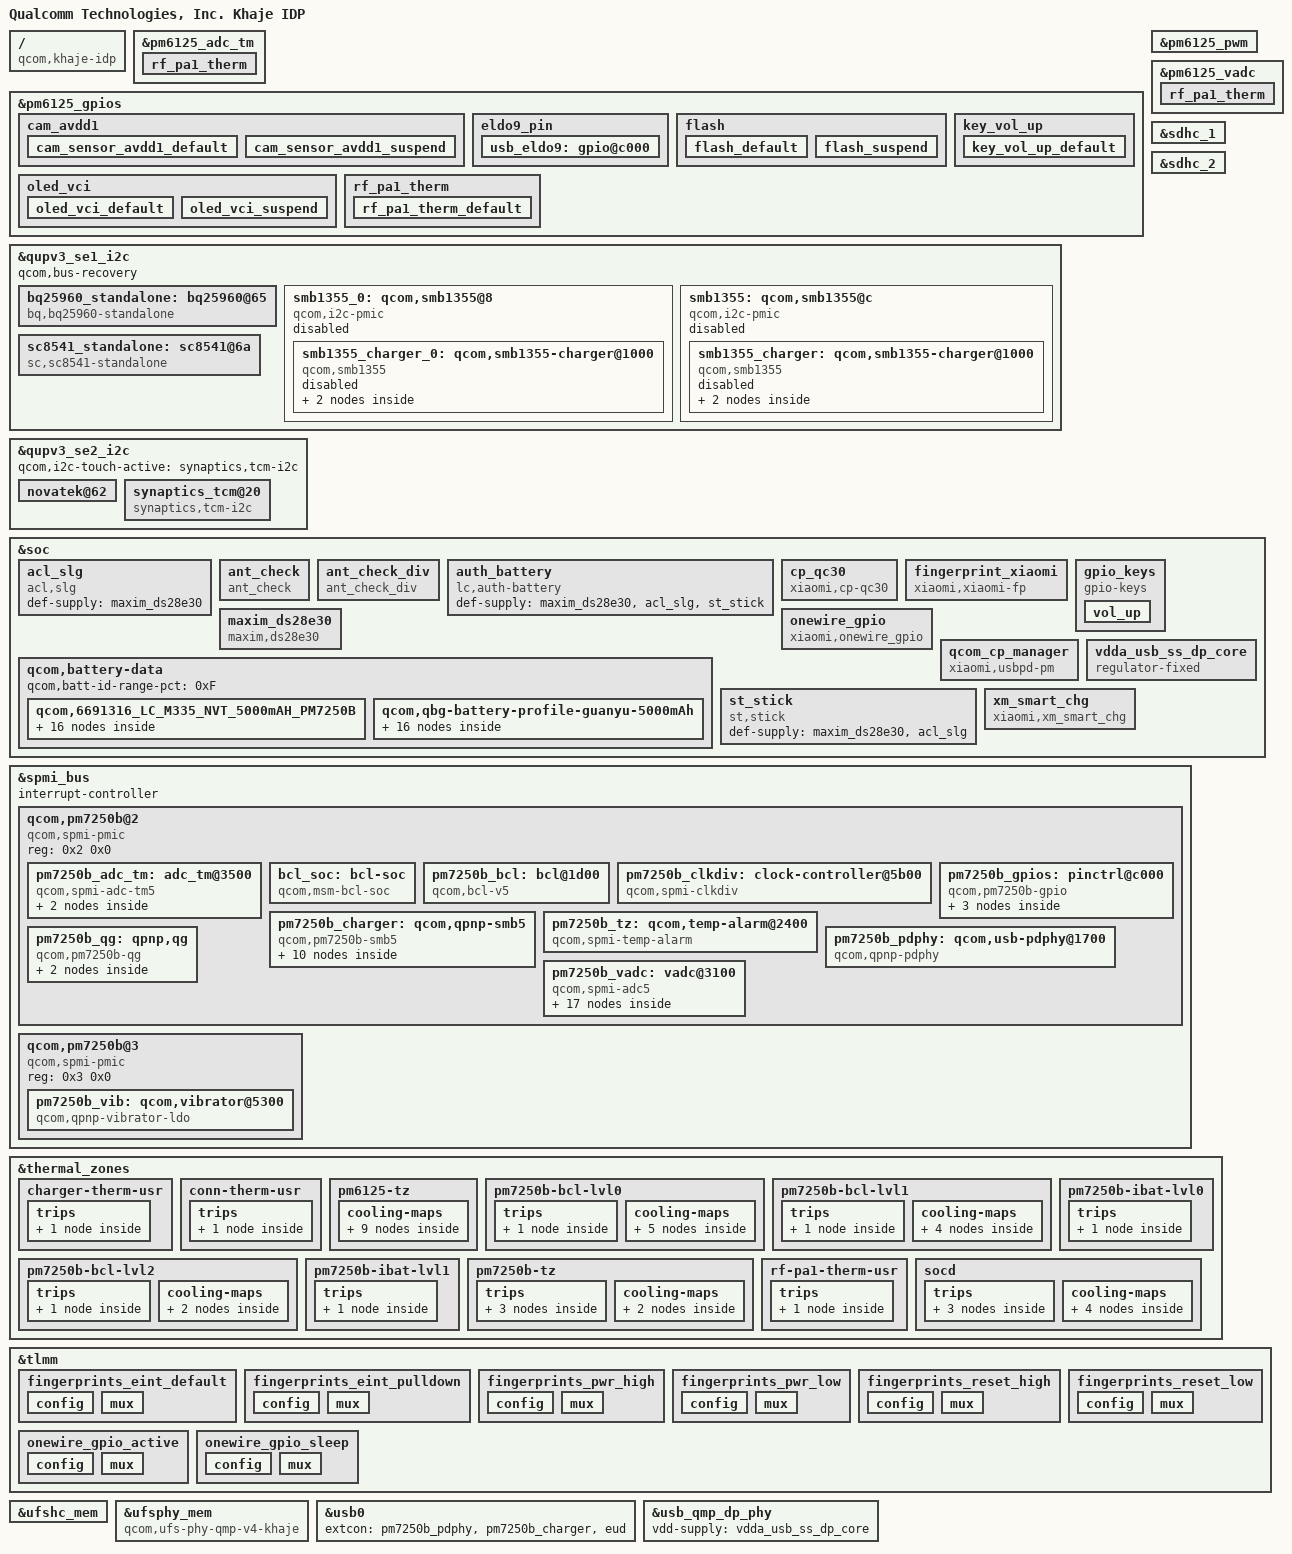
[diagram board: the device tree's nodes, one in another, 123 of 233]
/dts-v1/;

/ {
    compatible = "qcom,khaje-idp", "qcom,khaje", "qcom,idp";
    model = "Qualcomm Technologies, Inc. Khaje IDP";
    qcom,board-id = <0x10022 0x0>;
    qcom,msm-id = <0x231 0x10000>;
    qcom,pmic-id = <0x2D 0x2E 0x0 0x0>;
};

&pm6125_adc_tm {
    status = "ok";
    rf_pa1_therm {
        io-channels = <&pm6125_vadc 0x55>;
        qcom,hw-settle-time-us = <0xC8>;
        qcom,ratiometric;
        reg = <0x3>;
    };
};

&pm6125_gpios {
    cam_avdd1 {
        cam_sensor_avdd1_default: cam_sensor_avdd1_default {
            bias-disable;
            function = "normal";
            pins = "gpio2";
            power-source = <0x0>;
            qcom,drive-strength = <0x2>;
        };
        cam_sensor_avdd1_suspend: cam_sensor_avdd1_suspend {
            bias-disable;
            function = "normal";
            output-low;
            pins = "gpio2";
            power-source = <0x0>;
            qcom,drive-strength = <0x2>;
        };
    };
    eldo9_pin {
        usb_eldo9: gpio@c000 {
            bias-disable;
            function = "normal";
            output-high;
            pins = "gpio1";
            power-source = <0x0>;
            qcom,drive-strength = <0x2>;
        };
    };
    flash {
        flash_default: flash_default {
            bias-pull-up;
            function = "normal";
            output-high;
            pins = "gpio8";
            power-source = <0x1>;
            qcom,drive-strength = <0x2>;
        };
        flash_suspend: flash_suspend {
            bias-disable;
            function = "normal";
            output-low;
            pins = "gpio8";
            power-source = <0x1>;
            qcom,drive-strength = <0x2>;
        };
    };
    key_vol_up {
        key_vol_up_default: key_vol_up_default {
            bias-pull-up;
            function = "normal";
            input-enable;
            pins = "gpio5";
            power-source = <0x0>;
        };
    };
    oled_vci {
        oled_vci_default: oled_vci_default {
            bias-disable;
            function = "normal";
            input-disable;
            output-high;
            pins = "gpio9";
            power-source = <0x0>;
            qcom,drive-strength = <0x2>;
        };
        oled_vci_suspend: oled_vci_suspend {
            bias-disable;
            function = "normal";
            input-disable;
            output-low;
            pins = "gpio9";
            power-source = <0x0>;
            qcom,drive-strength = <0x2>;
        };
    };
    rf_pa1_therm {
        rf_pa1_therm_default: rf_pa1_therm_default {
            bias-high-impedance;
            pins = "gpio7";
        };
    };
};

&pm6125_pwm {
    status = "ok";
};

&pm6125_vadc {
    pinctrl-0 = <&camera_therm_default &emmc_therm_default &rf_pa1_therm_default>;
    rf_pa1_therm {
        label = "rf_pa1_therm";
        qcom,hw-settle-time = <0xC8>;
        qcom,pre-scaling = <0x1 0x1>;
        qcom,ratiometric;
        reg = <0x55>;
    };
};

&qupv3_se1_i2c {
    qcom,bus-recovery;
    status = "ok";
    bq25960_standalone: bq25960@65 {
        #io-channel-cells = <0x1>;
        bq,bq25960,chg-config-2 = <0x0>;
        bq,bq25960,fsw-set = <0x4>;
        bq,bq25960,ibat-ocp = <0x3D>;
        bq,bq25960,ibat-ocp-alm = <0x3D>;
        bq,bq25960,ibat-ocp-alm-dis = <0x1>;
        bq,bq25960,ibat-ocp-dis = <0x0>;
        bq,bq25960,ibat-sns-r = <0x0>;
        bq,bq25960,ibus-ocp = <0xD>;
        bq,bq25960,ibus-ucp = <0x0>;
        bq,bq25960,ibus-ucp-dis = <0x0>;
        bq,bq25960,ibus-ucp-fall-dg = <0x1>;
        bq,bq25960,ms = <0x0>;
        bq,bq25960,ss-timeout = <0x5>;
        bq,bq25960,tdie-alm = <0xC8>;
        bq,bq25960,tsbat-flt = <0x15>;
        bq,bq25960,tsbat-flt-dis = <0x1>;
        bq,bq25960,tsbus-flt = <0x15>;
        bq,bq25960,tsbus-flt-dis = <0x1>;
        bq,bq25960,vac1-ovp = <0x3>;
        bq,bq25960,vac1-pd-en = <0x0>;
        bq,bq25960,vac2-ovp = <0x3>;
        bq,bq25960,vac2-pd-en = <0x0>;
        bq,bq25960,vbat-ovp = <0x7F>;
        bq,bq25960,vbat-ovp-alm = <0x7A>;
        bq,bq25960,vbat-ovp-alm-dis = <0x1>;
        bq,bq25960,vbat-ovp-dis = <0x0>;
        bq,bq25960,vbus-ovp = <0x64>;
        bq,bq25960,vbus-ovp-alm = <0x64>;
        bq,bq25960,vbus-ovp-alm-dis = <0x0>;
        bq,bq25960,vbus-pd-en = <0x0>;
        bq,bq25960,vout-ovp = <0x3>;
        bq,bq25960,vout-ovp-dis = <0x0>;
        bq,bq25960,wd-timeout = <0x0>;
        bq,bq25960,wd-timeout-dis = <0x1>;
        bq25960,intr_gpio = <&tlmm 0x54 0x0>;
        charger_name = "primary_dvchg";
        compatible = "bq,bq25960-standalone";
        dep-supply = <&qupv3_se1_i2c>;
        reg = <0x65>;
        status = "ok";
    };
    smb1355_0: qcom,smb1355@8 {
        #address-cells = <0x1>;
        #interrupt-cells = <0x3>;
        #size-cells = <0x0>;
        compatible = "qcom,i2c-pmic";
        interrupt-controller;
        interrupt-parent = <&spmi_bus>;
        interrupt_names = "smb1355_0";
        interrupts = <0x0 0xD1 0x0 0x8>;
        qcom,periph-map = <0x10 0x12 0x13 0x16>;
        reg = <0x8>;
        status = "disabled";
        smb1355_charger_0: qcom,smb1355-charger@1000 {
            #address-cells = <0x1>;
            #size-cells = <0x1>;
            compatible = "qcom,smb1355";
            interrupt-parent = <&smb1355_0>;
            reg = <0x1000>;
            status = "disabled";
            qcom,chgr-misc@1600 {
                interrupt-names = "wdog-bark", "temperature-change";
                interrupts = <0x16 0x1 0x1 0x16 0x6 0x1>;
                reg = <0x1600>;
            };
            qcom,chgr@1000 {
                interrupt-names = "chg-state-change";
                interrupts = <0x10 0x1 0x1>;
                reg = <0x1000>;
            };
        };
    };
    smb1355: qcom,smb1355@c {
        #address-cells = <0x1>;
        #interrupt-cells = <0x3>;
        #size-cells = <0x0>;
        compatible = "qcom,i2c-pmic";
        interrupt-controller;
        interrupt-parent = <&spmi_bus>;
        interrupt_names = "smb1355";
        interrupts = <0x2 0xC5 0x0 0x8>;
        pinctrl-0 = <&pm7250b_smb_int_default>;
        pinctrl-names = "default";
        qcom,periph-map = <0x10 0x12 0x13 0x16>;
        reg = <0xC>;
        status = "disabled";
        smb1355_charger: qcom,smb1355-charger@1000 {
            #address-cells = <0x1>;
            #size-cells = <0x1>;
            compatible = "qcom,smb1355";
            interrupt-parent = <&smb1355>;
            qcom,hw-die-temp-mitigation;
            qcom,parallel-mode = <0x1>;
            reg = <0x1000>;
            status = "disabled";
            qcom,chgr-misc@1600 {
                interrupt-names = "wdog-bark", "temperature-change";
                interrupts = <0x16 0x1 0x1 0x16 0x6 0x1>;
                reg = <0x1600>;
            };
            qcom,chgr@1000 {
                interrupt-names = "chg-state-change";
                interrupts = <0x10 0x1 0x1>;
                reg = <0x1000>;
            };
        };
    };
    sc8541_standalone: sc8541@6a {
        #io-channel-cells = <0x1>;
        charger_name = "primary_dvchg";
        compatible = "sc,sc8541-standalone";
        dep-supply = <&qupv3_se1_i2c>;
        reg = <0x6A>;
        sc,sc8541,fsw-set = <0x4>;
        sc,sc8541,ibat-ocp = <0x51>;
        sc,sc8541,ibat-ocp-alm = <0x50>;
        sc,sc8541,ibat-ocp-alm-dis = <0x1>;
        sc,sc8541,ibat-ocp-dis = <0x0>;
        sc,sc8541,ibat-sns-r = <0x0>;
        sc,sc8541,ibus-ocp = <0xD>;
        sc,sc8541,ibus-ocp-dis = <0x0>;
        sc,sc8541,ibus-ucp-dis = <0x0>;
        sc,sc8541,ibus-ucp-fall-dg = <0x1>;
        sc,sc8541,ms = <0x0>;
        sc,sc8541,pmid2out-ovp = <0x7>;
        sc,sc8541,pmid2out-uvp = <0x7>;
        sc,sc8541,ss-timeout = <0x7>;
        sc,sc8541,tdie-alm = <0xC8>;
        sc,sc8541,tsbat-flt = <0x15>;
        sc,sc8541,tsbat-flt-dis = <0x1>;
        sc,sc8541,tsbus-flt = <0x15>;
        sc,sc8541,tsbus-flt-dis = <0x1>;
        sc,sc8541,tshut-dis = <0x1>;
        sc,sc8541,vac1-ovp = <0x3>;
        sc,sc8541,vac1-pd-en = <0x0>;
        sc,sc8541,vac2-ovp = <0x3>;
        sc,sc8541,vac2-pd-en = <0x0>;
        sc,sc8541,vbat-ovp = <0x5A>;
        sc,sc8541,vbat-ovp-alm = <0x46>;
        sc,sc8541,vbat-ovp-alm-dis = <0x1>;
        sc,sc8541,vbat-ovp-dis = <0x0>;
        sc,sc8541,vbus-in-range-dis = <0x0>;
        sc,sc8541,vbus-ovp = <0x64>;
        sc,sc8541,vbus-ovp-alm = <0x50>;
        sc,sc8541,vbus-ovp-alm-dis = <0x1>;
        sc,sc8541,vbus-pd-en = <0x0>;
        sc,sc8541,vout-ovp = <0x3>;
        sc,sc8541,vout-ovp-dis = <0x0>;
        sc,sc8541,wd-timeout = <0x0>;
        sc,sc8541,wd-timeout-dis = <0x1>;
        sc8541,intr_gpio = <&tlmm 0x54 0x0>;
        status = "ok";
    };
};

&qupv3_se2_i2c {
    qcom,i2c-touch-active = "synaptics,tcm-i2c";
    status = "okay";
    novatek@62 {
        interrupt-parent = <&tlmm>;
        interrupts = <0x50 0x2008>;
        novatek,irq-gpio = <&tlmm 0x50 0x2008>;
        novatek,reset-gpio = <&tlmm 0x56 0x0>;
        pinctrl-0 = <&ts_int_active &ts_reset_active>;
        pinctrl-1 = <&ts_int_suspend &ts_reset_suspend>;
        pinctrl-2 = <&ts_release>;
        pinctrl-names = "pmx_ts_active", "pmx_ts_suspend", "pmx_ts_release";
        reg = <0x62>;
        status = "ok";
    };
    synaptics_tcm@20 {
        compatible = "synaptics,tcm-i2c";
        interrupt-parent = <&tlmm>;
        interrupts = <0x50 0x2008>;
        pinctrl-0 = <&ts_int_active &ts_reset_active>;
        pinctrl-1 = <&ts_int_suspend &ts_reset_suspend>;
        pinctrl-2 = <&ts_release>;
        pinctrl-names = "pmx_ts_active", "pmx_ts_suspend", "pmx_ts_release";
        reg = <0x20>;
        synaptics,extend_report;
        synaptics,firmware-name = "synaptics_firmware_k.img";
        synaptics,irq-gpio = <&tlmm 0x50 0x2008>;
        synaptics,irq-on-state = <0x0>;
        synaptics,power-delay-ms = <0xC8>;
        synaptics,reset-active-ms = <0x14>;
        synaptics,reset-delay-ms = <0xC8>;
        synaptics,reset-gpio = <&tlmm 0x56 0x0>;
        synaptics,reset-on-state = <0x0>;
        synaptics,ubl-i2c-addr = <0x20>;
    };
};

&sdhc_1 {
    pinctrl-0 = <&sdc1_on>;
    pinctrl-1 = <&sdc1_off>;
    pinctrl-names = "default", "sleep";
    qcom,vdd-current-level = <0x0 0x8B290>;
    qcom,vdd-io-always-on;
    qcom,vdd-io-current-level = <0x0 0x4F588>;
    qcom,vdd-io-lpm-sup;
    qcom,vdd-io-voltage-level = <0x1B7740 0x1B7740>;
    qcom,vdd-voltage-level = <0x2D2A80 0x2D2A80>;
    status = "ok";
    vdd-io-supply = <&L11A>;
    vdd-supply = <&L24A>;
};

&sdhc_2 {
    cd-gpios = <&tlmm 0x58 0x1>;
    pinctrl-0 = <&sdc2_on>;
    pinctrl-1 = <&sdc2_off>;
    pinctrl-names = "default", "sleep";
    qcom,vdd-current-level = <0x0 0xC3500>;
    qcom,vdd-io-bias-current-level = <0x0 0x1770>;
    qcom,vdd-io-bias-voltage-level = <0x132A40 0x132A40>;
    qcom,vdd-io-current-level = <0x0 0x55F0>;
    qcom,vdd-io-voltage-level = <0x1B7740 0x2D2A80>;
    qcom,vdd-voltage-level = <0x2D2A80 0x2D2A80>;
    status = "ok";
    vdd-io-bias-supply = <&L7A>;
    vdd-io-supply = <&L5A>;
    vdd-supply = <&L22A>;
};

&soc {
    acl_slg {
        compatible = "acl,slg";
        def-supply = <&maxim_ds28e30>;
        status = "okay";
    };
    ant_check {
        ant_check_gpio = <&tlmm 0x6B 0x0>;
        compatible = "ant_check";
        interrupt-parent = <&tlmm>;
        pinctrl-0 = <&ant_check_default>;
        pinctrl-names = "default";
    };
    ant_check_div {
        ant_check_div_gpio = <&tlmm 0x19 0x0>;
        compatible = "ant_check_div";
        interrupt-parent = <&tlmm>;
        pinctrl-0 = <&ant_check_div_default>;
        pinctrl-names = "default";
    };
    auth_battery {
        #io-channel-cells = <0x1>;
        compatible = "lc,auth-battery";
        def-supply = <&maxim_ds28e30 &acl_slg &st_stick>;
        status = "okay";
    };
    cp_qc30 {
        #io-channel-cells = <0x1>;
        compatible = "xiaomi,cp-qc30";
        io-channel-names = "real_type", "hvdcp3_type", "cp_input_suspend", "battery_charging_enabled", "battery_dp_dm", "battery_charging_limited", "present", "charging_enabled", "status", "sc_battery_present", "sc_vbus_present", "sc_battery_voltage", "sc_battery_current", "sc_battery_temperature", "sc_bus_voltage", "sc_bus_current", "sc_bus_temperature", "sc_die_temperature", "sc_alarm_status", "sc_fault_status", "sc_vbus_error_status", "sc_chip_vendor", "sc_chip_id", "sc_set_bus_protection", "bq_present", "bq_charging_enabled", "bq_status", "bq_battery_present", "bq_vbus_present", "bq_battery_voltage", "bq_battery_current", "bq_battery_temperature", "bq_bus_voltage", "bq_bus_current", "bq_bus_temperature", "bq_die_temperature", "bq_alarm_status", "bq_fault_status", "bq_vbus_error_status", "bq_set_bus_protection";
        io-channels = <&pm7250b_charger 0xA &pm7250b_charger 0xEA &pm7250b_charger 0xB2 &pm7250b_charger 0xB3 &pm7250b_charger 0x3E &pm7250b_charger 0xBF &sc8541_standalone 0x90 &sc8541_standalone 0x76 &sc8541_standalone 0x8F &sc8541_standalone 0x92 &sc8541_standalone 0x93 &sc8541_standalone 0x94 &sc8541_standalone 0x95 &sc8541_standalone 0x96 &sc8541_standalone 0x97 &sc8541_standalone 0x98 &sc8541_standalone 0x99 &sc8541_standalone 0x9A &sc8541_standalone 0x9B &sc8541_standalone 0x91 &sc8541_standalone 0x9C &sc8541_standalone 0x9D &sc8541_standalone 0xAB &sc8541_standalone 0xBC &bq25960_standalone 0x90 &bq25960_standalone 0x76 &bq25960_standalone 0x8F &bq25960_standalone 0x92 &bq25960_standalone 0x93 &bq25960_standalone 0x94 &bq25960_standalone 0x95 &bq25960_standalone 0x96 &bq25960_standalone 0x97 &bq25960_standalone 0x98 &bq25960_standalone 0x99 &bq25960_standalone 0x9A &bq25960_standalone 0x9B &bq25960_standalone 0x91 &bq25960_standalone 0x9C &bq25960_standalone 0xBC>;
        mi,qc3-bat-curr-max = <0x1518>;
        mi,qc3-bat-volt-max = <0x1162>;
        mi,qc3-bus-curr-max = <0x834>;
        mi,qc3-bus-volt-max = <0x2EE0>;
        mi,qc3-ffc-bat-volt-max = <0x1162>;
        status = "ok";
    };
    fingerprint_xiaomi {
        compatible = "xiaomi,xiaomi-fp";
        fp-gpio-pwr = <&tlmm 0x41 0x0>;
        netlink-event = <0x1D>;
        pinctrl-0 = <&fingerprints_reset_high>;
        pinctrl-1 = <&fingerprints_reset_low>;
        pinctrl-2 = <&fingerprints_eint_default>;
        pinctrl-3 = <&fingerprints_eint_pulldown>;
        pinctrl-4 = <&fingerprints_pwr_high>;
        pinctrl-5 = <&fingerprints_pwr_low>;
        pinctrl-names = "reset_high", "reset_low", "eint_default", "eint_pulldown", "pwr_high", "pwr_low";
        status = "okay";
        vfp-supply = <&pm6125_l9>;
        xiaomi,gpio_irq = <&tlmm 0x53 0x0>;
    };
    gpio_keys {
        compatible = "gpio-keys";
        label = "gpio-keys";
        pinctrl-0 = <&key_vol_up_default>;
        pinctrl-names = "default";
        vol_up {
            debounce-interval = <0xF>;
            gpio-key,wakeup;
            gpios = <&pm6125_gpios 0x5 0x1>;
            label = "volume_up";
            linux,can-disable;
            linux,code = <0x73>;
            linux,input-type = <0x1>;
        };
    };
    maxim_ds28e30 {
        #io-channel-cells = <0x1>;
        compatible = "maxim,ds28e30";
        label = "max_ds28e30";
        maxim,version = <0x1>;
        status = "ok";
    };
    onewire_gpio {
        compatible = "xiaomi,onewire_gpio";
        label = "xm_onewire";
        onewire-gpio = <&tlmm 0x42 0x0>;
        pinctrl-0 = <&onewire_gpio_active>;
        pinctrl-1 = <&onewire_gpio_sleep>;
        pinctrl-names = "default", "sleep";
        status = "ok";
        xiaomi,gpio_number = <0x42>;
        xiaomi,version = <0x1>;
    };
    qcom,battery-data {
        qcom,batt-id-range-pct = <0xF>;
        qcom,6691316_LC_M335_NVT_5000mAH_PM7250B {
            qcom,batt-id-kohm = <0x64>;
            qcom,battery-beta = <0xD34>;
            qcom,battery-therm-kohm = <0xA>;
            qcom,battery-type = "qbg-battery-profile-nvt-5000mAh";
            qcom,fastchg-current-ma = <0x1770>;
            qcom,fg-cc-cv-threshold-uv = <0x44AA20>;
            qcom,jeita-fcc-ranges = <0xFFFFFF9C 0x0 0x61A80 0x0 0x32 0xCF850 0x32 0x64 0x231860 0x64 0x96 0x387520 0x96 0x15E 0x5B8D80 0x15E 0x1E0 0x5B8D80 0x1E0 0x230 0x231860>;
            qcom,jeita-fv-ranges = <0xFFFFFF9C 0x0 0x440DE0 0x0 0x32 0x445C00 0x32 0x64 0x445C00 0x64 0x96 0x445C00 0x96 0x15E 0x43E6D0 0x15E 0x1E0 0x43E6D0 0x1E0 0x230 0x3E8FA0>;
            qcom,jeita-hard-thresholds = <0x43D5 0xB9B>;
            qcom,jeita-soft-fcc-ua = <0x5265C0 0x2625A0>;
            qcom,jeita-soft-fv-uv = <0x445C00 0x3E8FA0>;
            qcom,jeita-soft-hys-thresholds = <0x225F 0xFDC>;
            qcom,jeita-soft-thresholds = <0x2554 0xE8D>;
            qcom,max-voltage-uv = <0x44AA20>;
            qcom,qg-batt-profile-ver = <0x64>;
            qcom,step-chg-ranges = <0x36EE80 0x40D990 0x5B8D80 0x40D991 0x445C00 0x5265C0 0x445C01 0x44AA20 0x3BD080>;
            qcom,taper-fcc;
            qcom,vbat-avg-based-step-chg;
            qcom,fcc1-temp-lut {
                qcom,lut-col-legend = <0x0 0xA 0x19 0x28 0x32>;
                qcom,lut-data = <0x1356 0x13DC 0x1415 0x1432 0x143C>;
            };
            qcom,fcc2-temp-lut {
                qcom,lut-col-legend = <0xFFFFFFF6 0x0 0xA 0x19 0x28 0x32>;
                qcom,lut-data = <0x13B8 0x13B8 0x140E 0x142A 0x141B 0x1412>;
            };
            qcom,pc-temp-v1-lut {
                qcom,lut-col-legend = <0x0 0xA 0x19 0x28 0x32>;
                qcom,lut-data = <0xAECE 0xAF67 0xAFA6 0xAFC5 0xAFC9 0xADB2 0xADE1 0xAE0C 0xAE1D 0xAE22 0xACB0 0xACE7 0xACEB 0xACE9 0xACF2 0xABD3 0xAC14 0xAC0C 0xABFD 0xAC03 0xAB06 0xAB38 0xAB33 0xAB23 0xAB26 0xAA2B 0xAA61 0xAA57 0xAA47 0xAA48 0xA944 0xA980 0xA978 0xA96E 0xA96E 0xA856 0xA890 0xA88C 0xA886 0xA889 0xA760 0xA797 0xA794 0xA790 0xA799 0xA665 0xA69D 0xA69A 0xA696 0xA6A2 0xA56D 0xA59F 0xA59D 0xA59B 0xA5A8 0xA478 0xA4A4 0xA4A0 0xA4A0 0xA4AD 0xA386 0xA3AC 0xA3A5 0xA3A6 0xA3B5 0xA29D 0xA2B9 0xA2AD 0xA2AE 0xA2BF 0xA1BB 0xA1CF 0xA1BF 0xA1BD 0xA1CF 0xA0DE 0xA0EB 0xA0D7 0xA0D4 0xA0E4 0xA007 0xA00F 0x9FF7 0x9FF1 0x9FFF 0x9F37 0x9F3B 0x9F1F 0x9F17 0x9F23 0x9E70 0x9E6F 0x9E4F 0x9E44 0x9E4F 0x9DB0 0x9DB1 0x9D8B 0x9D7B 0x9D84 0x9CF5 0x9CFA 0x9CD5 0x9CC3 0x9CCA 0x9C45 0x9C34 0x9C0F 0x9BFF 0x9C07 0x9B8C 0x9B5C 0x9B1E 0x9B17 0x9B24 0x9A9C 0x9A7F 0x9A2B 0x9A25 0x9A35 0x9983 0x9997 0x9961 0x9957 0x9966 0x98B3 0x98B6 0x98B0 0x989E 0x98AB 0x9829 0x981F 0x981D 0x9803 0x980C 0x97BB 0x97BA 0x97A3 0x9783 0x9787 0x975D 0x975B 0x9736 0x9713 0x9713 0x970C 0x96F5 0x96CE 0x96A9 0x96A5 0x96C1 0x9694 0x966E 0x9649 0x9640 0x9676 0x963F 0x961A 0x95EF 0x95E4 0x9630 0x95F5 0x95D0 0x959D 0x9591 0x95EE 0x95B2 0x958C 0x9552 0x9543 0x95B1 0x9578 0x954E 0x9510 0x94FC 0x957A 0x9543 0x9515 0x94D3 0x94B9 0x954E 0x9512 0x94DD 0x9491 0x946C 0x9523 0x94E5 0x94AA 0x944C 0x9416 0x94EC 0x94AA 0x946B 0x93FE 0x93BA 0x94A8 0x9453 0x9413 0x93A2 0x935B 0x9454 0x93E8 0x93A8 0x9339 0x92F2 0x93DA 0x9370 0x932F 0x92BF 0x9276 0x9349 0x92E1 0x92A1 0x9230 0x91E5 0x92A6 0x9233 0x91F6 0x918C 0x9146 0x9209 0x918A 0x9155 0x90F7 0x90B7 0x9172 0x9112 0x90EF 0x909F 0x9063 0x9135 0x90ED 0x90D3 0x9088 0x904D 0x9109 0x90D5 0x90BE 0x9079 0x903D 0x90E0 0x90BC 0x90A5 0x9061 0x9023 0x90B7 0x907A 0x9056 0x8FDE 0x8F8A 0x907D 0x8F62 0x8F32 0x8E81 0x8E25 0x8F9E 0x8D7F 0x8D64 0x8C99 0x8C3D 0x8DBB 0x8AFD 0x8B08 0x8A22 0x89C4 0x8AAF 0x876A 0x87CD 0x86B7 0x8660 0x8047 0x8176 0x82C3 0x814E 0x80F7 0x7530 0x7530 0x7530 0x7530 0x7530>;
                qcom,lut-row-legend = <0x2710 0x2648 0x2580 0x24B8 0x23F0 0x2328 0x2260 0x2198 0x20D0 0x2008 0x1F40 0x1E78 0x1DB0 0x1CE8 0x1C20 0x1B58 0x1A90 0x19C8 0x1900 0x1838 0x1770 0x16A8 0x15E0 0x1518 0x1450 0x1388 0x12C0 0x11F8 0x1130 0x1068 0xFA0 0xED8 0xE10 0xD48 0xC80 0xBB8 0xAF0 0xA28 0x960 0x898 0x7D0 0x708 0x640 0x578 0x4B0 0x3E8 0x384 0x320 0x2BC 0x258 0x1F4 0x190 0x12C 0xC8 0x64 0x0>;
            };
            qcom,pc-temp-v2-lut {
                qcom,lut-col-legend = <0xFFFFFFF6 0x0 0xA 0x19 0x28 0x32>;
                qcom,lut-data = <0xAFCD 0xAFBE 0xAFAA 0xAF7D 0xAF64 0xAF50 0xADD1 0xADEE 0xADEE 0xADF3 0xADD3 0xADC1 0xAC2E 0xAC6F 0xAC7F 0xACA5 0xAC7E 0xAC6E 0xAAFF 0xAB59 0xAB72 0xABA2 0xAB72 0xAB61 0xAA20 0xAA8E 0xAAA9 0xAAD6 0xAA9F 0xAA8D 0xA949 0xA9C4 0xA9DD 0xAA07 0xA9CA 0xA9B7 0xA85F 0xA8E0 0xA8F9 0xA925 0xA8E5 0xA8D2 0xA773 0xA7F4 0xA80D 0xA83C 0xA7FA 0xA7E9 0xA681 0xA702 0xA719 0xA749 0xA707 0xA6F7 0xA587 0xA608 0xA61B 0xA64C 0xA60B 0xA5FC 0xA48E 0xA50F 0xA51D 0xA54F 0xA510 0xA502 0xA395 0xA416 0xA420 0xA452 0xA414 0xA408 0xA29F 0xA31E 0xA326 0xA356 0xA31B 0xA310 0xA1BA 0xA22C 0xA231 0xA25F 0xA227 0xA21D 0xA0E2 0xA13E 0xA142 0xA16C 0xA137 0xA12E 0xA005 0xA05A 0xA059 0xA081 0xA04F 0xA046 0x9F20 0x9F86 0x9F74 0x9F9D 0x9F6E 0x9F64 0x9E31 0x9EB7 0x9E98 0x9EC0 0x9E94 0x9E8B 0x9D2E 0x9DE5 0x9DCC 0x9DEF 0x9DC4 0x9DBD 0x9C18 0x9D10 0x9D03 0x9D20 0x9CF8 0x9CF5 0x9B12 0x9C26 0x9C1D 0x9C4B 0x9C30 0x9C2F 0x9A21 0x9B0B 0x9B15 0x9B72 0x9B6B 0x9B6D 0x993F 0x99F2 0x9A19 0x9A8D 0x9A97 0x9A9C 0x9865 0x9914 0x992E 0x9986 0x9991 0x999A 0x9796 0x9852 0x9859 0x9893 0x9897 0x989F 0x96E6 0x97A8 0x97AC 0x97E6 0x97EA 0x97F2 0x9650 0x9712 0x971C 0x975A 0x9762 0x976B 0x95D1 0x9689 0x9699 0x96DA 0x96E6 0x96EF 0x956D 0x960A 0x9621 0x9663 0x9674 0x967C 0x9519 0x9596 0x95B3 0x95F7 0x960B 0x9612 0x94CE 0x952B 0x954E 0x9596 0x95AC 0x95B1 0x948A 0x94C5 0x94F0 0x953D 0x9554 0x9556 0x944B 0x946D 0x949A 0x94E9 0x9503 0x9503 0x940D 0x942C 0x944A 0x9499 0x94B9 0x94BA 0x93D1 0x93F8 0x9401 0x9449 0x946A 0x9469 0x9390 0x93C6 0x93C1 0x93FB 0x940A 0x93FB 0x934A 0x9397 0x9385 0x93AB 0x93A2 0x937B 0x92FF 0x9365 0x9345 0x934F 0x9337 0x9305 0x92AC 0x9326 0x92FF 0x92EA 0x92C8 0x9295 0x9251 0x92DC 0x92AF 0x9287 0x925E 0x922A 0x91EC 0x927C 0x9249 0x922B 0x9204 0x91CD 0x917A 0x91F8 0x91D1 0x91C0 0x919E 0x9168 0x9100 0x9166 0x9142 0x913A 0x911C 0x90E5 0x9081 0x90C7 0x909D 0x909D 0x9084 0x904A 0x9015 0x9033 0x9012 0x9028 0x9015 0x8FE1 0x8FAC 0x8FC1 0x8FC5 0x9006 0x8FF9 0x8FC5 0x8F79 0x8F8E 0x8F9E 0x8FEF 0x8FE5 0x8FB1 0x8F42 0x8F5F 0x8F6B 0x8FCD 0x8FCD 0x8F97 0x8F34 0x8F2B 0x8F26 0x8F7B 0x8F97 0x8F5A 0x8ED3 0x8EED 0x8E68 0x8E77 0x8EB3 0x8E6D 0x9035 0x8E84 0x8CE0 0x8CA0 0x8D00 0x8CB1 0x8EED 0x8DAA 0x8A8F 0x8A3C 0x8ACC 0x8A7E 0x9123 0x8DB4 0x8781 0x870B 0x87D5 0x878C 0x7A6A 0x8BFF 0x84A3 0x8247 0x83A5 0x8377 0x7638 0x77C9 0x7EF6 0x7BE9 0x7D77 0x7D66 0x7244 0x728C 0x6DD8 0x71D6 0x6D9A 0x6DA1>;
                qcom,lut-row-legend = <0x2710 0x2648 0x2580 0x24B8 0x23F0 0x2328 0x2260 0x2198 0x20D0 0x2008 0x1F40 0x1E78 0x1DB0 0x1CE8 0x1C20 0x1B58 0x1A90 0x19C8 0x1900 0x1838 0x1770 0x16A8 0x15E0 0x1518 0x1450 0x1388 0x12C0 0x11F8 0x1130 0x1068 0xFA0 0xED8 0xE10 0xD48 0xC80 0xBB8 0xAF0 0xA28 0x960 0x898 0x7D0 0x708 0x640 0x578 0x4B0 0x3E8 0x384 0x320 0x2BC 0x258 0x1F4 0x190 0x12C 0xC8 0x64 0x0>;
            };
            qcom,pc-temp-y1-lut {
                qcom,lut-col-legend = <0xFFFFFFF6 0x0 0xA 0x19 0x28 0x32>;
                qcom,lut-data = <0x160E 0x14C8 0x13B8 0x12BA 0x124C 0x122D 0x162D 0x14C1 0x13B8 0x12BD 0x124C 0x122F 0x1644 0x14B9 0x13B6 0x12BE 0x124B 0x1232 0x1653 0x14B3 0x13B3 0x12BD 0x124B 0x1234 0x165C 0x14AF 0x13B0 0x12BC 0x124B 0x1236 0x165E 0x14AE 0x13AF 0x12BB 0x124B 0x1238 0x1656 0x14AF 0x13AF 0x12B9 0x124B 0x123A 0x164A 0x14B2 0x13AE 0x12B7 0x124B 0x123C 0x164B 0x14B4 0x13AE 0x12B7 0x124C 0x123E 0x1658 0x14B5 0x13AD 0x12BA 0x124D 0x1240 0x1665 0x14B7 0x13AD 0x12BB 0x124F 0x1241 0x1673 0x14BA 0x13AF 0x12BB 0x1251 0x1244 0x167F 0x14BE 0x13B2 0x12BB 0x1252 0x1246 0x167A 0x14C4 0x13B1 0x12BC 0x1254 0x1248 0x1665 0x14CB 0x13B1 0x12BD 0x1255 0x124A 0x165B 0x14D0 0x13B2 0x12BF 0x1257 0x124C 0x1669 0x14D3 0x13B6 0x12C2 0x125A 0x124E 0x1679 0x14D6 0x13B8 0x12C5 0x125C 0x1251 0x167A 0x14D4 0x13B6 0x12C7 0x125E 0x1252 0x1679 0x14CD 0x13B2 0x12C9 0x125F 0x1253 0x1678 0x14CB 0x13B3 0x12CA 0x1261 0x1255 0x167A 0x14CE 0x13B8 0x12CC 0x1263 0x1256 0x167C 0x14D1 0x13BC 0x12CE 0x1265 0x1257 0x1681 0x14D2 0x13C1 0x12D1 0x1266 0x1259 0x168D 0x14D0 0x13C5 0x12D4 0x1268 0x125C 0x1691 0x14D0 0x13C6 0x12D7 0x126A 0x125D 0x168F 0x14D3 0x13C6 0x12DA 0x126B 0x125F 0x168C 0x14D6 0x13C6 0x12DC 0x126D 0x1260 0x168C 0x14D9 0x13C8 0x12DF 0x126E 0x1261 0x168E 0x14DD 0x13C9 0x12E1 0x1270 0x1262 0x168F 0x14E0 0x13CD 0x12E5 0x1272 0x1263 0x1691 0x14E6 0x13D5 0x12E8 0x1274 0x1265 0x1694 0x14EA 0x13D9 0x12E9 0x1276 0x1266 0x1690 0x14EA 0x13D9 0x12EB 0x1278 0x1268 0x1689 0x14E9 0x13D9 0x12EC 0x127A 0x1269 0x1686 0x14E9 0x13DA 0x12ED 0x127B 0x126A 0x1682 0x14EE 0x13DC 0x12EF 0x127C 0x126B 0x167F 0x14F2 0x13DD 0x12F1 0x127E 0x126D 0x1683 0x14ED 0x13DE 0x12F4 0x127F 0x126E 0x168A 0x14E4 0x13DF 0x12F6 0x1281 0x126F 0x1694 0x14E1 0x13DE 0x12F8 0x1282 0x1270 0x16AA 0x14E1 0x13DE 0x12FA 0x1283 0x1270 0x16A9 0x14E3 0x13E0 0x12FC 0x1285 0x1272 0x168A 0x14EB 0x13E4 0x12FC 0x1285 0x1273 0x1690 0x14F3 0x13E4 0x1301 0x1286 0x1274 0x168A 0x14EB 0x13FA 0x1303 0x1288 0x1275 0x1694 0x1500 0x13F6 0x12FF 0x128A 0x1276 0x16A2 0x14FA 0x13FB 0x1305 0x1289 0x1275 0x16A5 0x1500 0x13F1 0x1306 0x1289 0x1276 0x16D0 0x14F0 0x13F2 0x1305 0x128A 0x1277 0x16CF 0x14EF 0x13F4 0x130D 0x128B 0x1277 0x1721 0x1506 0x13F4 0x130E 0x128E 0x127A 0x175E 0x1534 0x1411 0x1317 0x1291 0x127C 0x17BD 0x1577 0x1448 0x1323 0x1295 0x1280 0x17BD 0x1577 0x1448 0x1323 0x1295 0x1280 0x17BD 0x1577 0x1448 0x1323 0x1295 0x1280>;
                qcom,lut-row-legend = <0x2710 0x2648 0x2580 0x24B8 0x23F0 0x2328 0x2260 0x2198 0x20D0 0x2008 0x1F40 0x1E78 0x1DB0 0x1CE8 0x1C20 0x1B58 0x1A90 0x19C8 0x1900 0x1838 0x1770 0x16A8 0x15E0 0x1518 0x1450 0x1388 0x12C0 0x11F8 0x1130 0x1068 0xFA0 0xED8 0xE10 0xD48 0xC80 0xBB8 0xAF0 0xA28 0x960 0x898 0x7D0 0x708 0x640 0x578 0x4B0 0x3E8 0x384 0x320 0x2BC 0x258 0x1F4 0x190 0x12C 0xC8 0x64 0x0>;
            };
            qcom,pc-temp-y2-lut {
                qcom,lut-col-legend = <0xFFFFFFF6 0x0 0xA 0x19 0x28 0x32>;
                qcom,lut-data = <0x28C5 0x2AD4 0x2C9A 0x2D7E 0x2EC2 0x307C 0x2909 0x2B15 0x2C8C 0x2D7F 0x2EE1 0x306B 0x2957 0x2B3E 0x2C7A 0x2D75 0x2EE9 0x3045 0x29A4 0x2B54 0x2C65 0x2D63 0x2EE0 0x3017 0x29E3 0x2B5D 0x2C4E 0x2D4C 0x2ECB 0x2FF2 0x2A0A 0x2B5F 0x2C37 0x2D35 0x2EAF 0x2FE3 0x2A1D 0x2B4F 0x2C1D 0x2D18 0x2E79 0x2FC0 0x2A2A 0x2B34 0x2C01 0x2CF7 0x2E47 0x2F90 0x2A33 0x2B20 0x2BE5 0x2CCC 0x2E35 0x2F5C 0x2A39 0x2B0E 0x2BC7 0x2C99 0x2E28 0x2F07 0x2A40 0x2B06 0x2BB2 0x2C8D 0x2E24 0x2EEC 0x2A48 0x2B09 0x2BA2 0x2CAC 0x2E18 0x2F1B 0x2A54 0x2B0F 0x2B99 0x2CC6 0x2E0F 0x2F45 0x2A6F 0x2B1C 0x2BA1 0x2CB9 0x2E12 0x2F34 0x2AA7 0x2B3E 0x2BBB 0x2CA1 0x2E1A 0x2F0E 0x2AD9 0x2B65 0x2BDA 0x2CA0 0x2E24 0x2F06 0x2B02 0x2B8F 0x2C05 0x2CBD 0x2E32 0x2F1A 0x2B20 0x2BBD 0x2C37 0x2CE8 0x2E38 0x2F29 0x2B27 0x2BEE 0x2C77 0x2D34 0x2E1A 0x2F3B 0x2B25 0x2C23 0x2CB3 0x2D94 0x2DF2 0x2F5D 0x2B1E 0x2C34 0x2CB9 0x2DE6 0x2E3B 0x2F8B 0x2B12 0x2C08 0x2CA5 0x2E34 0x2F7E 0x2FE8 0x2AF9 0x2BD8 0x2C9A 0x2E49 0x301B 0x304A 0x2A0A 0x2BE4 0x2CA6 0x2DF0 0x2F98 0x30B2 0x27A5 0x2C0E 0x2CBC 0x2D96 0x2F03 0x3108 0x2681 0x2C20 0x2CD1 0x2D94 0x2F06 0x3118 0x2649 0x2C22 0x2CE9 0x2D9B 0x2F31 0x3103 0x2628 0x2C23 0x2CF9 0x2DA7 0x2F57 0x310E 0x260E 0x2C24 0x2D02 0x2DC9 0x2F7D 0x3148 0x25FA 0x2C28 0x2D09 0x2DEE 0x2FA3 0x317B 0x25F0 0x2C2B 0x2D12 0x2E08 0x2FD0 0x3177 0x25EA 0x2C2A 0x2D21 0x2E1D 0x3000 0x315F 0x25E5 0x2C23 0x2D24 0x2E22 0x300B 0x317D 0x25E0 0x2C10 0x2D19 0x2E1D 0x2FED 0x31B8 0x25DB 0x2BEA 0x2D0D 0x2E1A 0x2FD7 0x31D7 0x25D6 0x2BC3 0x2CFC 0x2E2F 0x2FEA 0x31A9 0x25D2 0x2B9C 0x2CE2 0x2E4E 0x3006 0x315C 0x25CE 0x2B6C 0x2CD1 0x2E44 0x2FFD 0x3154 0x25CB 0x2B30 0x2CC4 0x2E1D 0x2FE3 0x3186 0x25C8 0x2AD8 0x2CB0 0x2E11 0x2FD4 0x31A2 0x25C6 0x29FA 0x2C68 0x2E22 0x2FCF 0x3164 0x25C5 0x2752 0x2C08 0x2E23 0x2FC0 0x310D 0x25C3 0x2639 0x2BB2 0x2DE7 0x2F71 0x30A0 0x25C2 0x25FF 0x2B1B 0x2DFD 0x2FA9 0x3105 0x25C0 0x25E0 0x2AAF 0x2D91 0x2F60 0x3096 0x25BF 0x25D4 0x2A19 0x2D94 0x2F36 0x3015 0x25C2 0x25CD 0x291D 0x2D8E 0x2F09 0x2F86 0x25CF 0x25C8 0x2831 0x2DA1 0x2EC3 0x2F2C 0x25F2 0x25C3 0x27AE 0x2D81 0x2EB0 0x2F61 0x261F 0x25BF 0x2658 0x2D4F 0x2E92 0x2F64 0x25B8 0x25BD 0x25E2 0x2CDD 0x2E4F 0x2EFE 0x25B2 0x25E7 0x25C2 0x2C58 0x2DFD 0x2E92 0x25B0 0x25B9 0x265B 0x2BF3 0x2D73 0x2E2C 0x25B2 0x25B2 0x25F9 0x2C04 0x2CFC 0x2D32 0x25B2 0x25B2 0x25F9 0x2C04 0x2CFC 0x2D32 0x25B2 0x25B2 0x25F9 0x2C04 0x2CFC 0x2D32>;
                qcom,lut-row-legend = <0x2710 0x2648 0x2580 0x24B8 0x23F0 0x2328 0x2260 0x2198 0x20D0 0x2008 0x1F40 0x1E78 0x1DB0 0x1CE8 0x1C20 0x1B58 0x1A90 0x19C8 0x1900 0x1838 0x1770 0x16A8 0x15E0 0x1518 0x1450 0x1388 0x12C0 0x11F8 0x1130 0x1068 0xFA0 0xED8 0xE10 0xD48 0xC80 0xBB8 0xAF0 0xA28 0x960 0x898 0x7D0 0x708 0x640 0x578 0x4B0 0x3E8 0x384 0x320 0x2BC 0x258 0x1F4 0x190 0x12C 0xC8 0x64 0x0>;
            };
            qcom,pc-temp-y3-lut {
                qcom,lut-col-legend = <0xFFFFFFF6 0x0 0xA 0x19 0x28 0x32>;
                qcom,lut-data = <0x3464 0x3412 0x33F5 0x33E0 0x33D7 0x33D3 0x3464 0x3414 0x33F6 0x33E0 0x33D6 0x33D3 0x3464 0x3418 0x33F8 0x33E1 0x33D6 0x33D3 0x3465 0x341B 0x33FA 0x33E1 0x33D6 0x33D3 0x3466 0x341E 0x33FC 0x33E2 0x33D6 0x33D3 0x3467 0x3420 0x33FD 0x33E2 0x33D6 0x33D3 0x3468 0x3420 0x33FD 0x33E3 0x33D6 0x33D4 0x3469 0x3420 0x33FE 0x33E3 0x33D7 0x33D5 0x3469 0x3421 0x33FE 0x33E3 0x33D7 0x33D5 0x3468 0x3422 0x33FE 0x33E3 0x33D7 0x33D5 0x3467 0x3423 0x33FE 0x33E4 0x33D8 0x33D5 0x3464 0x3423 0x33FE 0x33E4 0x33D8 0x33D5 0x3460 0x3423 0x33FE 0x33E5 0x33D8 0x33D6 0x345F 0x3422 0x33FF 0x33E4 0x33D9 0x33D6 0x345E 0x3420 0x3400 0x33E4 0x33D9 0x33D6 0x345D 0x341F 0x3400 0x33E4 0x33D9 0x33D6 0x3459 0x341D 0x33FF 0x33E6 0x33DB 0x33D6 0x3454 0x341C 0x33FE 0x33E8 0x33DC 0x33D6 0x344E 0x341B 0x33FD 0x33E9 0x33DC 0x33D7 0x3446 0x341B 0x33FC 0x33EA 0x33DB 0x33D8 0x3440 0x341A 0x33FB 0x33EA 0x33DB 0x33D9 0x343A 0x3414 0x33F9 0x33E9 0x33DD 0x33DA 0x3434 0x340D 0x33F7 0x33E7 0x33DE 0x33DA 0x342C 0x340A 0x33F4 0x33E3 0x33DA 0x33D7 0x3421 0x3408 0x33F2 0x33E0 0x33D6 0x33D3 0x341D 0x3407 0x33F1 0x33E0 0x33D6 0x33D3 0x341F 0x3405 0x33F0 0x33E0 0x33D6 0x33D3 0x3422 0x3404 0x33F0 0x33E0 0x33D5 0x33D3 0x3422 0x3403 0x33EF 0x33DF 0x33D5 0x33D3 0x3420 0x3402 0x33EF 0x33DF 0x33D5 0x33D3 0x3421 0x3400 0x33EF 0x33DF 0x33D6 0x33D3 0x342C 0x33FC 0x33EE 0x33E0 0x33D6 0x33D2 0x343A 0x33F9 0x33EE 0x33E0 0x33D6 0x33D2 0x3448 0x33FA 0x33EE 0x33E0 0x33D6 0x33D3 0x3458 0x33FD 0x33ED 0x33E0 0x33D6 0x33D3 0x346A 0x3400 0x33ED 0x33E0 0x33D6 0x33D3 0x3481 0x3402 0x33ED 0x33DF 0x33D6 0x33D2 0x349E 0x3405 0x33EE 0x33DF 0x33D6 0x33D2 0x34C2 0x3407 0x33EE 0x33DE 0x33D5 0x33D2 0x34F0 0x340A 0x33EF 0x33DE 0x33D5 0x33D2 0x3524 0x340E 0x33F0 0x33DE 0x33D5 0x33D3 0x3562 0x3414 0x33F2 0x33DE 0x33D6 0x33D4 0x35AF 0x341D 0x33F4 0x33DE 0x33D6 0x33D4 0x3616 0x342C 0x33F5 0x33DE 0x33D5 0x33D4 0x36AC 0x3445 0x33F5 0x33DC 0x33D5 0x33D3 0x3770 0x3469 0x33FD 0x33DF 0x33D6 0x33D4 0x383F 0x3491 0x3400 0x33E1 0x33D7 0x33D6 0x393B 0x34D8 0x3406 0x33E4 0x33DB 0x33D7 0x3A1A 0x3547 0x3419 0x33E7 0x33DC 0x33D8 0x3BDB 0x3609 0x3437 0x33E6 0x33DB 0x33D7 0x3970 0x37B3 0x347E 0x33E6 0x33D9 0x33D6 0x3CF7 0x39EF 0x35EF 0x33E8 0x33DB 0x33D7 0x4907 0x3737 0x399F 0x33ED 0x33DB 0x33D8 0x8142 0x3B50 0x36B6 0x3404 0x33DE 0x33DA 0x8142 0x3B50 0x36B6 0x3404 0x33DE 0x33DA 0x8142 0x3B50 0x36B6 0x3404 0x33DE 0x33DA>;
                qcom,lut-row-legend = <0x2710 0x2648 0x2580 0x24B8 0x23F0 0x2328 0x2260 0x2198 0x20D0 0x2008 0x1F40 0x1E78 0x1DB0 0x1CE8 0x1C20 0x1B58 0x1A90 0x19C8 0x1900 0x1838 0x1770 0x16A8 0x15E0 0x1518 0x1450 0x1388 0x12C0 0x11F8 0x1130 0x1068 0xFA0 0xED8 0xE10 0xD48 0xC80 0xBB8 0xAF0 0xA28 0x960 0x898 0x7D0 0x708 0x640 0x578 0x4B0 0x3E8 0x384 0x320 0x2BC 0x258 0x1F4 0x190 0x12C 0xC8 0x64 0x0>;
            };
            qcom,pc-temp-y4-lut {
                qcom,lut-col-legend = <0xFFFFFFF6 0x0 0xA 0x19 0x28 0x32>;
                qcom,lut-data = <0x40EA 0x409A 0x4071 0x4056 0x403C 0x4035 0x410C 0x40AC 0x407F 0x4054 0x403A 0x4033 0x4148 0x40CA 0x408D 0x4050 0x4036 0x4030 0x418A 0x40EB 0x4098 0x404C 0x4032 0x402C 0x41C1 0x4106 0x40A0 0x4049 0x402F 0x402A 0x41DA 0x4110 0x40A2 0x4048 0x402E 0x4028 0x41DE 0x410F 0x409F 0x4047 0x402E 0x4027 0x41E0 0x410D 0x409A 0x4047 0x402E 0x4027 0x41DE 0x4108 0x4095 0x4047 0x402E 0x4027 0x41D7 0x4100 0x4090 0x4048 0x402F 0x4028 0x41D4 0x40FC 0x408E 0x404A 0x4030 0x4028 0x41D9 0x40FC 0x408E 0x404B 0x4031 0x4029 0x41E3 0x40FC 0x408F 0x404E 0x4033 0x402B 0x41F2 0x4100 0x4092 0x4053 0x4036 0x402C 0x4208 0x4110 0x409A 0x405A 0x403A 0x402F 0x4212 0x4124 0x40A5 0x4061 0x403D 0x4032 0x420F 0x4148 0x40B7 0x4068 0x4040 0x4036 0x4207 0x4169 0x40CE 0x4071 0x4044 0x403B 0x41EF 0x416F 0x40F0 0x4081 0x404D 0x403F 0x41B4 0x4172 0x4113 0x4095 0x4059 0x4044 0x417D 0x4170 0x4112 0x40A3 0x4067 0x404E 0x414F 0x4133 0x40EC 0x40B0 0x407A 0x405F 0x4129 0x40E4 0x40C1 0x40B2 0x4081 0x4067 0x4114 0x40C0 0x4094 0x4080 0x405F 0x404F 0x4106 0x40A8 0x406F 0x404B 0x4038 0x4030 0x40F8 0x4098 0x4064 0x4042 0x4032 0x402C 0x40E3 0x408F 0x405E 0x403F 0x4030 0x402B 0x40D5 0x4088 0x405C 0x403E 0x4030 0x402A 0x40D8 0x4080 0x405D 0x4041 0x4032 0x402C 0x40E1 0x4079 0x405D 0x4044 0x4035 0x402E 0x40E6 0x4073 0x405E 0x404A 0x4039 0x4032 0x40E6 0x406E 0x4060 0x4051 0x403E 0x4037 0x40E7 0x406A 0x4060 0x4057 0x4044 0x403C 0x40EA 0x406C 0x405F 0x405D 0x404D 0x4043 0x40F0 0x4072 0x405D 0x405F 0x4051 0x4047 0x40F6 0x407A 0x405F 0x405F 0x404C 0x4041 0x40FE 0x4088 0x4062 0x405D 0x4041 0x4035 0x4105 0x4098 0x4065 0x4055 0x4039 0x402F 0x410B 0x40A6 0x4068 0x4042 0x4032 0x402C 0x4110 0x40B2 0x406C 0x403B 0x402F 0x402B 0x4111 0x40BA 0x4070 0x403E 0x4030 0x402B 0x410C 0x40C0 0x4074 0x403F 0x4030 0x402B 0x4107 0x40C1 0x407B 0x403F 0x402E 0x4029 0x4103 0x40C1 0x407B 0x403E 0x402D 0x4027 0x4108 0x40BE 0x406C 0x4034 0x4025 0x4020 0x4109 0x40B9 0x407D 0x4043 0x402E 0x4027 0x4113 0x40C2 0x4092 0x404C 0x4032 0x402B 0x411A 0x40CE 0x40B0 0x405C 0x403B 0x403A 0x4103 0x40E2 0x40D9 0x4073 0x4062 0x4064 0x40E8 0x40FF 0x40FF 0x406D 0x4048 0x4047 0x594F 0x4127 0x411B 0x4063 0x4035 0x4033 0x791E 0x4135 0x4169 0x4076 0x403E 0x403B 0xE8E9 0x5753 0x428B 0x409D 0x4048 0x4046 0x7146 0x8F46 0x6C6E 0x410D 0x407E 0x4084 0x7146 0x8F46 0x6C6E 0x410D 0x407E 0x4084 0x7146 0x8F46 0x6C6E 0x410D 0x407E 0x4084>;
                qcom,lut-row-legend = <0x2710 0x2648 0x2580 0x24B8 0x23F0 0x2328 0x2260 0x2198 0x20D0 0x2008 0x1F40 0x1E78 0x1DB0 0x1CE8 0x1C20 0x1B58 0x1A90 0x19C8 0x1900 0x1838 0x1770 0x16A8 0x15E0 0x1518 0x1450 0x1388 0x12C0 0x11F8 0x1130 0x1068 0xFA0 0xED8 0xE10 0xD48 0xC80 0xBB8 0xAF0 0xA28 0x960 0x898 0x7D0 0x708 0x640 0x578 0x4B0 0x3E8 0x384 0x320 0x2BC 0x258 0x1F4 0x190 0x12C 0xC8 0x64 0x0>;
            };
            qcom,pc-temp-y5-lut {
                qcom,lut-col-legend = <0xFFFFFFF6 0x0 0xA 0x19 0x28 0x32>;
                qcom,lut-data = <0x4086 0x4AD4 0x5150 0x4DF6 0x5622 0x51E5 0x41B2 0x4D34 0x5529 0x53EB 0x5926 0x52BE 0x4316 0x4FCE 0x57EB 0x574E 0x5B05 0x5731 0x44A9 0x5231 0x59BF 0x58D6 0x5BE8 0x5D41 0x4665 0x53ED 0x5AC6 0x5937 0x5BF9 0x62EA 0x4841 0x5491 0x5B25 0x591C 0x5B60 0x6643 0x4ADA 0x5437 0x5A87 0x5753 0x59C0 0x6ADD 0x4D1C 0x538F 0x5950 0x54D7 0x5784 0x6EB6 0x4D66 0x530F 0x57B4 0x52B7 0x5534 0x6BA2 0x4D58 0x528A 0x54DC 0x4F7D 0x529D 0x635A 0x4D38 0x51CE 0x51F1 0x4D1C 0x5069 0x5DCD 0x4B8B 0x4FC8 0x4EC5 0x4B94 0x4EA3 0x5B25 0x497B 0x4CD7 0x4BF6 0x49EE 0x4CCF 0x58BE 0x49DC 0x49B6 0x4A01 0x4632 0x4A0D 0x55BA 0x4CA1 0x45F8 0x480E 0x4185 0x4723 0x5264 0x4FE3 0x447C 0x45CE 0x40B9 0x46CC 0x4E75 0x5415 0x4568 0x423A 0x4194 0x48B1 0x490A 0x57DB 0x476A 0x401C 0x4256 0x49F3 0x4609 0x5954 0x4D19 0x41AC 0x42BC 0x464C 0x46AD 0x5A60 0x5909 0x4599 0x4354 0x40E7 0x482A 0x5ACA 0x5DF7 0x4BF4 0x4668 0x418E 0x49E0 0x5B37 0x5D51 0x5808 0x4F8E 0x4870 0x4C52 0x5B62 0x5C9E 0x5F9C 0x5708 0x4F7C 0x4FAF 0x5550 0x5D6A 0x6191 0x5BEB 0x5643 0x562A 0x44B4 0x5FEE 0x6264 0x5FCC 0x5B86 0x5D13 0x3B65 0x616E 0x626C 0x632D 0x5D12 0x60A0 0x384D 0x6215 0x6283 0x665E 0x5E08 0x6331 0x365A 0x6277 0x62E6 0x665C 0x5E03 0x63BC 0x34DE 0x6275 0x6381 0x5FC0 0x5A93 0x5FD7 0x3392 0x6214 0x6410 0x5ADF 0x5703 0x5A04 0x332F 0x6076 0x6413 0x5D35 0x55D9 0x53C5 0x3450 0x541D 0x639B 0x6144 0x551C 0x4D2A 0x358A 0x4926 0x6405 0x61F1 0x54A0 0x4BC4 0x3650 0x4ADB 0x6613 0x613B 0x5321 0x4E0F 0x379C 0x5028 0x678A 0x60D0 0x5232 0x511D 0x384D 0x53FE 0x65C3 0x6353 0x5936 0x540A 0x3894 0x5823 0x6271 0x675C 0x638D 0x5751 0x38D5 0x5B7F 0x6184 0x6A14 0x646F 0x5A95 0x3943 0x5CFB 0x6294 0x6C65 0x6196 0x5DC0 0x39C7 0x5DB6 0x630C 0x6C55 0x5FB8 0x61E0 0x3A1A 0x5B00 0x60EC 0x6599 0x5F87 0x69DF 0x3A38 0x4B32 0x5DCD 0x61D2 0x5F9D 0x7235 0x396E 0x4098 0x59D1 0x6045 0x5FBD 0x784C 0x36D2 0x3B57 0x56E9 0x60B7 0x611C 0x77ED 0x3656 0x3A04 0x574B 0x58BE 0x6821 0x776A 0x350D 0x3915 0x5410 0x56C6 0x575E 0x60D4 0x3549 0x37F2 0x4CE8 0x5393 0x519F 0x63E1 0x36C2 0x37D3 0x45E2 0x57C0 0x6982 0x6ADE 0x5266 0x370F 0x494B 0x5BE6 0x64C4 0x60C4 0x738B 0x37FA 0x4602 0x631D 0x6AFA 0x68C9 0x25BC 0x38FD 0x404E 0x63E5 0x6C11 0x7368 0x22FD 0x4994 0x3811 0x6245 0x7768 0x77E1 0x235D 0x248E 0x3899 0x5FF6 0x6C0C 0x6E4C 0x2312 0x239E 0x2A58 0x5F03 0x67D3 0x6AB3 0x2312 0x239E 0x2A58 0x5F03 0x67D3 0x6AB3 0x2312 0x239E 0x2A58 0x5F03 0x67D3 0x6AB3>;
                qcom,lut-row-legend = <0x2710 0x2648 0x2580 0x24B8 0x23F0 0x2328 0x2260 0x2198 0x20D0 0x2008 0x1F40 0x1E78 0x1DB0 0x1CE8 0x1C20 0x1B58 0x1A90 0x19C8 0x1900 0x1838 0x1770 0x16A8 0x15E0 0x1518 0x1450 0x1388 0x12C0 0x11F8 0x1130 0x1068 0xFA0 0xED8 0xE10 0xD48 0xC80 0xBB8 0xAF0 0xA28 0x960 0x898 0x7D0 0x708 0x640 0x578 0x4B0 0x3E8 0x384 0x320 0x2BC 0x258 0x1F4 0x190 0x12C 0xC8 0x64 0x0>;
            };
            qcom,pc-temp-y6-lut {
                qcom,lut-col-legend = <0xFFFFFFF6 0x0 0xA 0x19 0x28 0x32>;
                qcom,lut-data = <0x15A4 0x145B 0x13DD 0x137A 0x1358 0x1351 0x15AB 0x1466 0x13DE 0x1379 0x1357 0x1350 0x15B0 0x146D 0x13DF 0x1377 0x1356 0x134F 0x15B2 0x1471 0x13DF 0x1376 0x1355 0x134E 0x15B3 0x1472 0x13DE 0x1375 0x1354 0x134E 0x15B3 0x1472 0x13DD 0x1375 0x1354 0x134E 0x15B0 0x146F 0x13DB 0x1374 0x1354 0x134E 0x15A9 0x1469 0x13D7 0x1374 0x1355 0x134F 0x15A3 0x1464 0x13D4 0x1374 0x1355 0x134F 0x159C 0x1460 0x13D0 0x1374 0x1355 0x1350 0x1598 0x145D 0x13CE 0x1375 0x1356 0x1350 0x1596 0x1459 0x13CC 0x1375 0x1357 0x1351 0x1595 0x1456 0x13CB 0x1377 0x1358 0x1352 0x1596 0x1456 0x13CC 0x1378 0x1359 0x1353 0x1599 0x1458 0x13CD 0x1379 0x135B 0x1354 0x159B 0x145B 0x13D0 0x137C 0x135C 0x1355 0x1599 0x1464 0x13D3 0x137F 0x135E 0x1356 0x1596 0x146D 0x13D8 0x1383 0x1361 0x1358 0x158E 0x146E 0x13E1 0x1389 0x1363 0x135A 0x157B 0x146E 0x13EB 0x138F 0x1366 0x135D 0x156B 0x146D 0x13EA 0x1393 0x136A 0x1360 0x155F 0x1459 0x13DE 0x1396 0x1371 0x1366 0x1554 0x143F 0x13D1 0x1396 0x1374 0x1368 0x154A 0x1435 0x13C2 0x1386 0x1368 0x135F 0x1540 0x142E 0x13B7 0x1374 0x135A 0x1354 0x153C 0x142C 0x13B4 0x1372 0x1358 0x1352 0x153F 0x142B 0x13B3 0x1371 0x1357 0x1352 0x1543 0x142B 0x13B3 0x1371 0x1357 0x1352 0x154A 0x142B 0x13B4 0x1372 0x1358 0x1353 0x1557 0x142C 0x13B6 0x1373 0x1359 0x1354 0x1566 0x142D 0x13B7 0x1375 0x135A 0x1355 0x1578 0x142E 0x13B9 0x1378 0x135C 0x1356 0x158C 0x1430 0x13BB 0x137B 0x135E 0x1357 0x15A1 0x1435 0x13BC 0x137D 0x1361 0x135A 0x15B8 0x1442 0x13BE 0x137E 0x1362 0x135B 0x15D2 0x144F 0x13C0 0x137E 0x1361 0x1359 0x15F1 0x145D 0x13C3 0x137E 0x135E 0x1356 0x1613 0x146E 0x13C7 0x137C 0x135C 0x1354 0x163B 0x1480 0x13CB 0x1377 0x1359 0x1353 0x1667 0x1493 0x13CF 0x1375 0x1358 0x1353 0x1697 0x14A7 0x13D5 0x1376 0x1359 0x1354 0x16CB 0x14BB 0x13DD 0x1377 0x135A 0x1355 0x170A 0x14D5 0x13E9 0x1378 0x1359 0x1354 0x175C 0x14F9 0x13F4 0x1378 0x1359 0x1353 0x17D1 0x152B 0x13F5 0x1375 0x1356 0x1351 0x1867 0x1562 0x1413 0x137C 0x135A 0x1354 0x18E4 0x159D 0x142B 0x1380 0x135C 0x1356 0x1975 0x15EA 0x144F 0x1388 0x1361 0x135C 0x1A44 0x1656 0x1488 0x1391 0x136E 0x1369 0x1BF5 0x16FF 0x14CE 0x1390 0x1365 0x1360 0x21AD 0x1823 0x1545 0x138D 0x135F 0x135A 0x2DCD 0x1970 0x16A5 0x1397 0x1363 0x135D 0x5694 0x1ED0 0x190A 0x13A9 0x1367 0x1361 0x5B44 0x3267 0x2507 0x13DA 0x1379 0x1375 0x5B44 0x3267 0x2507 0x13DA 0x1379 0x1375 0x5B44 0x3267 0x2507 0x13DA 0x1379 0x1375>;
                qcom,lut-row-legend = <0x2710 0x2648 0x2580 0x24B8 0x23F0 0x2328 0x2260 0x2198 0x20D0 0x2008 0x1F40 0x1E78 0x1DB0 0x1CE8 0x1C20 0x1B58 0x1A90 0x19C8 0x1900 0x1838 0x1770 0x16A8 0x15E0 0x1518 0x1450 0x1388 0x12C0 0x11F8 0x1130 0x1068 0xFA0 0xED8 0xE10 0xD48 0xC80 0xBB8 0xAF0 0xA28 0x960 0x898 0x7D0 0x708 0x640 0x578 0x4B0 0x3E8 0x384 0x320 0x2BC 0x258 0x1F4 0x190 0x12C 0xC8 0x64 0x0>;
            };
            qcom,pc-temp-z1-lut {
                qcom,lut-col-legend = <0x0 0xA 0x19 0x28 0x32>;
                qcom,lut-data = <0x2DD3 0x2BD1 0x2A3E 0x2982 0x2968 0x2DE1 0x2C0A 0x2A58 0x29A5 0x2988 0x2DEA 0x2BFA 0x2A57 0x299E 0x2985 0x2DED 0x2BE4 0x2A4D 0x2999 0x2984 0x2DEF 0x2BE0 0x2A44 0x2997 0x2983 0x2DEF 0x2BE0 0x2A3D 0x2997 0x2984 0x2DE6 0x2BDF 0x2A38 0x2998 0x2986 0x2DD8 0x2BD3 0x2A35 0x2999 0x2989 0x2DC0 0x2BC3 0x2A34 0x299B 0x298C 0x2D9E 0x2BBD 0x2A33 0x299D 0x2990 0x2D8E 0x2BB9 0x2A36 0x29A0 0x2994 0x2D87 0x2BB7 0x2A39 0x29A4 0x2999 0x2D83 0x2BB9 0x2A3E 0x29A8 0x299D 0x2D84 0x2BBB 0x2A43 0x29AD 0x29A2 0x2D85 0x2BC0 0x2A49 0x29B2 0x29A6 0x2D85 0x2BC7 0x2A50 0x29B7 0x29AC 0x2D84 0x2BCD 0x2A58 0x29BC 0x29B2 0x2D85 0x2BD2 0x2A5D 0x29C1 0x29B7 0x2D8A 0x2BD8 0x2A62 0x29C7 0x29BC 0x2D94 0x2BDD 0x2A69 0x29CC 0x29C1 0x2D9D 0x2BE5 0x2A70 0x29D2 0x29C6 0x2DA4 0x2BEA 0x2A77 0x29D7 0x29CA 0x2DAD 0x2BEF 0x2A7B 0x29DB 0x29CF 0x2DBB 0x2BF3 0x2A7F 0x29DF 0x29D3 0x2DCD 0x2BF5 0x2A86 0x29E3 0x29D7 0x2DD3 0x2BF7 0x2A8D 0x29E8 0x29DA 0x2DCB 0x2BF9 0x2A94 0x29EC 0x29DE 0x2DC2 0x2BFD 0x2A9A 0x29F0 0x29E2 0x2DC3 0x2C01 0x2A9F 0x29F4 0x29E5 0x2DC9 0x2C0A 0x2AA4 0x29F8 0x29E8 0x2DCE 0x2C16 0x2AA9 0x29FC 0x29EC 0x2DD6 0x2C17 0x2AAF 0x2A00 0x29EF 0x2DDE 0x2C13 0x2AB5 0x2A03 0x29F2 0x2DE0 0x2C11 0x2ABB 0x2A07 0x29F4 0x2DDE 0x2C16 0x2AC0 0x2A0B 0x29F7 0x2DDE 0x2C1E 0x2AC5 0x2A0F 0x29FA 0x2DE7 0x2C24 0x2ACB 0x2A13 0x29FD 0x2DF4 0x2C29 0x2AD2 0x2A17 0x2A00 0x2DFE 0x2C2F 0x2AD9 0x2A1A 0x2A02 0x2E08 0x2C38 0x2ADF 0x2A1C 0x2A03 0x2E0F 0x2C41 0x2AE3 0x2A1E 0x2A05 0x2E14 0x2C47 0x2AE7 0x2A21 0x2A06 0x2E17 0x2C4D 0x2AE9 0x2A23 0x2A08 0x2E20 0x2C5E 0x2AF1 0x2A26 0x2A0A 0x2E40 0x2C66 0x2AF7 0x2A29 0x2A0B 0x2E33 0x2C63 0x2AF8 0x2A2A 0x2A0D 0x2E3D 0x2C6A 0x2B00 0x2A2A 0x2A0D 0x2E4C 0x2C6D 0x2AFB 0x2A2C 0x2A0D 0x2E3C 0x2C64 0x2B00 0x2A2E 0x2A0F 0x2E4B 0x2C64 0x2B04 0x2A30 0x2A10 0x2E42 0x2C6E 0x2B09 0x2A33 0x2A12 0x2E53 0x2C7E 0x2B0E 0x2A38 0x2A15 0x2E5F 0x2C83 0x2B18 0x2A3C 0x2A19 0x2E58 0x2CAA 0x2B22 0x2A42 0x2A1F 0x2E58 0x2CAA 0x2B22 0x2A42 0x2A1F 0x2E58 0x2CAA 0x2B22 0x2A42 0x2A1F>;
                qcom,lut-row-legend = <0x2710 0x2648 0x2580 0x24B8 0x23F0 0x2328 0x2260 0x2198 0x20D0 0x2008 0x1F40 0x1E78 0x1DB0 0x1CE8 0x1C20 0x1B58 0x1A90 0x19C8 0x1900 0x1838 0x1770 0x16A8 0x15E0 0x1518 0x1450 0x1388 0x12C0 0x11F8 0x1130 0x1068 0xFA0 0xED8 0xE10 0xD48 0xC80 0xBB8 0xAF0 0xA28 0x960 0x898 0x7D0 0x708 0x640 0x578 0x4B0 0x3E8 0x384 0x320 0x2BC 0x258 0x1F4 0x190 0x12C 0xC8 0x64 0x0>;
            };
            qcom,pc-temp-z2-lut {
                qcom,lut-col-legend = <0x0 0xA 0x19 0x28 0x32>;
                qcom,lut-data = <0x2AB2 0x287A 0x2A66 0x2C9F 0x2CDE 0x29D1 0x298F 0x2AFC 0x2B6C 0x2C7D 0x2961 0x29DA 0x2B56 0x2C99 0x2C84 0x295B 0x2A09 0x2B22 0x2C7F 0x2CED 0x294D 0x2A05 0x2AF0 0x2C60 0x2D58 0x293C 0x29DA 0x2AC6 0x2C3A 0x2D46 0x291D 0x29B3 0x2AAA 0x2C0B 0x2D01 0x28FF 0x2998 0x2AA9 0x2C06 0x2CEB 0x28EB 0x2985 0x2AAD 0x2C1D 0x2CE0 0x28DA 0x2987 0x2AAC 0x2C2A 0x2CD7 0x28D6 0x2994 0x2A9F 0x2C22 0x2CD8 0x28DD 0x299F 0x2A96 0x2C13 0x2CDD 0x28E6 0x29A6 0x2A99 0x2C07 0x2CDF 0x28EE 0x29AD 0x2A9E 0x2BFC 0x2CE4 0x28FC 0x29B8 0x2AA2 0x2BF7 0x2CEF 0x2908 0x29C6 0x2AA4 0x2BF7 0x2D1A 0x2912 0x29D1 0x2AA6 0x2BF8 0x2D51 0x291C 0x29DA 0x2AAA 0x2BFD 0x2D76 0x2926 0x29E0 0x2AAF 0x2C08 0x2D9D 0x2930 0x29E3 0x2AA9 0x2C13 0x2DAE 0x2939 0x29E9 0x2A93 0x2C21 0x2DBC 0x293F 0x29F0 0x2A8D 0x2C39 0x2DC6 0x2947 0x2A00 0x2AC7 0x2C8C 0x2E20 0x2954 0x2A0A 0x2B03 0x2D00 0x2EAF 0x2967 0x29F4 0x2B01 0x2D39 0x2E9A 0x296E 0x29CB 0x2AF0 0x2D5F 0x2DEF 0x2966 0x29C8 0x2AEF 0x2D68 0x2D54 0x295F 0x29E6 0x2B13 0x2CBB 0x2CCB 0x295F 0x29FB 0x2B2F 0x2BE5 0x2C62 0x2962 0x29FA 0x2B0D 0x2BA7 0x2C59 0x2964 0x29F9 0x2ACF 0x2B7E 0x2C5B 0x2967 0x29F8 0x2ABC 0x2B76 0x2C61 0x296A 0x29F8 0x2AB9 0x2B94 0x2C8D 0x296B 0x29F9 0x2ABB 0x2BBF 0x2CCC 0x296E 0x2A03 0x2ACA 0x2BF4 0x2D11 0x2971 0x2A11 0x2AE1 0x2C2F 0x2D5C 0x2976 0x2A16 0x2AF1 0x2C4E 0x2D90 0x297C 0x2A18 0x2AFF 0x2C69 0x2DCA 0x2982 0x2A1C 0x2B11 0x2C80 0x2DEA 0x298A 0x2A2E 0x2B2F 0x2CAF 0x2DF6 0x298D 0x2A3E 0x2B48 0x2CE0 0x2E01 0x2982 0x2A35 0x2B37 0x2CD6 0x2DF4 0x297A 0x2A1B 0x2B0E 0x2CAF 0x2DCD 0x297C 0x2A16 0x2B2D 0x2CA6 0x2DD6 0x2941 0x2A2D 0x2B4D 0x2CBC 0x2DDA 0x2A04 0x2A98 0x2B2F 0x2CF2 0x2E1A 0x32F5 0x2A7A 0x2B05 0x2CC5 0x2E50 0x29F9 0x2A9E 0x2AEE 0x2CEA 0x2E6A 0x3389 0x2B02 0x2AE3 0x2D17 0x2EBA 0x2F1A 0x2AEA 0x2B23 0x2CF3 0x2D7D 0x3166 0x2B11 0x2B22 0x2C1F 0x2C85 0x29B3 0x2AFD 0x2AF2 0x2BBB 0x2C33 0x2829 0x2AAA 0x2AA4 0x2B6E 0x2C0D 0x290B 0x29BC 0x2A40 0x2B10 0x2BD2 0x290B 0x29BC 0x2A40 0x2B10 0x2BD2 0x290B 0x29BC 0x2A40 0x2B10 0x2BD2>;
                qcom,lut-row-legend = <0x2710 0x2648 0x2580 0x24B8 0x23F0 0x2328 0x2260 0x2198 0x20D0 0x2008 0x1F40 0x1E78 0x1DB0 0x1CE8 0x1C20 0x1B58 0x1A90 0x19C8 0x1900 0x1838 0x1770 0x16A8 0x15E0 0x1518 0x1450 0x1388 0x12C0 0x11F8 0x1130 0x1068 0xFA0 0xED8 0xE10 0xD48 0xC80 0xBB8 0xAF0 0xA28 0x960 0x898 0x7D0 0x708 0x640 0x578 0x4B0 0x3E8 0x384 0x320 0x2BC 0x258 0x1F4 0x190 0x12C 0xC8 0x64 0x0>;
            };
            qcom,pc-temp-z3-lut {
                qcom,lut-col-legend = <0x0 0xA 0x19 0x28 0x32>;
                qcom,lut-data = <0x4BD2 0x4B88 0x4B83 0x4B62 0x4B62 0x4C28 0x4BF5 0x4BAA 0x4B7D 0x4B77 0x4C5A 0x4C09 0x4BBF 0x4B8E 0x4B7A 0x4C69 0x4C12 0x4BC0 0x4B92 0x4B7D 0x4C72 0x4C14 0x4BC1 0x4B93 0x4B7E 0x4C75 0x4C15 0x4BC1 0x4B90 0x4B7D 0x4C76 0x4C14 0x4BC1 0x4B8A 0x4B7B 0x4C76 0x4C12 0x4BBF 0x4B87 0x4B79 0x4C75 0x4C10 0x4BB8 0x4B87 0x4B78 0x4C72 0x4C0B 0x4BB2 0x4B86 0x4B76 0x4C6E 0x4C02 0x4BAB 0x4B82 0x4B74 0x4C68 0x4BFC 0x4BA7 0x4B7C 0x4B72 0x4C62 0x4BF9 0x4BA6 0x4B7B 0x4B6F 0x4C5A 0x4BF7 0x4BA5 0x4B7A 0x4B6D 0x4C52 0x4BF3 0x4BA3 0x4B79 0x4B6A 0x4C4D 0x4BF0 0x4B9E 0x4B75 0x4B68 0x4C4A 0x4BED 0x4B9A 0x4B71 0x4B66 0x4C47 0x4BEA 0x4B99 0x4B70 0x4B65 0x4C44 0x4BE8 0x4B98 0x4B6F 0x4B63 0x4C40 0x4BE6 0x4B97 0x4B6F 0x4B62 0x4C3D 0x4BE3 0x4B96 0x4B6D 0x4B61 0x4C3B 0x4BE3 0x4B95 0x4B6C 0x4B60 0x4C3A 0x4BEA 0x4B9C 0x4B6F 0x4B65 0x4C3F 0x4BEF 0x4BA3 0x4B77 0x4B6E 0x4C4C 0x4BEC 0x4BA0 0x4B7E 0x4B75 0x4C51 0x4BE7 0x4B95 0x4B88 0x4B7A 0x4C4E 0x4BE5 0x4B92 0x4B8C 0x4B7C 0x4C4A 0x4BE5 0x4BA1 0x4B8A 0x4B7B 0x4C48 0x4BE6 0x4BAE 0x4B88 0x4B79 0x4C46 0x4BEC 0x4BAF 0x4B85 0x4B77 0x4C44 0x4BF3 0x4BAF 0x4B80 0x4B74 0x4C43 0x4BF3 0x4BAE 0x4B7D 0x4B70 0x4C43 0x4BF1 0x4BA9 0x4B7A 0x4B6B 0x4C43 0x4BEE 0x4BA5 0x4B77 0x4B66 0x4C42 0x4BEC 0x4BA2 0x4B73 0x4B62 0x4C41 0x4BEA 0x4BA1 0x4B70 0x4B5F 0x4C40 0x4BE9 0x4B9F 0x4B70 0x4B5F 0x4C3E 0x4BE8 0x4B9E 0x4B70 0x4B62 0x4C3B 0x4BE7 0x4B9D 0x4B71 0x4B64 0x4C35 0x4BE4 0x4B9A 0x4B70 0x4B66 0x4C30 0x4BE0 0x4B97 0x4B70 0x4B67 0x4C2C 0x4BDD 0x4B95 0x4B70 0x4B67 0x4C28 0x4BDA 0x4B94 0x4B71 0x4B68 0x4C21 0x4BD8 0x4B94 0x4B72 0x4B69 0x4B9B 0x4BD1 0x4B93 0x4B71 0x4B68 0x4B3D 0x4BC0 0x4B89 0x4B69 0x4B5D 0x4B3C 0x4BBF 0x4B86 0x4B69 0x4B5B 0x4B3D 0x4BB1 0x4B85 0x4B64 0x4B5A 0x4B3A 0x4B92 0x4B84 0x4B61 0x4B57 0x4B3A 0x4B9C 0x4B82 0x4B68 0x4B64 0x4B3B 0x4B93 0x4B85 0x4B72 0x4B68 0x4B3D 0x4B8A 0x4B8B 0x4B74 0x4B68 0x4B41 0x4B85 0x4B8E 0x4B75 0x4B6A 0x4C14 0x4BC9 0x4B91 0x4B79 0x4B6B 0x4C14 0x4BC9 0x4B91 0x4B79 0x4B6B 0x4C14 0x4BC9 0x4B91 0x4B79 0x4B6B>;
                qcom,lut-row-legend = <0x2710 0x2648 0x2580 0x24B8 0x23F0 0x2328 0x2260 0x2198 0x20D0 0x2008 0x1F40 0x1E78 0x1DB0 0x1CE8 0x1C20 0x1B58 0x1A90 0x19C8 0x1900 0x1838 0x1770 0x16A8 0x15E0 0x1518 0x1450 0x1388 0x12C0 0x11F8 0x1130 0x1068 0xFA0 0xED8 0xE10 0xD48 0xC80 0xBB8 0xAF0 0xA28 0x960 0x898 0x7D0 0x708 0x640 0x578 0x4B0 0x3E8 0x384 0x320 0x2BC 0x258 0x1F4 0x190 0x12C 0xC8 0x64 0x0>;
            };
            qcom,pc-temp-z4-lut {
                qcom,lut-col-legend = <0x0 0xA 0x19 0x28 0x32>;
                qcom,lut-data = <0x3D25 0x3AD2 0x3A21 0x39B5 0x39A6 0x3CE9 0x3C09 0x39F0 0x3977 0x395E 0x3C93 0x3B90 0x3A46 0x39A8 0x397D 0x3C02 0x3AC8 0x3A05 0x3995 0x3973 0x3B4A 0x3A60 0x39CD 0x397E 0x3965 0x3AD1 0x3A1D 0x39AA 0x396F 0x395A 0x3A81 0x39EB 0x398E 0x3963 0x3951 0x3A42 0x39C5 0x397D 0x395A 0x394B 0x3A10 0x39A7 0x3970 0x3953 0x3947 0x39E8 0x3993 0x3967 0x394E 0x3943 0x39C7 0x3983 0x3962 0x394B 0x393F 0x39A9 0x3978 0x395E 0x3948 0x393C 0x3995 0x3971 0x3957 0x3943 0x3938 0x398C 0x396C 0x3950 0x393C 0x3935 0x3987 0x3967 0x394B 0x3937 0x3931 0x3982 0x3963 0x3948 0x3934 0x392D 0x397E 0x3960 0x3946 0x3932 0x3929 0x397A 0x395E 0x3942 0x392D 0x3924 0x3978 0x395C 0x393E 0x3928 0x3920 0x3977 0x395A 0x393C 0x3925 0x391D 0x3975 0x3957 0x393B 0x3924 0x391B 0x3972 0x3958 0x393B 0x3924 0x3919 0x3970 0x3963 0x3952 0x3939 0x3929 0x3986 0x3975 0x3975 0x3958 0x3943 0x39C1 0x3998 0x398D 0x395D 0x3948 0x39D9 0x39C3 0x39A2 0x395B 0x3947 0x39D7 0x39C8 0x39A6 0x3959 0x3946 0x39D4 0x39B2 0x398C 0x3951 0x3940 0x39CC 0x399B 0x396F 0x3947 0x3938 0x39BC 0x398B 0x3963 0x3941 0x3933 0x39AE 0x397F 0x395B 0x393C 0x392F 0x39A5 0x397A 0x3956 0x3937 0x392B 0x399E 0x3978 0x3952 0x3933 0x3928 0x399B 0x3977 0x3951 0x3930 0x3926 0x3999 0x3977 0x3951 0x3930 0x3925 0x3996 0x3977 0x3952 0x392F 0x3924 0x3993 0x3977 0x3953 0x3931 0x3926 0x3990 0x3975 0x3955 0x3939 0x392F 0x398A 0x3972 0x3957 0x393D 0x3934 0x3980 0x3970 0x3957 0x393D 0x3932 0x3975 0x396C 0x3958 0x393C 0x392E 0x396D 0x3964 0x3954 0x3939 0x392B 0x3963 0x3955 0x3949 0x3932 0x3928 0x3952 0x394D 0x3943 0x3930 0x3925 0x39B4 0x3942 0x393C 0x392E 0x3922 0x3A03 0x3930 0x392F 0x3926 0x391F 0x3A02 0x392A 0x3929 0x391D 0x3919 0x39FE 0x3932 0x3920 0x3916 0x390F 0x39FA 0x394E 0x391A 0x3913 0x390C 0x39F7 0x3942 0x3921 0x3917 0x390D 0x39F3 0x3954 0x3929 0x3914 0x390F 0x39F4 0x3962 0x3926 0x3914 0x3910 0x3A00 0x396E 0x3923 0x3914 0x3912 0x3962 0x3932 0x3925 0x3915 0x3914 0x3962 0x3932 0x3925 0x3915 0x3914 0x3962 0x3932 0x3925 0x3915 0x3914>;
                qcom,lut-row-legend = <0x2710 0x2648 0x2580 0x24B8 0x23F0 0x2328 0x2260 0x2198 0x20D0 0x2008 0x1F40 0x1E78 0x1DB0 0x1CE8 0x1C20 0x1B58 0x1A90 0x19C8 0x1900 0x1838 0x1770 0x16A8 0x15E0 0x1518 0x1450 0x1388 0x12C0 0x11F8 0x1130 0x1068 0xFA0 0xED8 0xE10 0xD48 0xC80 0xBB8 0xAF0 0xA28 0x960 0x898 0x7D0 0x708 0x640 0x578 0x4B0 0x3E8 0x384 0x320 0x2BC 0x258 0x1F4 0x190 0x12C 0xC8 0x64 0x0>;
            };
            qcom,pc-temp-z5-lut {
                qcom,lut-col-legend = <0x0 0xA 0x19 0x28 0x32>;
                qcom,lut-data = <0x32E2 0x31EA 0x3B11 0x3989 0x3EC6 0x3A95 0x40D1 0x5110 0x5515 0x64F6 0x40CF 0x4567 0x4E67 0x5909 0x5BED 0x4582 0x4B61 0x5204 0x5E4E 0x5F70 0x4976 0x505F 0x562E 0x6162 0x6464 0x4CF9 0x5505 0x5AEA 0x6147 0x685A 0x5106 0x59C5 0x5F68 0x60B8 0x6C48 0x5575 0x5F04 0x625C 0x61B6 0x6E8F 0x5A73 0x6438 0x649E 0x6655 0x6F8D 0x607D 0x68AC 0x64F6 0x68FD 0x6FC8 0x67AA 0x6CBA 0x62D4 0x6599 0x6FCD 0x721A 0x7091 0x6128 0x612E 0x6FFC 0x798A 0x7492 0x64B0 0x6336 0x7008 0x7A8A 0x77E1 0x6B84 0x6B77 0x6FC1 0x7ACD 0x7997 0x6CB3 0x6EA4 0x6F99 0x7BCC 0x7ABD 0x6A1D 0x6A7D 0x712D 0x8011 0x7C7E 0x687F 0x6683 0x7431 0x8461 0x7FB4 0x6BD3 0x6A19 0x788B 0x85F9 0x8315 0x7230 0x7320 0x7F27 0x8754 0x85A5 0x76BE 0x7845 0x8531 0x8927 0x88BB 0x7AA4 0x7AFA 0x8BF3 0x8CD2 0x9068 0x7FF6 0x7CEC 0x91A2 0x9335 0xAA9B 0x8EBE 0x7EFB 0x94C3 0xA960 0xBD62 0x9CCE 0x8077 0x9542 0xD46C 0xAC3A 0x8E35 0x7B9E 0x8C5E 0xE3D0 0x8A12 0x62BD 0x6960 0x707E 0xC92E 0x7AF5 0x53D5 0x60A8 0x6236 0xA93A 0x7390 0x5D8F 0x667F 0x6723 0x9E05 0x70B2 0x6B6D 0x6D26 0x6FA3 0x9752 0x7D91 0x7A0B 0x6F90 0x7842 0x9570 0x9414 0x8ACC 0x74D1 0x81CF 0x99AB 0xA148 0x94C3 0x7A70 0x84B5 0xA0A0 0xAAD8 0x9ADC 0x84D9 0x83D4 0xA828 0xAFA2 0xA10D 0x8F16 0x830D 0xB1F9 0xB0FA 0xAB2E 0x95C7 0x84E9 0xB61F 0xB1E9 0xB4A9 0x9ACA 0x8892 0xB503 0xB367 0xB51A 0x9AE7 0x891C 0xB38C 0xB645 0xB042 0x963F 0x8762 0xB313 0xB754 0xA90B 0x9048 0x8656 0xB21A 0xB15A 0x985D 0x87C1 0x89ED 0xB08A 0xA8BB 0x8812 0x7FE4 0x9060 0xAA80 0xA211 0x84A9 0x7FC4 0x982F 0xA63B 0x9D07 0x8375 0x82DD 0xA2DC 0xA1A0 0x9ECA 0x8375 0x8099 0x9A84 0x5C1F 0x9F73 0x8377 0x76EF 0x8688 0x2E1C 0x96FD 0x7D63 0x6AC6 0x6533 0x2DED 0x97EF 0x7953 0x7D71 0x6A7F 0x2D98 0x6E3F 0x81FF 0x7C67 0x8A5B 0x2D67 0x43C7 0x8AD8 0x7D40 0x87E6 0x2D48 0x539D 0x7404 0x7353 0xBE21 0x2D5C 0x4757 0x6396 0x8FDF 0xC69F 0x2D79 0x3E41 0x6935 0x9F27 0xC073 0x2E87 0x3AD9 0x6F4C 0x93E8 0xBE5F 0xA557 0x8EE4 0x6C3A 0xA992 0xA57E 0xA557 0x8EE4 0x6C3A 0xA992 0xA57E 0xA557 0x8EE4 0x6C3A 0xA992 0xA57E>;
                qcom,lut-row-legend = <0x2710 0x2648 0x2580 0x24B8 0x23F0 0x2328 0x2260 0x2198 0x20D0 0x2008 0x1F40 0x1E78 0x1DB0 0x1CE8 0x1C20 0x1B58 0x1A90 0x19C8 0x1900 0x1838 0x1770 0x16A8 0x15E0 0x1518 0x1450 0x1388 0x12C0 0x11F8 0x1130 0x1068 0xFA0 0xED8 0xE10 0xD48 0xC80 0xBB8 0xAF0 0xA28 0x960 0x898 0x7D0 0x708 0x640 0x578 0x4B0 0x3E8 0x384 0x320 0x2BC 0x258 0x1F4 0x190 0x12C 0xC8 0x64 0x0>;
            };
            qcom,pc-temp-z6-lut {
                qcom,lut-col-legend = <0x0 0xA 0x19 0x28 0x32>;
                qcom,lut-data = <0x3C32 0x39D0 0x38DC 0x3867 0x3856 0x3C15 0x3A82 0x38D9 0x385E 0x3849 0x3BE8 0x3A4A 0x3904 0x387A 0x3857 0x3B99 0x39EB 0x38E5 0x3873 0x3854 0x3B30 0x39B4 0x38CA 0x386A 0x384F 0x3AE5 0x398E 0x38B9 0x3861 0x384B 0x3AAF 0x396F 0x38AB 0x3859 0x3846 0x3A82 0x3957 0x38A0 0x3854 0x3842 0x3A5B 0x3943 0x3896 0x3851 0x3840 0x3A39 0x3932 0x3890 0x384E 0x383E 0x3A1C 0x3924 0x388A 0x384B 0x383C 0x3A01 0x391B 0x3886 0x3848 0x383A 0x39ED 0x3915 0x3883 0x3845 0x3838 0x39E3 0x3911 0x3880 0x3843 0x3836 0x39DC 0x390D 0x387D 0x3841 0x3834 0x39D8 0x390A 0x387B 0x383E 0x3832 0x39D5 0x3908 0x3879 0x383B 0x3830 0x39D2 0x3906 0x3878 0x383A 0x382E 0x39D0 0x3905 0x3877 0x3838 0x382C 0x39CF 0x3904 0x3877 0x3838 0x382B 0x39CE 0x3903 0x3877 0x3837 0x382A 0x39CF 0x3903 0x3877 0x3837 0x382A 0x39CF 0x390C 0x3886 0x3842 0x3833 0x39DD 0x3919 0x389A 0x3855 0x3844 0x39FF 0x3929 0x38A3 0x385D 0x384B 0x3A0D 0x393A 0x38A9 0x3862 0x384F 0x3A0D 0x393C 0x38AA 0x3863 0x3850 0x3A0C 0x3933 0x38A7 0x3860 0x384E 0x3A0A 0x392D 0x38A4 0x385B 0x384A 0x3A04 0x392D 0x38A1 0x3857 0x3847 0x3A01 0x392C 0x389F 0x3854 0x3844 0x39FE 0x392C 0x389D 0x3850 0x3841 0x39FC 0x392B 0x3899 0x384D 0x383D 0x39FD 0x392A 0x3898 0x384B 0x383A 0x39FE 0x392C 0x3898 0x3849 0x3838 0x39FF 0x392E 0x3899 0x3848 0x3836 0x3A03 0x3930 0x389A 0x3849 0x3837 0x3A06 0x3931 0x389C 0x384D 0x383D 0x3A06 0x3932 0x389E 0x3850 0x3840 0x3A05 0x3933 0x389F 0x3850 0x3840 0x3A05 0x3933 0x389F 0x3850 0x383F 0x3A08 0x3932 0x389D 0x384F 0x383F 0x3A0B 0x392F 0x389A 0x384D 0x383E 0x3A0A 0x392F 0x389A 0x384D 0x383D 0x3A00 0x392E 0x3899 0x384C 0x383C 0x39FD 0x3924 0x3890 0x3845 0x3836 0x39FA 0x3922 0x388D 0x3841 0x3832 0x39FD 0x3920 0x3888 0x383C 0x382D 0x39FC 0x391E 0x3887 0x3839 0x382A 0x39FC 0x3921 0x388B 0x383F 0x3832 0x3A02 0x3929 0x3891 0x3844 0x3835 0x3A09 0x392F 0x3895 0x3846 0x3837 0x3A19 0x3939 0x3899 0x3847 0x3839 0x3A46 0x394B 0x389F 0x384C 0x383C 0x3A46 0x394B 0x389F 0x384C 0x383C 0x3A46 0x394B 0x389F 0x384C 0x383C>;
                qcom,lut-row-legend = <0x2710 0x2648 0x2580 0x24B8 0x23F0 0x2328 0x2260 0x2198 0x20D0 0x2008 0x1F40 0x1E78 0x1DB0 0x1CE8 0x1C20 0x1B58 0x1A90 0x19C8 0x1900 0x1838 0x1770 0x16A8 0x15E0 0x1518 0x1450 0x1388 0x12C0 0x11F8 0x1130 0x1068 0xFA0 0xED8 0xE10 0xD48 0xC80 0xBB8 0xAF0 0xA28 0x960 0x898 0x7D0 0x708 0x640 0x578 0x4B0 0x3E8 0x384 0x320 0x2BC 0x258 0x1F4 0x190 0x12C 0xC8 0x64 0x0>;
            };
        };
        qcom,qbg-battery-profile-guanyu-5000mAh {
            qcom,batt-id-kohm = <0x64>;
            qcom,battery-beta = <0xD34>;
            qcom,battery-therm-kohm = <0xA>;
            qcom,battery-type = "qbg-battery-profile-guanyu-5000mAh-new";
            qcom,fastchg-current-ma = <0x1770>;
            qcom,fg-cc-cv-threshold-uv = <0x44AA20>;
            qcom,jeita-fcc-ranges = <0xFFFFFF9C 0x0 0x61A80 0x0 0x32 0xCF850 0x32 0x64 0x231860 0x64 0x96 0x387520 0x96 0x15E 0x5B8D80 0x15E 0x1E0 0x5B8D80 0x1E0 0x230 0x231860 0x230 0x5DC 0x0>;
            qcom,jeita-fv-ranges = <0xFFFFFF9C 0x0 0x440DE0 0x0 0x32 0x445C00 0x32 0x64 0x445C00 0x64 0x96 0x445C00 0x96 0x15E 0x43E6D0 0x15E 0x1E0 0x43E6D0 0x1E0 0x230 0x3E8FA0 0x230 0x5DC 0x3E8FA0>;
            qcom,jeita-hard-thresholds = <0x43D5 0xB9B>;
            qcom,jeita-soft-fcc-ua = <0x5265C0 0x2625A0>;
            qcom,jeita-soft-fv-uv = <0x445C00 0x3E8FA0>;
            qcom,jeita-soft-hys-thresholds = <0x225F 0xFDC>;
            qcom,jeita-soft-thresholds = <0x2554 0xE8D>;
            qcom,max-voltage-uv = <0x44AA20>;
            qcom,qg-batt-profile-ver = <0x64>;
            qcom,step-chg-ranges = <0x36EE80 0x40D990 0x5B8D80 0x40D991 0x445C00 0x5265C0 0x445C01 0x44AA20 0x3BD080>;
            qcom,taper-fcc;
            qcom,vbat-avg-based-step-chg;
            qcom,fcc1-temp-lut {
                qcom,lut-col-legend = <0x0 0xA 0x19 0x28 0x32>;
                qcom,lut-data = <0x13CD 0x1401 0x146C 0x1491 0x149A>;
            };
            qcom,fcc2-temp-lut {
                qcom,lut-col-legend = <0xFFFFFFF6 0x0 0xA 0x19 0x28 0x32>;
                qcom,lut-data = <0x13F2 0x141C 0x141C 0x1480 0x147C 0x1473>;
            };
            qcom,pc-temp-v1-lut {
                qcom,lut-col-legend = <0x0 0xA 0x19 0x28 0x32>;
                qcom,lut-data = <0xAF01 0xAF5C 0xAF99 0xAFB8 0xAFC0 0xADB1 0xADCE 0xADED 0xAE01 0xAE12 0xACB4 0xACC2 0xACC4 0xACBB 0xACC3 0xABCB 0xABEA 0xABD5 0xABC2 0xABC3 0xAAE4 0xAB0C 0xAAFB 0xAAE5 0xAAE4 0xAA03 0xAA28 0xAA19 0xAA05 0xAA06 0xA915 0xA940 0xA930 0xA919 0xA91C 0xA819 0xA84B 0xA840 0xA828 0xA82C 0xA719 0xA74E 0xA744 0xA72E 0xA735 0xA61A 0xA650 0xA641 0xA62E 0xA638 0xA51A 0xA550 0xA53E 0xA52E 0xA53A 0xA41F 0xA451 0xA439 0xA42E 0xA438 0xA327 0xA356 0xA33B 0xA331 0xA338 0xA235 0xA25E 0xA243 0xA237 0xA241 0xA14C 0xA171 0xA152 0xA143 0xA151 0xA06A 0xA08C 0xA067 0xA058 0xA066 0x9F90 0x9FAE 0x9F83 0x9F75 0x9F7F 0x9EBD 0x9ED9 0x9EAB 0x9E9C 0x9EA2 0x9DF4 0x9E0D 0x9DDF 0x9DCC 0x9DD0 0x9D38 0x9D4D 0x9D1A 0x9D03 0x9D05 0x9C82 0x9C96 0x9C68 0x9C4C 0x9C4B 0x9BCA 0x9BD8 0x9BB3 0x9B9B 0x9B9A 0x9B15 0x9B15 0x9AC4 0x9ABF 0x9ACA 0x9A4B 0x9A45 0x999F 0x99A2 0x99C4 0x993F 0x9943 0x98BA 0x98B7 0x98DD 0x983A 0x982D 0x9810 0x981F 0x983C 0x979B 0x9788 0x9788 0x97A3 0x97B4 0x972A 0x972C 0x9722 0x9730 0x9734 0x96D1 0x96DD 0x96CD 0x96CA 0x96BF 0x968A 0x968B 0x967B 0x9667 0x9654 0x964D 0x963D 0x962B 0x9607 0x95F5 0x9610 0x95F0 0x95DF 0x95AF 0x959E 0x95D7 0x95A3 0x9594 0x9564 0x9550 0x959F 0x9560 0x954F 0x9520 0x9508 0x9569 0x9528 0x9514 0x94E0 0x94C5 0x9538 0x94F7 0x94E1 0x94A4 0x948A 0x950F 0x94CE 0x94B2 0x9469 0x9448 0x94EC 0x94AB 0x9489 0x9435 0x93FE 0x94BD 0x947E 0x9458 0x93F8 0x93AC 0x947C 0x9438 0x9405 0x93A1 0x9354 0x942A 0x93E0 0x9396 0x9332 0x92F3 0x93BB 0x9378 0x931F 0x92B9 0x9282 0x932D 0x92F8 0x929A 0x9232 0x91F9 0x928C 0x9258 0x91F8 0x9195 0x915A 0x91DF 0x91A5 0x9155 0x90F9 0x90BE 0x9138 0x9102 0x90E8 0x9099 0x9065 0x90FE 0x90C6 0x90CC 0x9083 0x904E 0x90BF 0x90A2 0x90B6 0x9073 0x903F 0x907F 0x9073 0x90A0 0x9059 0x9027 0x9024 0x9039 0x9065 0x8FF6 0x8FB8 0x8EF4 0x8FA5 0x8F6C 0x8EBD 0x8E73 0x7FA0 0x8E09 0x8DA3 0x8CDA 0x8C8C 0x7C55 0x7E1A 0x8B33 0x8A65 0x8A12 0x79F7 0x797D 0x87BA 0x86F9 0x869E 0x7754 0x7698 0x81EA 0x8167 0x810D 0x7530 0x7530 0x7530 0x7530 0x7530>;
                qcom,lut-row-legend = <0x2710 0x2648 0x2580 0x24B8 0x23F0 0x2328 0x2260 0x2198 0x20D0 0x2008 0x1F40 0x1E78 0x1DB0 0x1CE8 0x1C20 0x1B58 0x1A90 0x19C8 0x1900 0x1838 0x1770 0x16A8 0x15E0 0x1518 0x1450 0x1388 0x12C0 0x11F8 0x1130 0x1068 0xFA0 0xED8 0xE10 0xD48 0xC80 0xBB8 0xAF0 0xA28 0x960 0x898 0x7D0 0x708 0x640 0x578 0x4B0 0x3E8 0x384 0x320 0x2BC 0x258 0x1F4 0x190 0x12C 0xC8 0x64 0x0>;
            };
            qcom,pc-temp-v2-lut {
                qcom,lut-col-legend = <0xFFFFFFF6 0x0 0xA 0x19 0x28 0x32>;
                qcom,lut-data = <0xAFCD 0xAFBE 0xAFAA 0xAF6E 0xAF5A 0xAF46 0xADD1 0xADEE 0xADEE 0xADDA 0xADB6 0xADA2 0xAC2E 0xAC6F 0xAC7F 0xAC83 0xAC51 0xAC3B 0xAAFF 0xAB59 0xAB72 0xAB78 0xAB3C 0xAB23 0xAA20 0xAA8E 0xAAA9 0xAAA3 0xAA5D 0xAA42 0xA949 0xA9C4 0xA9DD 0xA9C6 0xA97B 0xA95F 0xA85F 0xA8E0 0xA8F9 0xA8D8 0xA88D 0xA871 0xA773 0xA7F4 0xA80D 0xA7E5 0xA79B 0xA77F 0xA681 0xA702 0xA719 0xA6EA 0xA6A1 0xA685 0xA587 0xA608 0xA61B 0xA5E9 0xA5A1 0xA586 0xA48E 0xA50F 0xA51D 0xA4E9 0xA4A2 0xA487 0xA395 0xA416 0xA420 0xA3E6 0xA3A3 0xA389 0xA29F 0xA31E 0xA326 0xA2E8 0xA2A7 0xA28F 0xA1BA 0xA22C 0xA231 0xA1EE 0xA1B0 0xA19C 0xA0E2 0xA13E 0xA142 0xA0F9 0xA0BF 0xA0AE 0xA005 0xA05A 0xA059 0xA00D 0x9FD7 0x9FC6 0x9F20 0x9F86 0x9F74 0x9F28 0x9EF5 0x9EE5 0x9E31 0x9EB7 0x9E98 0x9E4D 0x9E1D 0x9E0D 0x9D2E 0x9DE5 0x9DCC 0x9D7D 0x9D4F 0x9D3E 0x9C18 0x9D10 0x9D03 0x9CAD 0x9C86 0x9C77 0x9B12 0x9C26 0x9C1D 0x9BDE 0x9BC9 0x9BBF 0x9A21 0x9B0B 0x9B15 0x9B0C 0x9B0B 0x9B0B 0x993F 0x99F2 0x9A19 0x9A1F 0x9A27 0x9A2E 0x9865 0x9914 0x992E 0x9914 0x9914 0x991B 0x9796 0x9852 0x9859 0x9836 0x9835 0x9837 0x96E6 0x97A8 0x97AC 0x978F 0x9794 0x9797 0x9650 0x9712 0x971C 0x9702 0x970D 0x9710 0x95D1 0x9689 0x9699 0x9684 0x9693 0x9697 0x956D 0x960A 0x9621 0x9616 0x9625 0x962A 0x9519 0x9596 0x95B3 0x95AF 0x95C0 0x95C5 0x94CE 0x952B 0x954E 0x954E 0x9565 0x9567 0x948A 0x94C5 0x94F0 0x94F6 0x9512 0x9511 0x944B 0x946D 0x949A 0x94A7 0x94C9 0x94C8 0x940D 0x942C 0x944A 0x945E 0x9484 0x9483 0x93D1 0x93F8 0x9401 0x9419 0x9437 0x9433 0x9390 0x93C6 0x93C1 0x93D8 0x93E6 0x93D7 0x934A 0x9397 0x9385 0x9390 0x938C 0x9373 0x92FF 0x9365 0x9345 0x933D 0x9321 0x92FC 0x92AC 0x9326 0x92FF 0x92E5 0x92B7 0x9286 0x9251 0x92DC 0x92AF 0x928C 0x925E 0x9229 0x91EC 0x927C 0x9249 0x922C 0x9208 0x91D2 0x917A 0x91F8 0x91D1 0x91BE 0x919F 0x9165 0x9100 0x9166 0x9142 0x913D 0x9125 0x90E9 0x9081 0x90C7 0x909D 0x90A6 0x9099 0x905F 0x9015 0x9033 0x9012 0x9018 0x9010 0x8FDF 0x8FAC 0x8FC1 0x8FC5 0x8FEB 0x8FF6 0x8FC2 0x8F79 0x8F8E 0x8F9E 0x8FD1 0x8FE2 0x8FB0 0x8F42 0x8F5F 0x8F6B 0x8FA7 0x8FC5 0x8F96 0x8F34 0x8F2B 0x8F26 0x8F58 0x8F8B 0x8F58 0x8EDA 0x8EED 0x8E68 0x8E80 0x8EC2 0x8E90 0x8E38 0x8E84 0x8CE0 0x8CB1 0x8D10 0x8CD2 0x8DC1 0x8DAA 0x8A8F 0x8A1B 0x8AC1 0x8A94 0x8A4F 0x8DB4 0x8781 0x864E 0x87AF 0x8794 0x7A6A 0x8BFF 0x84A3 0x8218 0x8305 0x832B 0x7638 0x77C9 0x7EF6 0x8025 0x7BF3 0x7BA8 0x7244 0x728C 0x6DD8 0x718C 0x6BDD 0x6B8B>;
                qcom,lut-row-legend = <0x2710 0x2648 0x2580 0x24B8 0x23F0 0x2328 0x2260 0x2198 0x20D0 0x2008 0x1F40 0x1E78 0x1DB0 0x1CE8 0x1C20 0x1B58 0x1A90 0x19C8 0x1900 0x1838 0x1770 0x16A8 0x15E0 0x1518 0x1450 0x1388 0x12C0 0x11F8 0x1130 0x1068 0xFA0 0xED8 0xE10 0xD48 0xC80 0xBB8 0xAF0 0xA28 0x960 0x898 0x7D0 0x708 0x640 0x578 0x4B0 0x3E8 0x384 0x320 0x2BC 0x258 0x1F4 0x190 0x12C 0xC8 0x64 0x0>;
            };
            qcom,pc-temp-y1-lut {
                qcom,lut-col-legend = <0xFFFFFFF6 0x0 0xA 0x19 0x28 0x32>;
                qcom,lut-data = <0x15E5 0x142A 0x133A 0x127C 0x120C 0x11EC 0x15C9 0x1429 0x133D 0x127C 0x120D 0x11EB 0x15B5 0x1429 0x1341 0x127D 0x120D 0x11EB 0x15A8 0x1429 0x1344 0x127D 0x120D 0x11EB 0x15A1 0x1429 0x1346 0x127C 0x120D 0x11EA 0x15A0 0x142A 0x1347 0x127C 0x120D 0x11EA 0x15A8 0x142B 0x1346 0x127C 0x120B 0x11EB 0x15B2 0x142D 0x1345 0x127B 0x1209 0x11EB 0x15B6 0x142D 0x1345 0x127B 0x1208 0x11EB 0x15B7 0x142C 0x1345 0x127B 0x1207 0x11EA 0x15B8 0x142C 0x1344 0x127A 0x1207 0x11EA 0x15B8 0x142D 0x1344 0x127A 0x1207 0x11EA 0x15B8 0x142E 0x1342 0x127A 0x1207 0x11EA 0x15B8 0x142E 0x1342 0x127A 0x1207 0x11EB 0x15B9 0x142F 0x1341 0x1279 0x1207 0x11EC 0x15B9 0x142F 0x1340 0x1279 0x1208 0x11ED 0x15BB 0x142F 0x1340 0x1279 0x1209 0x11EF 0x15BE 0x142F 0x1340 0x1279 0x120A 0x11EF 0x15C1 0x1430 0x1340 0x1277 0x120A 0x11EE 0x15C4 0x1432 0x1340 0x1276 0x120A 0x11ED 0x15C6 0x1435 0x1340 0x1278 0x120A 0x11ED 0x15C8 0x1439 0x1340 0x127C 0x120A 0x11EF 0x15C9 0x143E 0x1341 0x127E 0x120B 0x11F0 0x15C6 0x1443 0x1343 0x127E 0x120D 0x11F1 0x15C1 0x1447 0x1344 0x127F 0x120E 0x11F2 0x15BE 0x1447 0x1344 0x1283 0x1210 0x11F2 0x15BD 0x1447 0x1342 0x1287 0x1211 0x11F2 0x15BB 0x1447 0x1342 0x1287 0x1212 0x11F3 0x15B1 0x1448 0x1349 0x1286 0x1212 0x11F5 0x15A6 0x1449 0x1350 0x1286 0x1213 0x11F7 0x15A2 0x1447 0x134C 0x1286 0x1215 0x11F8 0x15A0 0x1441 0x1343 0x1287 0x1218 0x11F9 0x15A0 0x143C 0x1341 0x1288 0x121A 0x11FA 0x15AF 0x1438 0x1343 0x128A 0x121B 0x11FC 0x15BF 0x1434 0x1344 0x128D 0x121D 0x11FD 0x15C0 0x1431 0x1345 0x1293 0x121D 0x11FF 0x15BE 0x142F 0x1345 0x1296 0x121F 0x1201 0x15BB 0x142E 0x1347 0x1294 0x1221 0x1202 0x15B6 0x142F 0x134F 0x1292 0x1223 0x1203 0x15B2 0x142F 0x1354 0x1291 0x1224 0x1203 0x15B2 0x142C 0x1354 0x1290 0x1225 0x1202 0x15B3 0x142B 0x1354 0x1297 0x1226 0x1203 0x15A4 0x142E 0x1349 0x129C 0x1226 0x1207 0x1596 0x142B 0x134A 0x129E 0x1229 0x1208 0x15AF 0x1432 0x1355 0x129A 0x1228 0x1208 0x15C3 0x1433 0x1361 0x129B 0x122C 0x120A 0x15BE 0x1439 0x1350 0x12A4 0x122E 0x120B 0x15C9 0x1441 0x1350 0x12A2 0x122D 0x120A 0x15E0 0x145F 0x135D 0x12A4 0x122E 0x120C 0x1631 0x1467 0x1360 0x12AC 0x1230 0x120C 0x1684 0x1486 0x136E 0x12B4 0x1232 0x120D 0x16F6 0x14C7 0x1377 0x12C1 0x1238 0x1213 0x17D7 0x154C 0x1395 0x12C3 0x123F 0x121A 0x17D8 0x15E1 0x13E0 0x12E1 0x124E 0x1225 0x17D8 0x15E1 0x13E0 0x12E1 0x124E 0x1225 0x17D8 0x15E1 0x13E0 0x12E1 0x124E 0x1225>;
                qcom,lut-row-legend = <0x2710 0x2648 0x2580 0x24B8 0x23F0 0x2328 0x2260 0x2198 0x20D0 0x2008 0x1F40 0x1E78 0x1DB0 0x1CE8 0x1C20 0x1B58 0x1A90 0x19C8 0x1900 0x1838 0x1770 0x16A8 0x15E0 0x1518 0x1450 0x1388 0x12C0 0x11F8 0x1130 0x1068 0xFA0 0xED8 0xE10 0xD48 0xC80 0xBB8 0xAF0 0xA28 0x960 0x898 0x7D0 0x708 0x640 0x578 0x4B0 0x3E8 0x384 0x320 0x2BC 0x258 0x1F4 0x190 0x12C 0xC8 0x64 0x0>;
            };
            qcom,pc-temp-y2-lut {
                qcom,lut-col-legend = <0xFFFFFFF6 0x0 0xA 0x19 0x28 0x32>;
                qcom,lut-data = <0x28B5 0x2B94 0x2CB3 0x2EBC 0x2F5A 0x2EF0 0x28F9 0x2B96 0x2CAD 0x2E66 0x2F2C 0x2F6A 0x294D 0x2B94 0x2CA1 0x2E13 0x2EF4 0x2F9B 0x29A2 0x2B91 0x2C8F 0x2DC6 0x2EB4 0x2F97 0x29E8 0x2B8B 0x2C79 0x2D84 0x2E6C 0x2F6F 0x2A0D 0x2B84 0x2C5F 0x2D53 0x2E1C 0x2F30 0x2A1C 0x2B7A 0x2C3C 0x2D2D 0x2DAA 0x2E99 0x2A26 0x2B70 0x2C1B 0x2D0F 0x2D5D 0x2E05 0x2A32 0x2B65 0x2C0B 0x2CF7 0x2D78 0x2DC3 0x2A3E 0x2B5A 0x2C00 0x2CE4 0x2DB0 0x2D97 0x2A4E 0x2B58 0x2BFD 0x2CDE 0x2DB5 0x2D92 0x2A65 0x2B69 0x2C04 0x2CDB 0x2D8A 0x2DA6 0x2A82 0x2B80 0x2C11 0x2CDB 0x2D71 0x2DBD 0x2AA8 0x2B95 0x2C2A 0x2D0C 0x2D82 0x2DD2 0x2AD4 0x2BAC 0x2C55 0x2D5F 0x2DA2 0x2DEB 0x2AF5 0x2BC7 0x2C85 0x2DA3 0x2DC0 0x2E1E 0x2B0C 0x2BEB 0x2CBF 0x2DE6 0x2DE4 0x2E75 0x2B1E 0x2C0A 0x2CEE 0x2E2D 0x2E15 0x2EB7 0x2B2D 0x2C23 0x2D0D 0x2E7B 0x2E60 0x2EDB 0x2B38 0x2C34 0x2D22 0x2EC0 0x2EC0 0x2F09 0x2B3C 0x2C38 0x2D22 0x2EFC 0x2F67 0x2F98 0x2B3E 0x2C39 0x2D16 0x2F28 0x3015 0x3051 0x2B3E 0x2C3C 0x2D10 0x2F02 0x301C 0x306B 0x29A5 0x2C5D 0x2D1B 0x2E4F 0x2FC3 0x3044 0x2702 0x2C81 0x2D2D 0x2DFF 0x2F76 0x301D 0x2651 0x2C85 0x2D40 0x2E3A 0x2F3E 0x2FFC 0x2629 0x2C86 0x2D57 0x2E7B 0x2F1B 0x2FE4 0x2611 0x2C87 0x2D70 0x2E87 0x2F72 0x3024 0x25FF 0x2C88 0x2D93 0x2E8C 0x3043 0x30F2 0x25F2 0x2C89 0x2DAB 0x2EA2 0x3074 0x31A2 0x25EA 0x2C8B 0x2DAE 0x2EFE 0x302A 0x3246 0x25E4 0x2C8E 0x2DAF 0x2F47 0x2FF8 0x329D 0x25DF 0x2C86 0x2DAF 0x2F63 0x30B9 0x329B 0x25DA 0x2C45 0x2DA8 0x2F73 0x31CB 0x3293 0x25D6 0x2BF5 0x2D9D 0x2F74 0x31D9 0x326B 0x25D2 0x2BB9 0x2D89 0x2F74 0x3185 0x31E9 0x25CE 0x2B6B 0x2D68 0x2F72 0x310E 0x319D 0x25CB 0x2A62 0x2D3B 0x2F5D 0x301B 0x318F 0x25C8 0x27C9 0x2CF7 0x2F37 0x2F67 0x3181 0x25C7 0x2659 0x2CA4 0x2EC6 0x2FAC 0x310F 0x25C5 0x2612 0x2C39 0x2E5D 0x300A 0x3052 0x25C3 0x25EE 0x2BBD 0x2E68 0x2FDB 0x3016 0x25C0 0x25DC 0x2B35 0x2E7F 0x2F20 0x2F89 0x25BF 0x25CF 0x2844 0x2E3B 0x2FE2 0x2F55 0x25C3 0x25C7 0x27B8 0x2D74 0x2EC7 0x2FCA 0x2624 0x25BE 0x2662 0x2D07 0x2E70 0x2E6F 0x25C7 0x25C6 0x25FC 0x2CE8 0x2E30 0x2DEC 0x25BF 0x2638 0x25D2 0x2CA6 0x2DE8 0x2DD3 0x25B9 0x25DB 0x25C0 0x2C3C 0x2D82 0x2D4C 0x25BA 0x25C2 0x25E1 0x2B7D 0x2D60 0x2D8D 0x25B4 0x25B8 0x25E4 0x2A4C 0x2CE3 0x2D04 0x25B3 0x25B4 0x25CC 0x28BE 0x2C8F 0x2CDE 0x25B3 0x25B4 0x25B9 0x272F 0x2C5B 0x2CFC 0x25B3 0x25B4 0x25B7 0x266B 0x2BD0 0x2C94 0x25B3 0x25B4 0x25B7 0x266B 0x2BD0 0x2C94 0x25B3 0x25B4 0x25B7 0x266B 0x2BD0 0x2C94>;
                qcom,lut-row-legend = <0x2710 0x2648 0x2580 0x24B8 0x23F0 0x2328 0x2260 0x2198 0x20D0 0x2008 0x1F40 0x1E78 0x1DB0 0x1CE8 0x1C20 0x1B58 0x1A90 0x19C8 0x1900 0x1838 0x1770 0x16A8 0x15E0 0x1518 0x1450 0x1388 0x12C0 0x11F8 0x1130 0x1068 0xFA0 0xED8 0xE10 0xD48 0xC80 0xBB8 0xAF0 0xA28 0x960 0x898 0x7D0 0x708 0x640 0x578 0x4B0 0x3E8 0x384 0x320 0x2BC 0x258 0x1F4 0x190 0x12C 0xC8 0x64 0x0>;
            };
            qcom,pc-temp-y3-lut {
                qcom,lut-col-legend = <0xFFFFFFF6 0x0 0xA 0x19 0x28 0x32>;
                qcom,lut-data = <0x3477 0x341C 0x3402 0x33DF 0x33DF 0x33DE 0x3478 0x3421 0x3403 0x33E3 0x33DB 0x33D9 0x347C 0x3425 0x3405 0x33E6 0x33D9 0x33D7 0x3480 0x342A 0x3406 0x33E8 0x33D8 0x33D5 0x3483 0x342D 0x3407 0x33E9 0x33D7 0x33D4 0x3484 0x3430 0x3409 0x33E9 0x33D7 0x33D4 0x3484 0x3432 0x340A 0x33E8 0x33D8 0x33D6 0x3484 0x3433 0x340B 0x33E7 0x33D9 0x33D7 0x3483 0x3433 0x340B 0x33E8 0x33DC 0x33D8 0x3482 0x3433 0x340A 0x33EB 0x33E0 0x33D9 0x3480 0x3432 0x340A 0x33ED 0x33E1 0x33D9 0x347D 0x3432 0x340A 0x33EE 0x33E2 0x33DA 0x347C 0x3431 0x340A 0x33EE 0x33E3 0x33DA 0x347B 0x342F 0x340B 0x33EE 0x33E3 0x33DD 0x347A 0x342E 0x340B 0x33EE 0x33E3 0x33E0 0x3479 0x342E 0x340B 0x33EF 0x33E4 0x33E0 0x3474 0x342F 0x3408 0x33F0 0x33E7 0x33E0 0x346C 0x3430 0x3406 0x33F0 0x33E8 0x33E0 0x3465 0x342E 0x3407 0x33EF 0x33E7 0x33DF 0x345E 0x342B 0x3409 0x33EE 0x33E7 0x33DE 0x3458 0x3427 0x3408 0x33EF 0x33E7 0x33E0 0x3452 0x3423 0x3406 0x33F0 0x33E7 0x33E4 0x344C 0x341F 0x3403 0x33EF 0x33E6 0x33E3 0x343F 0x341A 0x33FE 0x33EA 0x33DD 0x33DA 0x3432 0x3416 0x33FB 0x33E6 0x33D9 0x33D5 0x3430 0x3414 0x33FB 0x33E3 0x33D9 0x33D5 0x3432 0x3412 0x33FB 0x33E1 0x33D9 0x33D5 0x3435 0x3411 0x33FA 0x33E2 0x33D8 0x33D5 0x3438 0x3410 0x33F9 0x33E4 0x33D8 0x33D7 0x343D 0x340E 0x33F8 0x33E5 0x33D8 0x33D7 0x3445 0x3409 0x33F9 0x33E6 0x33D9 0x33D6 0x3453 0x3401 0x33F9 0x33E6 0x33D9 0x33D5 0x3463 0x3400 0x33F9 0x33E6 0x33DA 0x33D6 0x3475 0x3405 0x33F9 0x33E7 0x33DB 0x33D8 0x348A 0x340B 0x33F9 0x33E7 0x33DB 0x33D8 0x34A5 0x3411 0x33F9 0x33E6 0x33DB 0x33D7 0x34C6 0x3416 0x33FA 0x33E6 0x33DA 0x33D6 0x34EE 0x341A 0x33FB 0x33E5 0x33D8 0x33D6 0x3522 0x341D 0x33FC 0x33E5 0x33D7 0x33D5 0x3562 0x3423 0x33FE 0x33E3 0x33D7 0x33D5 0x35AF 0x3431 0x33FF 0x33E2 0x33D8 0x33D7 0x3616 0x3447 0x3401 0x33E4 0x33D9 0x33D5 0x36A6 0x346F 0x3402 0x33E4 0x33DA 0x33D5 0x379F 0x34A2 0x33FE 0x33E1 0x33DA 0x33D7 0x3951 0x3505 0x33FF 0x33E0 0x33D6 0x33D5 0x3B7B 0x3690 0x341E 0x33EA 0x33DD 0x33D7 0x3547 0x3990 0x3443 0x33EF 0x33DE 0x33DA 0x35AD 0x3B38 0x3499 0x33F3 0x33E1 0x33DF 0x3775 0x3568 0x35C2 0x33FA 0x33E5 0x33DF 0x41D2 0x36B6 0x3A0E 0x33FE 0x33E5 0x33DD 0x7714 0x4630 0x3497 0x3403 0x33E2 0x33DC 0xE122 0x67DA 0x35CD 0x3422 0x33E3 0x33DF 0xFFFF 0xA1F5 0x3CD8 0x3528 0x33E7 0x33E1 0xFFFF 0xF56B 0x4A25 0x3459 0x33EE 0x33E5 0xFFFF 0xF56B 0x4A25 0x3459 0x33EE 0x33E5 0xFFFF 0xF56B 0x4A25 0x3459 0x33EE 0x33E5>;
                qcom,lut-row-legend = <0x2710 0x2648 0x2580 0x24B8 0x23F0 0x2328 0x2260 0x2198 0x20D0 0x2008 0x1F40 0x1E78 0x1DB0 0x1CE8 0x1C20 0x1B58 0x1A90 0x19C8 0x1900 0x1838 0x1770 0x16A8 0x15E0 0x1518 0x1450 0x1388 0x12C0 0x11F8 0x1130 0x1068 0xFA0 0xED8 0xE10 0xD48 0xC80 0xBB8 0xAF0 0xA28 0x960 0x898 0x7D0 0x708 0x640 0x578 0x4B0 0x3E8 0x384 0x320 0x2BC 0x258 0x1F4 0x190 0x12C 0xC8 0x64 0x0>;
            };
            qcom,pc-temp-y4-lut {
                qcom,lut-col-legend = <0xFFFFFFF6 0x0 0xA 0x19 0x28 0x32>;
                qcom,lut-data = <0x411B 0x40BA 0x4097 0x4080 0x4052 0x4047 0x4137 0x40C7 0x409E 0x4070 0x404E 0x4044 0x4162 0x40DC 0x40A4 0x4065 0x404A 0x4041 0x4190 0x40F4 0x40A9 0x405D 0x4046 0x403E 0x41B5 0x4106 0x40AC 0x4059 0x4043 0x403C 0x41C6 0x410C 0x40AD 0x4058 0x4043 0x403A 0x41CB 0x410B 0x40AB 0x405D 0x4044 0x4039 0x41CD 0x4109 0x40A8 0x4062 0x4045 0x4038 0x41CF 0x4106 0x40A8 0x4065 0x4044 0x4039 0x41D0 0x4104 0x40A9 0x4066 0x4041 0x403C 0x41D1 0x4103 0x40A9 0x4069 0x4041 0x403E 0x41D9 0x410A 0x40AD 0x406F 0x4045 0x4042 0x41E5 0x4115 0x40B3 0x4077 0x404B 0x4044 0x41F0 0x4124 0x40BB 0x4080 0x4052 0x4044 0x41FB 0x4139 0x40C6 0x408A 0x4059 0x4045 0x41FD 0x414F 0x40D5 0x4094 0x405D 0x4047 0x41EA 0x4167 0x40EB 0x409F 0x4060 0x404D 0x41CD 0x4174 0x4103 0x40AE 0x4065 0x4055 0x41AB 0x416A 0x411F 0x40C8 0x4070 0x405F 0x4181 0x4154 0x4137 0x40D9 0x407E 0x406A 0x415D 0x4134 0x4131 0x40DB 0x4091 0x4075 0x413A 0x4101 0x4107 0x40DB 0x40A4 0x407F 0x4128 0x40D9 0x40DA 0x40CB 0x409C 0x407A 0x4130 0x40BF 0x40A9 0x4086 0x406D 0x405B 0x413E 0x40AD 0x4083 0x4062 0x4051 0x4047 0x413C 0x40A8 0x407A 0x405D 0x404A 0x4042 0x4129 0x40A5 0x4075 0x405B 0x4047 0x403F 0x411F 0x40A2 0x4074 0x405D 0x4049 0x4040 0x411F 0x409D 0x4077 0x4063 0x404F 0x4043 0x4120 0x409A 0x407A 0x406A 0x4056 0x4047 0x4120 0x409B 0x407F 0x4071 0x4060 0x4050 0x4120 0x409C 0x4083 0x4078 0x4069 0x405A 0x4120 0x409E 0x4085 0x4081 0x4073 0x4062 0x4124 0x409F 0x4087 0x408A 0x407A 0x4069 0x412B 0x40A1 0x4088 0x408F 0x4079 0x4068 0x4131 0x40AA 0x408C 0x4092 0x4073 0x4062 0x4138 0x40B9 0x4093 0x4092 0x406A 0x405A 0x413E 0x40CF 0x409B 0x4083 0x4059 0x404D 0x4147 0x40EF 0x40A6 0x4073 0x404D 0x4042 0x414D 0x40FC 0x40AB 0x406F 0x404D 0x4040 0x414B 0x40FD 0x40A9 0x406D 0x404D 0x403F 0x4149 0x40FD 0x40A5 0x406D 0x404C 0x4040 0x414B 0x40FA 0x409D 0x406C 0x404C 0x4041 0x414B 0x40F7 0x40B0 0x4062 0x4046 0x403D 0x4140 0x40E3 0x40A3 0x4056 0x403B 0x4031 0x4016 0x40F1 0x40AC 0x4062 0x4045 0x4040 0x5292 0x40ED 0x40BF 0x406F 0x404E 0x4044 0x5546 0x402F 0x40DD 0x4080 0x4053 0x4043 0x63B3 0x55C9 0x410A 0x409A 0x4060 0x405B 0x4529 0x43EF 0x4125 0x4097 0x4053 0x4057 0x521A 0x45A7 0x5124 0x409A 0x4045 0x403E 0x5E22 0x501C 0x42AC 0x40D8 0x4048 0x4041 0x4107 0x67DC 0x4456 0x41FC 0x4055 0x404C 0x4202 0xAA02 0x4C8E 0x4C76 0x407A 0x4075 0x4202 0xAA02 0x4C8E 0x4C76 0x407A 0x4075 0x4202 0xAA02 0x4C8E 0x4C76 0x407A 0x4075>;
                qcom,lut-row-legend = <0x2710 0x2648 0x2580 0x24B8 0x23F0 0x2328 0x2260 0x2198 0x20D0 0x2008 0x1F40 0x1E78 0x1DB0 0x1CE8 0x1C20 0x1B58 0x1A90 0x19C8 0x1900 0x1838 0x1770 0x16A8 0x15E0 0x1518 0x1450 0x1388 0x12C0 0x11F8 0x1130 0x1068 0xFA0 0xED8 0xE10 0xD48 0xC80 0xBB8 0xAF0 0xA28 0x960 0x898 0x7D0 0x708 0x640 0x578 0x4B0 0x3E8 0x384 0x320 0x2BC 0x258 0x1F4 0x190 0x12C 0xC8 0x64 0x0>;
            };
            qcom,pc-temp-y5-lut {
                qcom,lut-col-legend = <0xFFFFFFF6 0x0 0xA 0x19 0x28 0x32>;
                qcom,lut-data = <0x36F1 0x451C 0x51BB 0x50DC 0x55F5 0x5A68 0x3A78 0x467D 0x5250 0x5314 0x524F 0x55E2 0x3E5B 0x4925 0x526F 0x5408 0x4CD8 0x504A 0x4217 0x4C21 0x5231 0x53ED 0x4717 0x4AEF 0x452C 0x4E7B 0x51B2 0x52FC 0x4294 0x471E 0x471B 0x4F45 0x510A 0x50FC 0x40BC 0x461C 0x4856 0x4F36 0x5037 0x476C 0x4020 0x4728 0x4911 0x4F11 0x4EFE 0x3F3E 0x3FDC 0x4825 0x48E1 0x4DF8 0x4C4C 0x3F98 0x4393 0x476B 0x4811 0x4AD2 0x478E 0x40B3 0x4B01 0x456D 0x47BB 0x47F6 0x442E 0x40A0 0x4C35 0x4379 0x4817 0x4545 0x421F 0x3EA1 0x494E 0x4135 0x48D8 0x4374 0x4081 0x3C70 0x45E6 0x4029 0x4B08 0x42F2 0x3F29 0x3A40 0x4203 0x4412 0x4F6E 0x42A9 0x3E09 0x389E 0x3EF8 0x4910 0x52AD 0x4346 0x3CF9 0x3879 0x3F86 0x487A 0x5525 0x4832 0x3BD5 0x3874 0x41C0 0x4497 0x5684 0x4E2E 0x3B4A 0x3879 0x4236 0x40BB 0x5696 0x5446 0x3EF1 0x38D0 0x3F20 0x3C7A 0x569E 0x59CE 0x4663 0x3987 0x3CB2 0x39ED 0x5690 0x5BE7 0x4E77 0x40EF 0x3EB9 0x3E75 0x55FB 0x5D07 0x5890 0x4D74 0x4325 0x46EB 0x54D7 0x5D47 0x5C94 0x535F 0x472E 0x4955 0x4AE9 0x59A1 0x598E 0x56FD 0x4B7F 0x49FC 0x3B91 0x551B 0x5626 0x57C8 0x4D23 0x4A29 0x36E5 0x53CE 0x5651 0x4EFA 0x4CE0 0x4920 0x3584 0x5325 0x5787 0x461D 0x4C4C 0x47F1 0x347D 0x52D1 0x57C7 0x4740 0x4A2E 0x4834 0x3353 0x52B2 0x556A 0x4AD3 0x4605 0x4922 0x327F 0x5287 0x5357 0x4C75 0x43D4 0x48D9 0x32AB 0x4C5C 0x552C 0x4CFF 0x42B1 0x4323 0x33B9 0x408B 0x58F4 0x4D92 0x423C 0x3ECE 0x3499 0x3E5D 0x5A01 0x4E7C 0x4455 0x40BE 0x3518 0x4294 0x5A1E 0x4F97 0x4831 0x44E1 0x3581 0x4797 0x5A27 0x50FF 0x4B3F 0x48C6 0x35E2 0x4CD7 0x58C6 0x52B2 0x4E20 0x4D0D 0x363B 0x5143 0x5697 0x533A 0x4EEA 0x4EA2 0x368D 0x4EF2 0x55E3 0x52EE 0x4C8C 0x4DFD 0x36E1 0x4363 0x55AA 0x5249 0x4953 0x4D55 0x3724 0x3C2D 0x5536 0x4C95 0x4679 0x4DAD 0x3751 0x3A16 0x5302 0x4653 0x449E 0x4E43 0x376A 0x3981 0x4FC0 0x4719 0x467E 0x4657 0x3506 0x39E7 0x4B70 0x4627 0x462B 0x4211 0x33CA 0x35F3 0x3C02 0x4516 0x48BA 0x47F2 0x32BF 0x355A 0x3878 0x444C 0x452F 0x4ED5 0xFFFF 0x34E6 0x39AE 0x49E5 0x4B1F 0x4263 0x38BA 0x3801 0x37ED 0x488E 0x43E2 0x440B 0x2502 0xFFFF 0x36F3 0x4715 0x43B0 0x528B 0x26D7 0xE9BB 0x359D 0x490F 0x519C 0x5183 0x2702 0x2EA5 0x43D2 0x4C91 0x58C5 0x508D 0x241A 0x2716 0x279F 0x4A88 0x54EA 0x53E3 0x2654 0x2463 0x364B 0x4489 0x548C 0x6323 0x5B57 0x2394 0x2B13 0x34C1 0x628A 0x6B13 0x49EE 0x22F1 0x253F 0x2A80 0x629C 0x6798 0x49EE 0x22F1 0x253F 0x2A80 0x629C 0x6798 0x49EE 0x22F1 0x253F 0x2A80 0x629C 0x6798>;
                qcom,lut-row-legend = <0x2710 0x2648 0x2580 0x24B8 0x23F0 0x2328 0x2260 0x2198 0x20D0 0x2008 0x1F40 0x1E78 0x1DB0 0x1CE8 0x1C20 0x1B58 0x1A90 0x19C8 0x1900 0x1838 0x1770 0x16A8 0x15E0 0x1518 0x1450 0x1388 0x12C0 0x11F8 0x1130 0x1068 0xFA0 0xED8 0xE10 0xD48 0xC80 0xBB8 0xAF0 0xA28 0x960 0x898 0x7D0 0x708 0x640 0x578 0x4B0 0x3E8 0x384 0x320 0x2BC 0x258 0x1F4 0x190 0x12C 0xC8 0x64 0x0>;
            };
            qcom,pc-temp-y6-lut {
                qcom,lut-col-legend = <0xFFFFFFF6 0x0 0xA 0x19 0x28 0x32>;
                qcom,lut-data = <0x15A4 0x145B 0x13DD 0x137A 0x1358 0x1351 0x15AB 0x1466 0x13DE 0x1379 0x1357 0x1350 0x15B0 0x146D 0x13DF 0x1377 0x1356 0x134F 0x15B2 0x1471 0x13DF 0x1376 0x1355 0x134E 0x15B3 0x1472 0x13DE 0x1375 0x1354 0x134E 0x15B3 0x1472 0x13DD 0x1375 0x1354 0x134E 0x15B0 0x146F 0x13DB 0x1374 0x1354 0x134E 0x15A9 0x1469 0x13D7 0x1374 0x1355 0x134F 0x15A3 0x1464 0x13D4 0x1374 0x1355 0x134F 0x159C 0x1460 0x13D0 0x1374 0x1355 0x1350 0x1598 0x145D 0x13CE 0x1375 0x1356 0x1350 0x1596 0x1459 0x13CC 0x1375 0x1357 0x1351 0x1595 0x1456 0x13CB 0x1377 0x1358 0x1352 0x1596 0x1456 0x13CC 0x1378 0x1359 0x1353 0x1599 0x1458 0x13CD 0x1379 0x135B 0x1354 0x159B 0x145B 0x13D0 0x137C 0x135C 0x1355 0x1599 0x1464 0x13D3 0x137F 0x135E 0x1356 0x1596 0x146D 0x13D8 0x1383 0x1361 0x1358 0x158E 0x146E 0x13E1 0x1389 0x1363 0x135A 0x157B 0x146E 0x13EB 0x138F 0x1366 0x135D 0x156B 0x146D 0x13EA 0x1393 0x136A 0x1360 0x155F 0x1459 0x13DE 0x1396 0x1371 0x1366 0x1554 0x143F 0x13D1 0x1396 0x1374 0x1368 0x154A 0x1435 0x13C2 0x1386 0x1368 0x135F 0x1540 0x142E 0x13B7 0x1374 0x135A 0x1354 0x153C 0x142C 0x13B4 0x1372 0x1358 0x1352 0x153F 0x142B 0x13B3 0x1371 0x1357 0x1352 0x1543 0x142B 0x13B3 0x1371 0x1357 0x1352 0x154A 0x142B 0x13B4 0x1372 0x1358 0x1353 0x1557 0x142C 0x13B6 0x1373 0x1359 0x1354 0x1566 0x142D 0x13B7 0x1375 0x135A 0x1355 0x1578 0x142E 0x13B9 0x1378 0x135C 0x1356 0x158C 0x1430 0x13BB 0x137B 0x135E 0x1357 0x15A1 0x1435 0x13BC 0x137D 0x1361 0x135A 0x15B8 0x1442 0x13BE 0x137E 0x1362 0x135B 0x15D2 0x144F 0x13C0 0x137E 0x1361 0x1359 0x15F1 0x145D 0x13C3 0x137E 0x135E 0x1356 0x1613 0x146E 0x13C7 0x137C 0x135C 0x1354 0x163B 0x1480 0x13CB 0x1377 0x1359 0x1353 0x1667 0x1493 0x13CF 0x1375 0x1358 0x1353 0x1697 0x14A7 0x13D5 0x1376 0x1359 0x1354 0x16CB 0x14BB 0x13DD 0x1377 0x135A 0x1355 0x170A 0x14D5 0x13E9 0x1378 0x1359 0x1354 0x175C 0x14F9 0x13F4 0x1378 0x1359 0x1353 0x17D1 0x152B 0x13F5 0x1375 0x1356 0x1351 0x1867 0x1562 0x1413 0x137C 0x135A 0x1354 0x18E4 0x159D 0x142B 0x1380 0x135C 0x1356 0x1975 0x15EA 0x144F 0x1388 0x1361 0x135C 0x1A44 0x1656 0x1488 0x1391 0x136E 0x1369 0x1BF5 0x16FF 0x14CE 0x1390 0x1365 0x1360 0x21AD 0x1823 0x1545 0x138D 0x135F 0x135A 0x2DCD 0x1970 0x16A5 0x1397 0x1363 0x135D 0x5694 0x1ED0 0x190A 0x13A9 0x1367 0x1361 0x5B44 0x3267 0x2507 0x13DA 0x1379 0x1375 0x5B44 0x3267 0x2507 0x13DA 0x1379 0x1375 0x5B44 0x3267 0x2507 0x13DA 0x1379 0x1375>;
                qcom,lut-row-legend = <0x2710 0x2648 0x2580 0x24B8 0x23F0 0x2328 0x2260 0x2198 0x20D0 0x2008 0x1F40 0x1E78 0x1DB0 0x1CE8 0x1C20 0x1B58 0x1A90 0x19C8 0x1900 0x1838 0x1770 0x16A8 0x15E0 0x1518 0x1450 0x1388 0x12C0 0x11F8 0x1130 0x1068 0xFA0 0xED8 0xE10 0xD48 0xC80 0xBB8 0xAF0 0xA28 0x960 0x898 0x7D0 0x708 0x640 0x578 0x4B0 0x3E8 0x384 0x320 0x2BC 0x258 0x1F4 0x190 0x12C 0xC8 0x64 0x0>;
            };
            qcom,pc-temp-z1-lut {
                qcom,lut-col-legend = <0x0 0xA 0x19 0x28 0x32>;
                qcom,lut-data = <0x2CB1 0x2AE9 0x2999 0x28F4 0x28A9 0x2CDE 0x2B24 0x29D4 0x2926 0x28EF 0x2CDF 0x2B22 0x29D7 0x2928 0x28F0 0x2CE0 0x2B2C 0x29D2 0x2920 0x28EB 0x2CE9 0x2B33 0x29D3 0x291E 0x28EB 0x2CFC 0x2B37 0x29D3 0x291E 0x28EB 0x2D00 0x2B3A 0x29D0 0x291E 0x28EB 0x2CED 0x2B38 0x29CC 0x291E 0x28EC 0x2CD9 0x2B32 0x29C7 0x291D 0x28EC 0x2CD1 0x2B2D 0x29C3 0x291A 0x28ED 0x2CCB 0x2B26 0x29C3 0x2919 0x28ED 0x2CC6 0x2B21 0x29C3 0x2919 0x28ED 0x2CC2 0x2B1E 0x29C4 0x291A 0x28EE 0x2CC0 0x2B1C 0x29C4 0x291A 0x28EE 0x2CCA 0x2B1C 0x29C4 0x291B 0x28F1 0x2CDD 0x2B1E 0x29C6 0x291D 0x28F3 0x2CDE 0x2B1F 0x29CB 0x291F 0x28F5 0x2CD2 0x2B1D 0x29D0 0x2922 0x28F7 0x2CCB 0x2B1B 0x29D6 0x2924 0x28F9 0x2CCC 0x2B1D 0x29D9 0x2927 0x28FC 0x2CD0 0x2B26 0x29D9 0x292A 0x28FF 0x2CD4 0x2B2D 0x29D9 0x292D 0x2903 0x2CD9 0x2B33 0x29D9 0x292F 0x2904 0x2CDB 0x2B37 0x29DC 0x2930 0x2904 0x2CD7 0x2B37 0x29DF 0x2931 0x2905 0x2CD1 0x2B36 0x29E4 0x2934 0x2906 0x2CD5 0x2B36 0x29E8 0x2939 0x2909 0x2CE5 0x2B3C 0x29EB 0x293C 0x290C 0x2CEC 0x2B40 0x29EF 0x293F 0x2910 0x2CE7 0x2B40 0x29F2 0x2942 0x2913 0x2CE1 0x2B3E 0x29F5 0x2945 0x2916 0x2CE2 0x2B3F 0x29F9 0x2948 0x2919 0x2CE7 0x2B47 0x2A01 0x294D 0x291B 0x2CE8 0x2B4B 0x2A07 0x2952 0x291D 0x2CDF 0x2B4A 0x2A08 0x2953 0x2920 0x2CD6 0x2B48 0x2A07 0x2953 0x2923 0x2CDF 0x2B48 0x2A07 0x2953 0x2926 0x2CF7 0x2B49 0x2A0B 0x2958 0x2927 0x2CFF 0x2B4B 0x2A11 0x295D 0x2928 0x2CF7 0x2B4B 0x2A19 0x2960 0x292A 0x2CF1 0x2B4C 0x2A23 0x2962 0x292C 0x2CF9 0x2B51 0x2A26 0x2965 0x292E 0x2D05 0x2B5B 0x2A27 0x296A 0x2930 0x2D06 0x2B6B 0x2A2B 0x296C 0x2933 0x2D06 0x2B70 0x2A30 0x296D 0x2935 0x2D15 0x2B65 0x2A33 0x2971 0x2938 0x2D28 0x2B69 0x2A37 0x2972 0x2939 0x2D04 0x2B59 0x2A35 0x2974 0x2939 0x2D04 0x2B5E 0x2A35 0x2977 0x293A 0x2CFD 0x2B5F 0x2A3E 0x297A 0x293D 0x2CFC 0x2B62 0x2A3E 0x297D 0x2941 0x2D08 0x2B5B 0x2A49 0x2981 0x2947 0x2D0E 0x2B57 0x2A57 0x298D 0x294E 0x2D0E 0x2B60 0x2A69 0x299A 0x2959 0x2D0E 0x2B60 0x2A69 0x299A 0x2959 0x2D0E 0x2B60 0x2A69 0x299A 0x2959>;
                qcom,lut-row-legend = <0x2710 0x2648 0x2580 0x24B8 0x23F0 0x2328 0x2260 0x2198 0x20D0 0x2008 0x1F40 0x1E78 0x1DB0 0x1CE8 0x1C20 0x1B58 0x1A90 0x19C8 0x1900 0x1838 0x1770 0x16A8 0x15E0 0x1518 0x1450 0x1388 0x12C0 0x11F8 0x1130 0x1068 0xFA0 0xED8 0xE10 0xD48 0xC80 0xBB8 0xAF0 0xA28 0x960 0x898 0x7D0 0x708 0x640 0x578 0x4B0 0x3E8 0x384 0x320 0x2BC 0x258 0x1F4 0x190 0x12C 0xC8 0x64 0x0>;
            };
            qcom,pc-temp-z2-lut {
                qcom,lut-col-legend = <0x0 0xA 0x19 0x28 0x32>;
                qcom,lut-data = <0x2654 0x29B4 0x2A70 0x2A32 0x2A31 0x2932 0x2A2E 0x2AA7 0x2B73 0x2A5A 0x2945 0x2A34 0x2ACF 0x2BE0 0x2AD6 0x2956 0x29F0 0x2A81 0x2B4A 0x2C09 0x2944 0x29B4 0x2A44 0x2B09 0x2BC7 0x2911 0x297F 0x2A08 0x2AF5 0x2B95 0x28E6 0x2953 0x29C3 0x2AF4 0x2BA3 0x28C1 0x292E 0x29A1 0x2AF4 0x2BB8 0x28A4 0x2912 0x29B0 0x2AF9 0x2BB3 0x2893 0x2912 0x29CA 0x2B0A 0x2B96 0x2886 0x2933 0x29DB 0x2B18 0x2B8E 0x2887 0x2953 0x29E7 0x2B20 0x2BDD 0x28A3 0x2965 0x29F8 0x2B2B 0x2C26 0x28BF 0x2974 0x2A19 0x2B52 0x2BDA 0x28CF 0x298A 0x2A3B 0x2B82 0x2B44 0x28DD 0x29A5 0x2A51 0x2B6C 0x2B2D 0x28EC 0x29C0 0x2A64 0x2AF8 0x2B64 0x28FC 0x29D9 0x2A84 0x2AC7 0x2BB4 0x290E 0x29F0 0x2ABC 0x2B12 0x2C59 0x2928 0x2A05 0x2AE8 0x2B78 0x2CF2 0x293F 0x2A19 0x2AF7 0x2BB8 0x2D0A 0x2941 0x2A1E 0x2B06 0x2BF2 0x2D12 0x293D 0x2A12 0x2B3F 0x2C58 0x2D20 0x293B 0x2A08 0x2BB8 0x2D19 0x2D38 0x293E 0x2A0A 0x2BDD 0x2D78 0x2D5A 0x2943 0x2A10 0x2B7B 0x2CF8 0x2DB7 0x2942 0x2A10 0x2B0C 0x2C5D 0x2E19 0x293F 0x29FF 0x2AD4 0x2C6F 0x2E16 0x293E 0x29F2 0x2AAD 0x2CBE 0x2DD7 0x2946 0x2A08 0x2ACD 0x2CCD 0x2D76 0x2950 0x2A2C 0x2B99 0x2C63 0x2C98 0x2950 0x2A35 0x2C0A 0x2BED 0x2BCD 0x294F 0x2A36 0x2B9E 0x2B9D 0x2B71 0x294F 0x2A37 0x2B1D 0x2B62 0x2B35 0x2957 0x2A2C 0x2B12 0x2B88 0x2B4A 0x2960 0x2A1E 0x2B12 0x2C49 0x2BF1 0x2960 0x2A1E 0x2B16 0x2CF6 0x2CD0 0x2960 0x2A26 0x2B4B 0x2D89 0x2E50 0x2960 0x2A2F 0x2B87 0x2DE1 0x2F7D 0x2963 0x2A35 0x2BB1 0x2DD9 0x2F71 0x2967 0x2A3D 0x2BD1 0x2DBE 0x2F23 0x296B 0x2A47 0x2BC4 0x2DA0 0x2E9C 0x2970 0x2A54 0x2B84 0x2D76 0x2D92 0x299E 0x2A62 0x2B76 0x2CB2 0x2D43 0x29A3 0x2AC2 0x2B7E 0x2BC0 0x2D27 0x2938 0x2B67 0x2BC6 0x2C0A 0x2CE1 0x26A1 0x2B4F 0x2BAC 0x2BFB 0x2D08 0x2657 0x2B19 0x2B71 0x2C12 0x2D05 0x2607 0x2AE5 0x2B48 0x2C45 0x2DD6 0x2749 0x2A95 0x2B39 0x2D01 0x2DB0 0x2D92 0x2A3C 0x2BFD 0x2BA9 0x2B5C 0xFFFF 0x29D4 0x2B90 0x2A63 0x2A5A 0xFFFF 0xFFFF 0x29FB 0x29F1 0x2A61 0x25EB 0x29E0 0x2967 0x2974 0x2A2F 0x25EB 0x29E0 0x2967 0x2974 0x2A2F 0x25EB 0x29E0 0x2967 0x2974 0x2A2F>;
                qcom,lut-row-legend = <0x2710 0x2648 0x2580 0x24B8 0x23F0 0x2328 0x2260 0x2198 0x20D0 0x2008 0x1F40 0x1E78 0x1DB0 0x1CE8 0x1C20 0x1B58 0x1A90 0x19C8 0x1900 0x1838 0x1770 0x16A8 0x15E0 0x1518 0x1450 0x1388 0x12C0 0x11F8 0x1130 0x1068 0xFA0 0xED8 0xE10 0xD48 0xC80 0xBB8 0xAF0 0xA28 0x960 0x898 0x7D0 0x708 0x640 0x578 0x4B0 0x3E8 0x384 0x320 0x2BC 0x258 0x1F4 0x190 0x12C 0xC8 0x64 0x0>;
            };
            qcom,pc-temp-z3-lut {
                qcom,lut-col-legend = <0x0 0xA 0x19 0x28 0x32>;
                qcom,lut-data = <0x4B3F 0x4B9A 0x4B91 0x4B79 0x4B76 0x4C76 0x4C40 0x4BD6 0x4B9E 0x4B7F 0x4CB9 0x4C64 0x4BF8 0x4B9A 0x4B7F 0x4CDE 0x4C6C 0x4C1A 0x4BCE 0x4BAB 0x4CEB 0x4C73 0x4C1F 0x4BD1 0x4BAF 0x4CF3 0x4C7A 0x4C1F 0x4BD1 0x4BB0 0x4CFA 0x4C7E 0x4C1C 0x4BCE 0x4BAF 0x4D02 0x4C7D 0x4C17 0x4BC8 0x4BAC 0x4D06 0x4C7A 0x4C0B 0x4BC2 0x4BA7 0x4D03 0x4C74 0x4BFD 0x4BBB 0x4B9D 0x4CFA 0x4C5E 0x4BF6 0x4BB4 0x4B99 0x4CF0 0x4C4C 0x4BF2 0x4BAD 0x4B99 0x4CE2 0x4C45 0x4BED 0x4BA6 0x4B98 0x4CD3 0x4C40 0x4BE3 0x4BA2 0x4B91 0x4CC7 0x4C37 0x4BD8 0x4B9E 0x4B83 0x4CBC 0x4C2C 0x4BD1 0x4B97 0x4B7E 0x4CB2 0x4C23 0x4BCB 0x4B89 0x4B7C 0x4CAB 0x4C1C 0x4BC4 0x4B81 0x4B7B 0x4CA3 0x4C18 0x4BB9 0x4B7E 0x4B79 0x4C99 0x4C16 0x4BB3 0x4B7C 0x4B76 0x4C91 0x4C15 0x4BB0 0x4B7A 0x4B73 0x4C91 0x4C15 0x4BAF 0x4B79 0x4B6F 0x4C97 0x4C1B 0x4BB6 0x4B7B 0x4B6F 0x4C9F 0x4C23 0x4BCC 0x4B88 0x4B71 0x4CB1 0x4C2A 0x4BD3 0x4B8F 0x4B73 0x4CC3 0x4C31 0x4BCA 0x4B80 0x4B69 0x4CC3 0x4C31 0x4BBD 0x4B6E 0x4B5A 0x4CBC 0x4C21 0x4BB2 0x4B6D 0x4B67 0x4CB4 0x4C15 0x4BA8 0x4B70 0x4B96 0x4CAD 0x4C15 0x4BA7 0x4B76 0x4BA7 0x4CA6 0x4C15 0x4BAE 0x4B93 0x4B9F 0x4CA1 0x4C17 0x4BB7 0x4BA7 0x4B93 0x4C9E 0x4C26 0x4BC9 0x4BA2 0x4B8A 0x4C9C 0x4C2F 0x4BDA 0x4B98 0x4B82 0x4C9C 0x4C2D 0x4BD8 0x4B92 0x4B7B 0x4C9C 0x4C29 0x4BCF 0x4B8D 0x4B74 0x4C9A 0x4C24 0x4BC6 0x4B89 0x4B72 0x4C96 0x4C1E 0x4BBE 0x4B87 0x4B76 0x4C91 0x4C18 0x4BB9 0x4B86 0x4B7A 0x4C8A 0x4C15 0x4BB8 0x4B87 0x4B7A 0x4C82 0x4C12 0x4BB8 0x4B8A 0x4B79 0x4C7A 0x4C09 0x4BB7 0x4B89 0x4B76 0x4C6F 0x4BFC 0x4BB5 0x4B85 0x4B6E 0x4C5E 0x4BF6 0x4BB3 0x4B7E 0x4B71 0x4BFF 0x4BE8 0x4BAF 0x4B78 0x4B78 0x4B8D 0x4BCF 0x4B9F 0x4B76 0x4B68 0x4B49 0x4BCE 0x4B9D 0x4B73 0x4B66 0x4B4A 0x4B87 0x4B96 0x4B6E 0x4B62 0x4B4D 0x4B71 0x4B83 0x4B69 0x4B57 0x4B74 0x4B71 0x4B7B 0x4B66 0x4B57 0x4C44 0x4BE4 0x4B6C 0x4B6D 0x4B71 0x4B41 0x4BF1 0x4B69 0x4B81 0x4B7D 0x4B3C 0x4B3F 0x4B7C 0x4B86 0x4B7F 0x52D4 0x51A7 0x4BC7 0x4B88 0x4B80 0x52D4 0x51A7 0x4BC7 0x4B88 0x4B80 0x52D4 0x51A7 0x4BC7 0x4B88 0x4B80>;
                qcom,lut-row-legend = <0x2710 0x2648 0x2580 0x24B8 0x23F0 0x2328 0x2260 0x2198 0x20D0 0x2008 0x1F40 0x1E78 0x1DB0 0x1CE8 0x1C20 0x1B58 0x1A90 0x19C8 0x1900 0x1838 0x1770 0x16A8 0x15E0 0x1518 0x1450 0x1388 0x12C0 0x11F8 0x1130 0x1068 0xFA0 0xED8 0xE10 0xD48 0xC80 0xBB8 0xAF0 0xA28 0x960 0x898 0x7D0 0x708 0x640 0x578 0x4B0 0x3E8 0x384 0x320 0x2BC 0x258 0x1F4 0x190 0x12C 0xC8 0x64 0x0>;
            };
            qcom,pc-temp-z4-lut {
                qcom,lut-col-legend = <0x0 0xA 0x19 0x28 0x32>;
                qcom,lut-data = <0x3C81 0x3B61 0x3A94 0x3A18 0x39F3 0x3E9F 0x3BD3 0x3A0E 0x399B 0x398B 0x3DA4 0x3C05 0x3A41 0x3985 0x3973 0x3C72 0x3B42 0x3A76 0x39E0 0x39AE 0x3BCC 0x3AC2 0x3A37 0x39C8 0x399D 0x3B4D 0x3A79 0x3A0B 0x39AF 0x398B 0x3AEE 0x3A43 0x39EE 0x399D 0x397F 0x3AA4 0x3A18 0x39D8 0x3990 0x3975 0x3A6B 0x39F7 0x39C8 0x398A 0x3973 0x3A40 0x39E0 0x39BB 0x3987 0x3973 0x3A1E 0x39CE 0x39AE 0x3983 0x3971 0x39FE 0x39C1 0x39A3 0x397F 0x3967 0x39DC 0x39B5 0x3999 0x397B 0x395E 0x39C7 0x39AB 0x3993 0x3973 0x395F 0x39BF 0x39A4 0x398C 0x396B 0x3962 0x39BA 0x399F 0x3983 0x3969 0x3961 0x39B5 0x399A 0x3979 0x3969 0x3958 0x39B0 0x3992 0x3972 0x3968 0x394F 0x39AB 0x398A 0x396D 0x3960 0x3946 0x39A7 0x3981 0x3968 0x3955 0x393F 0x39A3 0x3978 0x3960 0x394E 0x393C 0x399E 0x3975 0x3958 0x3948 0x3939 0x3997 0x3978 0x3966 0x394F 0x393F 0x3994 0x397F 0x399A 0x3983 0x3970 0x39BD 0x39A5 0x39C3 0x39B1 0x399E 0x39F3 0x39EB 0x39E2 0x39CA 0x39B5 0x39FD 0x39FE 0x39F3 0x39D9 0x39C3 0x3A00 0x39FA 0x39F2 0x39D6 0x39B1 0x3A00 0x39F3 0x39EE 0x39C9 0x3972 0x39F6 0x39E7 0x39E6 0x39B4 0x3955 0x39E7 0x39D5 0x39D1 0x3985 0x3951 0x39D9 0x39C0 0x39B8 0x3962 0x394F 0x39CC 0x39A5 0x3995 0x3959 0x394B 0x39C0 0x3993 0x3978 0x3954 0x3947 0x39B5 0x398C 0x3970 0x3951 0x3946 0x39AC 0x3987 0x396C 0x394F 0x3945 0x39A5 0x3983 0x396B 0x394F 0x3946 0x399F 0x397E 0x396A 0x3951 0x394C 0x3999 0x397C 0x396A 0x3954 0x3953 0x3993 0x397D 0x3974 0x395B 0x3953 0x398D 0x397E 0x3985 0x3962 0x3953 0x3986 0x397C 0x3985 0x3963 0x3953 0x3980 0x3975 0x397A 0x3960 0x3953 0x397B 0x396E 0x3977 0x3963 0x3951 0x39A5 0x3960 0x3973 0x3969 0x3949 0x39F5 0x3955 0x395C 0x394E 0x3944 0x3A3A 0x3956 0x3955 0x3945 0x3939 0x3A3B 0x399C 0x3948 0x3935 0x392B 0x3A39 0x39AD 0x394A 0x392A 0x3926 0x3A19 0x39AC 0x3955 0x393A 0x3932 0x399E 0x394D 0x3985 0x3944 0x3924 0x4312 0x3998 0x3999 0x3933 0x391B 0x43BE 0x4231 0x398C 0x3930 0x391C 0x3A45 0x3A7F 0x3946 0x3935 0x3922 0x3A45 0x3A7F 0x3946 0x3935 0x3922 0x3A45 0x3A7F 0x3946 0x3935 0x3922>;
                qcom,lut-row-legend = <0x2710 0x2648 0x2580 0x24B8 0x23F0 0x2328 0x2260 0x2198 0x20D0 0x2008 0x1F40 0x1E78 0x1DB0 0x1CE8 0x1C20 0x1B58 0x1A90 0x19C8 0x1900 0x1838 0x1770 0x16A8 0x15E0 0x1518 0x1450 0x1388 0x12C0 0x11F8 0x1130 0x1068 0xFA0 0xED8 0xE10 0xD48 0xC80 0xBB8 0xAF0 0xA28 0x960 0x898 0x7D0 0x708 0x640 0x578 0x4B0 0x3E8 0x384 0x320 0x2BC 0x258 0x1F4 0x190 0x12C 0xC8 0x64 0x0>;
            };
            qcom,pc-temp-z5-lut {
                qcom,lut-col-legend = <0x0 0xA 0x19 0x28 0x32>;
                qcom,lut-data = <0x2C87 0x31CD 0x34A1 0x37A5 0x3A57 0x37A5 0x4124 0x4867 0x4942 0x41CB 0x3C1C 0x41FD 0x4D49 0x54B4 0x4AF2 0x3FFD 0x450B 0x4AC2 0x5036 0x5294 0x42BB 0x4817 0x4D35 0x51BF 0x554C 0x44F4 0x4B53 0x4DDF 0x539A 0x5747 0x47B2 0x4E2B 0x4DB0 0x55C7 0x5A1F 0x4B66 0x5053 0x4D8E 0x5784 0x5C70 0x4EC2 0x5200 0x4D99 0x56E4 0x5B30 0x50C1 0x5279 0x4DB7 0x545E 0x556E 0x5266 0x5292 0x4EAC 0x522F 0x5332 0x557F 0x52BB 0x51B5 0x502C 0x57A5 0x5C14 0x54F8 0x52FA 0x4F1B 0x5BC5 0x6072 0x57F9 0x526F 0x501D 0x570C 0x60C9 0x583F 0x51EB 0x51BD 0x4DB1 0x60F9 0x57A4 0x5370 0x509E 0x4C38 0x61AB 0x5761 0x56B0 0x4B39 0x4F18 0x63AE 0x597C 0x5793 0x48E6 0x52D8 0x651F 0x5D61 0x57A3 0x4B1B 0x57B0 0x6566 0x61CB 0x57C2 0x4EE2 0x5CE8 0x659C 0x67D0 0x5B7B 0x5319 0x6160 0x6868 0x7035 0x6478 0x5913 0x6555 0x75C6 0x7F29 0x820D 0x64C1 0x667D 0x891D 0x8E51 0xC368 0x7EC1 0x66B5 0xB3D9 0x9915 0xD827 0x8C01 0x66C3 0xDE22 0xA1B8 0xACA3 0x70BC 0x5675 0xDA94 0x9FDE 0x7C3F 0x4D28 0x3FB7 0xBAF9 0x8194 0x65D6 0x4418 0x4483 0xA13C 0x67FE 0x5663 0x3FBE 0x5C7F 0x902E 0x6283 0x526F 0x4062 0x663E 0x8575 0x5F6B 0x5138 0x507C 0x66B6 0x84C3 0x62C0 0x511E 0x608B 0x6730 0x84F9 0x774C 0x64B3 0x66AD 0x68D0 0x85DC 0x8A16 0x8007 0x6B82 0x6B9B 0x8F78 0x960D 0x8BF1 0x7488 0x6E96 0x98C5 0x9E1C 0x93BE 0x8232 0x7204 0x9928 0x9E2D 0x9534 0x8739 0x76AF 0x98CF 0x9AEF 0x9063 0x8561 0x804F 0x97E9 0x96B8 0x88DF 0x81C4 0x87FD 0x92EC 0x913A 0x7D33 0x78E3 0x8049 0x8BDA 0x898E 0x6F54 0x6A6F 0x6BD4 0x8509 0x7AE3 0x6892 0x6171 0x5DC7 0x7CBD 0x69CB 0x64F0 0x5BF2 0x53FD 0x7285 0x6730 0x5F55 0x515B 0x544E 0x5330 0x68C0 0x5BE2 0x48EC 0x57A4 0x355B 0x6926 0x5E63 0x508B 0x4CB4 0x2EDB 0x645B 0x5B30 0x505C 0x507C 0x2E51 0x3C45 0x587D 0x5446 0x532B 0x2E18 0x34BF 0x4B88 0x5ABA 0x5167 0x308E 0x342B 0x439B 0x4AFB 0x4534 0xABE7 0xA69F 0x37A8 0x41E4 0x65BC 0x33C2 0x60FD 0x3373 0x50A0 0x88BC 0x27E1 0x292F 0x363B 0x5669 0x8F45 0x4AB4 0x3351 0x61AF 0x5577 0x854C 0x4AB4 0x3351 0x61AF 0x5577 0x854C 0x4AB4 0x3351 0x61AF 0x5577 0x854C>;
                qcom,lut-row-legend = <0x2710 0x2648 0x2580 0x24B8 0x23F0 0x2328 0x2260 0x2198 0x20D0 0x2008 0x1F40 0x1E78 0x1DB0 0x1CE8 0x1C20 0x1B58 0x1A90 0x19C8 0x1900 0x1838 0x1770 0x16A8 0x15E0 0x1518 0x1450 0x1388 0x12C0 0x11F8 0x1130 0x1068 0xFA0 0xED8 0xE10 0xD48 0xC80 0xBB8 0xAF0 0xA28 0x960 0x898 0x7D0 0x708 0x640 0x578 0x4B0 0x3E8 0x384 0x320 0x2BC 0x258 0x1F4 0x190 0x12C 0xC8 0x64 0x0>;
            };
            qcom,pc-temp-z6-lut {
                qcom,lut-col-legend = <0x0 0xA 0x19 0x28 0x32>;
                qcom,lut-data = <0x3B5C 0x39F6 0x3901 0x3886 0x3868 0x3CA8 0x3A6E 0x38F3 0x3870 0x384B 0x3C3C 0x3A8C 0x3913 0x3864 0x3841 0x3BB2 0x3A31 0x3938 0x38A3 0x3871 0x3B5D 0x39F3 0x391D 0x389A 0x386D 0x3B17 0x39CF 0x3908 0x3890 0x3867 0x3AE1 0x39B2 0x38F9 0x3887 0x3861 0x3AB7 0x399A 0x38EA 0x387E 0x385B 0x3A94 0x3985 0x38DC 0x3877 0x3856 0x3A74 0x3970 0x38CE 0x3872 0x3852 0x3A59 0x395B 0x38C5 0x386D 0x384E 0x3A3E 0x394B 0x38BD 0x3867 0x384A 0x3A22 0x3941 0x38B6 0x3861 0x3846 0x3A0E 0x3938 0x38AD 0x385C 0x3842 0x3A02 0x3930 0x38A5 0x3857 0x383D 0x39FA 0x3927 0x389D 0x3851 0x3838 0x39F3 0x391F 0x3896 0x384B 0x3834 0x39EC 0x3918 0x388F 0x3845 0x3830 0x39E6 0x3913 0x3888 0x3840 0x382B 0x39E0 0x390E 0x3882 0x383B 0x3827 0x39DB 0x390A 0x387E 0x3838 0x3824 0x39DB 0x3909 0x387B 0x3835 0x3821 0x39DC 0x390E 0x3885 0x383A 0x3823 0x39DF 0x3917 0x38A8 0x385A 0x383C 0x39FD 0x392E 0x38BC 0x386D 0x384E 0x3A20 0x3951 0x38C4 0x386F 0x3851 0x3A24 0x3959 0x38C7 0x386F 0x3853 0x3A23 0x3952 0x38C5 0x386E 0x3852 0x3A21 0x3949 0x38BE 0x386A 0x3851 0x3A1A 0x3943 0x38B9 0x3866 0x384E 0x3A11 0x393D 0x38B5 0x3862 0x3849 0x3A0A 0x3939 0x38B1 0x385E 0x3843 0x3A04 0x3935 0x38AE 0x3858 0x383D 0x3A00 0x3932 0x38AA 0x3852 0x3837 0x39FD 0x3930 0x38A6 0x384D 0x3833 0x39FB 0x392E 0x38A1 0x3849 0x382F 0x39F9 0x392B 0x389D 0x3847 0x382D 0x39F7 0x3926 0x389A 0x3848 0x3832 0x39F6 0x3925 0x3898 0x3849 0x3837 0x39F6 0x3926 0x389D 0x384C 0x3837 0x39F6 0x3928 0x38A6 0x3851 0x3837 0x39F5 0x3926 0x38A7 0x3852 0x3836 0x39F4 0x3921 0x38A2 0x384E 0x3832 0x39F2 0x391F 0x38A2 0x384E 0x3833 0x39E2 0x3919 0x38A1 0x384D 0x3835 0x39CF 0x390A 0x3891 0x3842 0x382A 0x39CD 0x390B 0x388D 0x383D 0x3825 0x39CE 0x3905 0x3885 0x3833 0x381C 0x39D1 0x3903 0x387D 0x382B 0x3814 0x39DA 0x3905 0x387E 0x3831 0x381A 0x3A0D 0x391A 0x388E 0x383C 0x3824 0x3D8B 0x3943 0x389A 0x3842 0x3828 0x3DE7 0x3CA2 0x38A4 0x3845 0x382B 0x3DDC 0x3D04 0x38B7 0x384B 0x3832 0x3DDC 0x3D04 0x38B7 0x384B 0x3832 0x3DDC 0x3D04 0x38B7 0x384B 0x3832>;
                qcom,lut-row-legend = <0x2710 0x2648 0x2580 0x24B8 0x23F0 0x2328 0x2260 0x2198 0x20D0 0x2008 0x1F40 0x1E78 0x1DB0 0x1CE8 0x1C20 0x1B58 0x1A90 0x19C8 0x1900 0x1838 0x1770 0x16A8 0x15E0 0x1518 0x1450 0x1388 0x12C0 0x11F8 0x1130 0x1068 0xFA0 0xED8 0xE10 0xD48 0xC80 0xBB8 0xAF0 0xA28 0x960 0x898 0x7D0 0x708 0x640 0x578 0x4B0 0x3E8 0x384 0x320 0x2BC 0x258 0x1F4 0x190 0x12C 0xC8 0x64 0x0>;
            };
        };
    };
    qcom_cp_manager {
        #io-channel-cells = <0x1>;
        compatible = "xiaomi,usbpd-pm";
        io-channel-names = "pd_active", "cp_input_suspend", "battery_charging_enabled", "present", "charging_enabled", "status", "sc_battery_present", "sc_vbus_present", "sc_battery_voltage", "sc_battery_current", "sc_battery_temperature", "sc_bus_voltage", "sc_bus_current", "sc_bus_temperature", "sc_die_temperature", "sc_alarm_status", "sc_fault_status", "sc_vbus_error_status", "sc_chip_vendor", "sc_chip_id", "sc_set_cp_workmode", "apdo_volt", "apdo_curr", "bq_present", "bq_charging_enabled", "bq_status", "bq_battery_present", "bq_vbus_present", "bq_battery_voltage", "bq_battery_current", "bq_battery_temperature", "bq_bus_voltage", "bq_bus_current", "bq_bus_temperature", "bq_die_temperature", "bq_alarm_status", "bq_fault_status", "bq_vbus_error_status", "bq_set_cp_workmode";
        io-channels = <&pm7250b_charger 0x4 &pm7250b_charger 0xB2 &pm7250b_charger 0xB3 &sc8541_standalone 0x90 &sc8541_standalone 0x76 &sc8541_standalone 0x8F &sc8541_standalone 0x92 &sc8541_standalone 0x93 &sc8541_standalone 0x94 &sc8541_standalone 0x95 &sc8541_standalone 0x96 &sc8541_standalone 0x97 &sc8541_standalone 0x98 &sc8541_standalone 0x99 &sc8541_standalone 0x9A &sc8541_standalone 0x9B &sc8541_standalone 0x91 &sc8541_standalone 0x9C &sc8541_standalone 0x9D &sc8541_standalone 0xAB &sc8541_standalone 0xE9 &pm7250b_charger 0xAC &pm7250b_charger 0xAD &bq25960_standalone 0x90 &bq25960_standalone 0x76 &bq25960_standalone 0x8F &bq25960_standalone 0x92 &bq25960_standalone 0x93 &bq25960_standalone 0x94 &bq25960_standalone 0x95 &bq25960_standalone 0x96 &bq25960_standalone 0x97 &bq25960_standalone 0x98 &bq25960_standalone 0x99 &bq25960_standalone 0x9A &bq25960_standalone 0x9B &bq25960_standalone 0x91 &bq25960_standalone 0x9C &bq25960_standalone 0xE9>;
        mi,pd-bat-curr-max = <0x1770>;
        mi,pd-bat-volt-max = <0x1194>;
        mi,pd-bus-curr-compensate = <0x64>;
        mi,pd-bus-curr-max = <0xBB8>;
        mi,pd-bus-volt-max = <0x2EE0>;
        mi,pd-ffc-bat-volt-max = <0x1194>;
        status = "ok";
    };
    st_stick {
        compatible = "st,stick";
        def-supply = <&maxim_ds28e30 &acl_slg>;
        status = "okay";
    };
    vdda_usb_ss_dp_core {
        compatible = "regulator-fixed";
        enable-active-high;
        gpio = <&pm6125_gpios 0x1 0x0>;
        pinctrl-0 = <&usb_eldo9>;
        pinctrl-names = "default";
        regulator-max-microvolt = <0xD6D80>;
        regulator-min-microvolt = <0xD6D80>;
        regulator-name = "vdd_supply";
    };
    xm_smart_chg {
        compatible = "xiaomi,xm_smart_chg";
        io-channel-names = "capacity", "pd_active", "capacity_raw";
        io-channels = <&pm7250b_qg 0x42 &pm7250b_charger 0x4 &pm7250b_qg 0x43>;
        label = "smart_charging";
        status = "ok";
        xiaomi,pd-thermal-mitigation = <0x5ACA30 0x5265C0 0x4C4B40 0x44AA20 0x3D0900 0x387520 0x3567E0 0x2DC6C0 0x2AB980 0x2625A0 0x1E8480 0x16E360 0xF4240 0xC3500 0x7A120 0x55730 0xC3500 0xC3500>;
        xiaomi,pd-thermal-mitigation-fast = <0x5B8D80 0x5ACA30 0x5ACA30 0x5265C0 0x4C4B40 0x44AA20 0x3D0900 0x387520 0x2AB980 0x2625A0 0x1E8480 0x16E360 0xF4240 0xC3500 0x7A120 0x55730 0xC3500 0xC3500>;
    };
};

&spmi_bus {
    #address-cells = <0x2>;
    #interrupt-cells = <0x4>;
    #size-cells = <0x0>;
    interrupt-controller;
    qcom,pm7250b@2 {
        #address-cells = <0x1>;
        #size-cells = <0x0>;
        compatible = "qcom,spmi-pmic";
        reg = <0x2 0x0>;
        pm7250b_adc_tm: adc_tm@3500 {
            #address-cells = <0x1>;
            #size-cells = <0x0>;
            #thermal-sensor-cells = <0x1>;
            compatible = "qcom,spmi-adc-tm5";
            interrupt-names = "pm-adc-tm5";
            interrupts = <0x2 0x35 0x0 0x1>;
            reg = <0x3500>;
            status = "ok";
            charger_skin_therm@4d {
                io-channels = <&pm7250b_vadc 0x4D>;
                qcom,hw-settle-time-us = <0xC8>;
                qcom,ratiometric;
                reg = <0x0>;
            };
            conn_therm@4f {
                io-channels = <&pm7250b_vadc 0x4F>;
                qcom,hw-settle-time-us = <0xC8>;
                qcom,ratiometric;
                reg = <0x1>;
            };
        };
        bcl_soc: bcl-soc {
            #thermal-sensor-cells = <0x0>;
            compatible = "qcom,msm-bcl-soc";
        };
        pm7250b_bcl: bcl@1d00 {
            #thermal-sensor-cells = <0x1>;
            compatible = "qcom,bcl-v5";
            interrupt-names = "bcl-lvl0", "bcl-lvl1", "bcl-lvl2";
            interrupts = <0x2 0x1D 0x0 0x0 0x2 0x1D 0x1 0x0 0x2 0x1D 0x2 0x0>;
            reg = <0x1D00>;
        };
        pm7250b_clkdiv: clock-controller@5b00 {
            #clock-cells = <0x1>;
            assigned-clock-rates = <0x124F800>;
            assigned-clocks = <&pm7250b_clkdiv 0x1>;
            clock-names = "xo";
            clock-output-names = "pm7250b_div_clk1";
            clocks = <&rpmcc 0x0>;
            compatible = "qcom,spmi-clkdiv";
            qcom,num-clkdivs = <0x1>;
            reg = <0x5B00>;
        };
        pm7250b_gpios: pinctrl@c000 {
            #gpio-cells = <0x2>;
            #interrupt-cells = <0x2>;
            compatible = "qcom,pm7250b-gpio";
            gpio-controller;
            interrupt-controller;
            reg = <0xC000>;
            disp_lcd_bias_en {
                disp_lcd_bias_en_default: disp_lcd_bias_en_default {
                    bias-disable;
                    function = "func1";
                    input-disable;
                    output-enable;
                    pins = "gpio5";
                    power-source = <0x0>;
                    qcom,drive-strength = <0x2>;
                };
            };
            pm7250b_smb_int_default: pm7250b_smb_int_default {
                bias-pull-up;
                function = "gpio";
                input-enable;
                pins = "gpio6";
                power-source = <0x0>;
                qcom,pull-up-strength = <0x0>;
            };
        };
        pm7250b_charger: qcom,qpnp-smb5 {
            #address-cells = <0x1>;
            #cooling-cells = <0x2>;
            #io-channel-cells = <0x1>;
            #size-cells = <0x1>;
            compatible = "qcom,pm7250b-smb5";
            depends-on-supply = <&pm7250b_vadc>;
            dpdm-supply = <&usb2_phy0>;
            io-channel-names = "usb_in_voltage", "usb_in_current", "chg_temp", "die_temp", "conn_temp", "sbux_res", "vph_voltage", "skin_temp", "resistance_id", "fastcharge_mode", "voltage_now", "temp", "capacity", "voltage_ocv", "voltage_avg", "debug_battery", "real_capacity", "cc_soc", "current_now", "voltage_max", "charge_full", "charge_counter", "cycle_count", "charge_full_design", "time_to_full_now", "ffc_chg_termination_current", "sc_bus_current", "sc_manufacturer", "auth_batt_id", "auth_authen_result", "auth_manufacturer", "auth_chip_ok", "bq_bus_current", "bq_manufacturer", "soc_decimal", "soc_decimal_rate", "shutdown_delay", "batt_full_current", "bq_set_acdrv", "recharg_mode";
            io-channels = <&pm7250b_vadc 0x8 &pm7250b_vadc 0x7 &pm7250b_vadc 0x9 &pm7250b_vadc 0x6 &pm7250b_vadc 0x4F &pm7250b_vadc 0x99 &pm7250b_vadc 0x83 &pm7250b_vadc 0x4D &pm7250b_qg 0x4B &pm7250b_qg 0xA2 &pm7250b_qg 0x46 &pm7250b_qg 0x45 &pm7250b_qg 0x42 &pm7250b_qg 0x47 &pm7250b_qg 0x5D &pm7250b_qg 0x4E &pm7250b_qg 0x44 &pm7250b_qg 0x5B &pm7250b_qg 0x48 &pm7250b_qg 0x2D &pm7250b_qg 0x53 &pm7250b_qg 0x49 &pm7250b_qg 0x52 &pm7250b_qg 0x54 &pm7250b_qg 0x56 &pm7250b_qg 0xC1 &sc8541_standalone 0x98 &sc8541_standalone 0x9D &auth_battery 0xB5 &auth_battery 0xB4 &auth_battery 0xB9 &auth_battery 0xBB &bq25960_standalone 0x98 &bq25960_standalone 0x9D &pm7250b_qg 0xA0 &pm7250b_qg 0xA1 &pm7250b_qg 0x9F &pm7250b_qg 0x50 &bq25960_standalone 0xC4 &pm7250b_charger 0xC5>;
            mi,support-ffc;
            mi,use_third_cp;
            qcom,auto-recharge-soc = <0x5F>;
            qcom,auto-recharge-vbat-mv = <0x64>;
            qcom,battery-data = <&mtp_batterydata>;
            qcom,charger-temp-max = <0x320>;
            qcom,chg-term-current-ma = <0xFFFFFF06>;
            qcom,disable-suspend-on-collapse;
            qcom,distinguish-qc-class-ab;
            qcom,en-skin-therm-mitigation;
            qcom,fcc-max-ua = <0x5B8D80>;
            qcom,fcc-step-delay-ms = <0x64>;
            qcom,fcc-step-size-ua = <0x186A0>;
            qcom,fcc-stepping-enable;
            qcom,fv-max-uv = <0x44AA20>;
            qcom,hvdcp2-12v-max-icl-ua = <0x16E360>;
            qcom,hvdcp2-max-icl-ua = <0x1E8480>;
            qcom,hvdcp3-standalone-config;
            qcom,sec-charger-config = <0x0>;
            qcom,smb-internal-pull-kohm = <0x0>;
            qcom,smb-temp-max = <0x320>;
            qcom,step-charging-enable;
            qcom,suspend-input-on-debug-batt;
            qcom,sw-jeita-enable;
            qcom,thermal-mitigation = <0x5ACA30 0x5265C0 0x4C4B40 0x44AA20 0x3D0900 0x387520 0x3567E0 0x2DC6C0 0x2AB980 0x2625A0 0x1E8480 0x16E360 0xF4240 0xC3500 0x7A120 0x55730 0xC3500 0xC3500>;
            status = "ok";
            qcom,batif@1200 {
                interrupt-names = "bat-temp", "bat-ov", "bat-low", "bat-therm-or-id-missing", "bat-terminal-missing", "buck-oc", "vph-ov";
                interrupts = <0x2 0x12 0x0 0x1 0x2 0x12 0x2 0x3 0x2 0x12 0x3 0x3 0x2 0x12 0x4 0x3 0x2 0x12 0x5 0x3 0x2 0x12 0x6 0x3 0x2 0x12 0x7 0x3>;
                reg = <0x1200>;
            };
            qcom,chg-sdam@b000 {
                reg = <0xB000>;
            };
            qcom,chgr@1000 {
                interrupt-names = "chgr-error", "chg-state-change", "step-chg-state-change", "step-chg-soc-update-fail", "step-chg-soc-update-req", "fg-fvcal-qualified", "vph-alarm", "vph-drop-prechg";
                interrupts = <0x2 0x10 0x0 0x1 0x2 0x10 0x1 0x1 0x2 0x10 0x2 0x1 0x2 0x10 0x3 0x1 0x2 0x10 0x4 0x1 0x2 0x10 0x5 0x1 0x2 0x10 0x6 0x1 0x2 0x10 0x7 0x1>;
                reg = <0x1000>;
            };
            qcom,dc@1400 {
                interrupt-names = "dcin-vashdn", "dcin-uv", "dcin-ov", "dcin-plugin", "dcin-revi", "dcin-pon", "dcin-en";
                interrupts = <0x2 0x14 0x1 0x3 0x2 0x14 0x2 0x3 0x2 0x14 0x3 0x3 0x2 0x14 0x4 0x3 0x2 0x14 0x5 0x3 0x2 0x14 0x6 0x1 0x2 0x14 0x7 0x1>;
                reg = <0x1400>;
            };
            qcom,dcdc@1100 {
                interrupt-names = "otg-fail", "otg-oc-disable-sw", "otg-oc-hiccup", "bsm-active", "high-duty-cycle", "input-current-limiting", "concurrent-mode-disable", "switcher-power-ok";
                interrupts = <0x2 0x11 0x0 0x1 0x2 0x11 0x1 0x1 0x2 0x11 0x2 0x1 0x2 0x11 0x3 0x3 0x2 0x11 0x4 0x3 0x2 0x11 0x5 0x3 0x2 0x11 0x6 0x1 0x2 0x11 0x7 0x3>;
                reg = <0x1100>;
            };
            qcom,misc@1600 {
                interrupt-names = "wdog-snarl", "wdog-bark", "aicl-fail", "aicl-done", "smb-en", "imp-trigger", "temp-change", "temp-change-smb";
                interrupts = <0x2 0x16 0x0 0x1 0x2 0x16 0x1 0x1 0x2 0x16 0x2 0x1 0x2 0x16 0x3 0x1 0x2 0x16 0x4 0x3 0x2 0x16 0x5 0x1 0x2 0x16 0x6 0x1 0x2 0x16 0x7 0x1>;
                reg = <0x1600>;
            };
            smb5_vbus: qcom,smb5-vbus {
                regulator-name = "smb5-vbus";
            };
            smb5_vconn: qcom,smb5-vconn {
                regulator-name = "smb5-vconn";
            };
            qcom,typec@1500 {
                interrupt-names = "typec-or-rid-detect-change", "typec-vpd-detect", "typec-cc-state-change", "typec-vconn-oc", "typec-vbus-change", "typec-attach-detach", "typec-legacy-cable-detect", "typec-try-snk-src-detect";
                interrupts = <0x2 0x15 0x0 0x1 0x2 0x15 0x1 0x1 0x2 0x15 0x2 0x1 0x2 0x15 0x3 0x1 0x2 0x15 0x4 0x1 0x2 0x15 0x5 0x1 0x2 0x15 0x6 0x1 0x2 0x15 0x7 0x1>;
                reg = <0x1500>;
            };
            qcom,usb@1300 {
                interrupt-names = "usbin-collapse", "usbin-vashdn", "usbin-uv", "usbin-ov", "usbin-plugin", "usbin-revi-change", "usbin-src-change", "usbin-icl-change";
                interrupts = <0x2 0x13 0x0 0x3 0x2 0x13 0x1 0x3 0x2 0x13 0x2 0x3 0x2 0x13 0x3 0x3 0x2 0x13 0x4 0x3 0x2 0x13 0x5 0x3 0x2 0x13 0x6 0x1 0x2 0x13 0x7 0x1>;
                reg = <0x1300>;
            };
        };
        pm7250b_tz: qcom,temp-alarm@2400 {
            #thermal-sensor-cells = <0x0>;
            compatible = "qcom,spmi-temp-alarm";
            interrupts = <0x2 0x24 0x0 0x3>;
            io-channel-names = "thermal";
            io-channels = <&pm7250b_vadc 0x6>;
            qcom,temperature-threshold-set = <0x1>;
            reg = <0x2400>;
        };
        pm7250b_pdphy: qcom,usb-pdphy@1700 {
            #io-channel-cells = <0x1>;
            compatible = "qcom,qpnp-pdphy";
            interrupt-names = "sig-tx", "sig-rx", "msg-tx", "msg-rx", "msg-tx-failed", "msg-tx-discarded", "msg-rx-discarded", "fr-swap";
            interrupts = <0x2 0x17 0x0 0x1 0x2 0x17 0x1 0x1 0x2 0x17 0x2 0x1 0x2 0x17 0x3 0x1 0x2 0x17 0x4 0x1 0x2 0x17 0x5 0x1 0x2 0x17 0x6 0x1 0x2 0x17 0x7 0x1>;
            io-channel-names = "pd_active", "typec_cc_orientation", "connector_type", "typec_power_role", "pd_usb_suspend_supported", "typec_src_rp", "pd_in_hard_reset", "pr_current_max", "pr_swap", "pd_voltage_min", "pd_voltage_max", "real_type", "typec_mode", "pe_start";
            io-channels = <&pm7250b_charger 0x4 &pm7250b_charger 0x3 &pm7250b_charger 0xD &pm7250b_charger 0x2 &pm7250b_charger 0x1F &pm7250b_charger 0x1D &pm7250b_charger 0x1E &pm7250b_charger 0x0 &pm7250b_charger 0x20 &pm7250b_charger 0xC &pm7250b_charger 0xB &pm7250b_charger 0xA &pm7250b_charger 0x1 &pm7250b_charger 0x7>;
            mi,limit_pd_unverified_pps_vbus = <0x1>;
            mi,pd_curr_limit = <0x1>;
            mi,pd_max_curr_limit = "=\t";
            mi,pd_unverified_pps_max_vbus_limit = <0x90F560>;
            qcom,default-sink-caps = <0x1388 0xBB8 0x2328 0xBB8 0x2EE0 0x8CA>;
            reg = <0x1700>;
            vbus-supply = <&smb5_vbus>;
            vconn-supply = <&smb5_vconn>;
            vdd-pdphy-supply = <&L15A>;
        };
        pm7250b_qg: qpnp,qg {
            #address-cells = <0x1>;
            #io-channel-cells = <0x1>;
            #size-cells = <0x1>;
            compatible = "qcom,pm7250b-qg";
            depends-on-supply = <&pm6125_rtc>;
            io-channel-names = "batt-therm", "batt-id", "input_current_limited", "recharge_soc", "force_recharge", "charge_done", "charging_enabled", "sc_battery_voltage", "bq_charging_enabled", "bq_battery_voltage", "real_type";
            io-channels = <&pm7250b_vadc 0x2A &pm7250b_vadc 0x4B &pm7250b_charger 0x37 &pm7250b_charger 0x3F &pm7250b_charger 0x40 &pm7250b_charger 0x39 &sc8541_standalone 0x76 &sc8541_standalone 0x94 &bq25960_standalone 0x76 &bq25960_standalone 0x94 &pm7250b_charger 0xA>;
            qcom,bass-enable;
            qcom,battery-data = <&mtp_batterydata>;
            qcom,cl-feedback-on;
            qcom,fvss-enable;
            qcom,fvss-vbatt-mv = <0xE10>;
            qcom,hold-soc-while-full;
            qcom,linearize-soc;
            qcom,qg-ext-sns;
            qcom,qg-iterm-ma = <0x12C>;
            qcom,s3-entry-fifo-length = <0x2>;
            qcom,s3-entry-ibat-ua = <0x61A8>;
            qcom,s3-exit-ibat-ua = <0xAFC8>;
            qcom,shutdown-delay-enable;
            qcom,soc_decimal_rate = <0x0 0x20 0xA 0x1E 0x14 0x1C 0x1E 0x1C 0x28 0x1C 0x32 0x1C 0x3C 0x1C 0x46 0x1C 0x50 0x1C 0x5A 0x1A 0x5F 0xA 0x63 0x5>;
            qcom,tcss-enable;
            qcom,vbatt-cutoff-mv = <0xD48>;
            qcom,vbatt-empty-cold-mv = <0xBB8>;
            qcom,vbatt-empty-mv = <0xBB8>;
            qcom,vbatt-low-cold-mv = <0xED8>;
            qcom,vbatt-low-mv = <0xDAC>;
            status = "ok";
            qcom,qg-sdam@b100 {
                reg = <0xB100>;
                status = "okay";
            };
            qcom,qgauge@4800 {
                interrupt-names = "qg-batt-missing", "qg-vbat-low", "qg-vbat-empty", "qg-fifo-done", "qg-good-ocv";
                interrupts = <0x2 0x48 0x0 0x3 0x2 0x48 0x1 0x3 0x2 0x48 0x2 0x1 0x2 0x48 0x3 0x1 0x2 0x48 0x4 0x1>;
                reg = <0x4800>;
                status = "okay";
            };
        };
        pm7250b_vadc: vadc@3100 {
            #address-cells = <0x1>;
            #io-channel-cells = <0x1>;
            #size-cells = <0x0>;
            compatible = "qcom,spmi-adc5";
            interrupt-names = "eoc-int-en-set";
            interrupts = <0x2 0x31 0x0 0x1>;
            io-channel-ranges;
            qcom,adc-vdd-reference = <0x753>;
            reg = <0x3100>;
            reg-names = "adc5-usr-base";
            bat_id@4b {
                label = "bat_id";
                qcom,hw-settle-time = <0xC8>;
                qcom,pre-scaling = <0x1 0x1>;
                qcom,ratiometric;
                reg = <0x4B>;
            };
            bat_therm@4a {
                label = "bat_therm";
                qcom,hw-settle-time = <0xC8>;
                qcom,pre-scaling = <0x1 0x1>;
                qcom,ratiometric;
                reg = <0x4A>;
            };
            bat_therm_30k@2a {
                label = "bat_therm_30k";
                qcom,hw-settle-time = <0xC8>;
                qcom,pre-scaling = <0x1 0x1>;
                qcom,ratiometric;
                reg = <0x2A>;
            };
            bat_therm_400k@6a {
                label = "bat_therm_400k";
                qcom,hw-settle-time = <0xC8>;
                qcom,pre-scaling = <0x1 0x1>;
                qcom,ratiometric;
                reg = <0x6A>;
            };
            charger_skin_therm@4d {
                label = "charger_skin_therm";
                qcom,hw-settle-time = <0xC8>;
                qcom,pre-scaling = <0x1 0x1>;
                qcom,ratiometric;
                reg = <0x4D>;
            };
            chg_sbux@99 {
                label = "chg_sbux";
                qcom,pre-scaling = <0x1 0x3>;
                reg = <0x99>;
            };
            chg_temp@9 {
                label = "chg_temp";
                qcom,pre-scaling = <0x1 0x1>;
                reg = <0x9>;
            };
            conn_therm@4f {
                label = "conn_therm";
                qcom,hw-settle-time = <0xC8>;
                qcom,pre-scaling = <0x1 0x1>;
                qcom,ratiometric;
                reg = <0x4F>;
            };
            die_temp@2 {
                label = "die_temp";
                qcom,pre-scaling = <0x1 0x1>;
                reg = <0x6>;
            };
            mid_chg_div6@1e {
                label = "chg_mid";
                qcom,pre-scaling = <0x1 0x6>;
                reg = <0x1E>;
            };
            ref_gnd@0 {
                label = "ref_gnd";
                qcom,pre-scaling = <0x1 0x1>;
                reg = <0x0>;
            };
            smb1390_therm@e {
                label = "smb1390_therm";
                qcom,hw-settle-time = <0xC8>;
                qcom,pre-scaling = <0x1 0x1>;
                reg = <0xE>;
            };
            usb_in_i_uv@7 {
                label = "usb_in_i_uv";
                qcom,pre-scaling = <0x1 0x1>;
                reg = <0x7>;
            };
            usb_in_v_div_16@8 {
                label = "usb_in_v_div_16";
                qcom,pre-scaling = <0x1 0x10>;
                reg = <0x8>;
            };
            vbat_sns@84 {
                label = "vbat_sns";
                qcom,pre-scaling = <0x1 0x3>;
                reg = <0x84>;
            };
            vph_pwr@83 {
                label = "vph_pwr";
                qcom,pre-scaling = <0x1 0x3>;
                reg = <0x83>;
            };
            vref_1p25@1 {
                label = "vref_1p25";
                qcom,pre-scaling = <0x1 0x1>;
                reg = <0x1>;
            };
        };
    };
    qcom,pm7250b@3 {
        #address-cells = <0x1>;
        #size-cells = <0x0>;
        compatible = "qcom,spmi-pmic";
        reg = <0x3 0x0>;
        pm7250b_vib: qcom,vibrator@5300 {
            compatible = "qcom,qpnp-vibrator-ldo";
            qcom,disable-overdrive;
            qcom,vib-ldo-volt-uv = <0x2DC6C0>;
            reg = <0x5300>;
        };
    };
};

&thermal_zones {
    charger-therm-usr {
        polling-delay = <0x0>;
        polling-delay-passive = <0x0>;
        thermal-governor = "user_space";
        thermal-sensors = <&pm7250b_adc_tm 0x0>;
        wake-capable-sensor;
        trips {
            active-config0 {
                hysteresis = <0x3E8>;
                temperature = <0x1E848>;
                type = "passive";
            };
        };
    };
    conn-therm-usr {
        polling-delay = <0x0>;
        polling-delay-passive = <0x0>;
        thermal-governor = "user_space";
        thermal-sensors = <&pm7250b_adc_tm 0x1>;
        wake-capable-sensor;
        trips {
            active-config0 {
                hysteresis = <0x3E8>;
                temperature = <0x1E848>;
                type = "passive";
            };
        };
    };
    pm6125-tz {
        cooling-maps {
            trip0_cpu0 {
                cooling-device = <&CPU0 0x7 0x7>;
                trip = <&pm6125_trip0>;
            };
            trip0_cpu4 {
                cooling-device = <&CPU4 0x6 0xFFFFFFFF>;
                trip = <&pm6125_trip0>;
            };
            trip1_cpu1 {
                cooling-device = <&cpu1_pause 0x1 0x1>;
                trip = <&pm6125_trip1>;
            };
            trip1_cpu2 {
                cooling-device = <&cpu2_pause 0x1 0x1>;
                trip = <&pm6125_trip1>;
            };
            trip1_cpu3 {
                cooling-device = <&cpu3_pause 0x1 0x1>;
                trip = <&pm6125_trip1>;
            };
            trip1_cpu4 {
                cooling-device = <&cpu4_pause 0x1 0x1>;
                trip = <&pm6125_trip1>;
            };
            trip1_cpu5 {
                cooling-device = <&cpu5_pause 0x1 0x1>;
                trip = <&pm6125_trip1>;
            };
            trip1_cpu6 {
                cooling-device = <&cpu6_pause 0x1 0x1>;
                trip = <&pm6125_trip1>;
            };
            trip1_cpu7 {
                cooling-device = <&cpu7_pause 0x1 0x1>;
                trip = <&pm6125_trip1>;
            };
        };
    };
    pm7250b-bcl-lvl0 {
        polling-delay = <0x0>;
        polling-delay-passive = <0x64>;
        thermal-sensors = <&pm7250b_bcl 0x5>;
        trips {
            b-bcl-lvl0 {
                hysteresis = <0x1>;
                temperature = <0x1>;
                type = "passive";
            };
        };
        cooling-maps {
            lbat0_cdsp {
                cooling-device = <&cdsp_sw 0x2 0x2>;
                trip = <&b_bcl_lvl0>;
            };
            lbat0_cpu6 {
                cooling-device = <&cpu6_pause 0x1 0x1>;
                trip = <&b_bcl_lvl0>;
            };
            lbat0_cpu7 {
                cooling-device = <&cpu7_pause 0x1 0x1>;
                trip = <&b_bcl_lvl0>;
            };
            lbat0_cpufreq4 {
                cooling-device = <&CPU4 0x2 0x2>;
                trip = <&b_bcl_lvl0>;
            };
            lbat0_gpu {
                cooling-device = <&msm_gpu 0x2 0x2>;
                trip = <&b_bcl_lvl0>;
            };
        };
    };
    pm7250b-bcl-lvl1 {
        polling-delay = <0x0>;
        polling-delay-passive = <0x64>;
        thermal-sensors = <&pm7250b_bcl 0x6>;
        trips {
            b-bcl-lvl1 {
                hysteresis = <0x1>;
                temperature = <0x1>;
                type = "passive";
            };
        };
        cooling-maps {
            lbat1_cdsp {
                cooling-device = <&cdsp_sw 0x4 0x4>;
                trip = <&b_bcl_lvl1>;
            };
            lbat1_cpu4 {
                cooling-device = <&cpu4_pause 0x1 0x1>;
                trip = <&b_bcl_lvl1>;
            };
            lbat1_cpu5 {
                cooling-device = <&cpu5_pause 0x1 0x1>;
                trip = <&b_bcl_lvl1>;
            };
            lbat1_gpu {
                cooling-device = <&msm_gpu 0x4 0x4>;
                trip = <&b_bcl_lvl1>;
            };
        };
    };
    pm7250b-bcl-lvl2 {
        polling-delay = <0x0>;
        polling-delay-passive = <0x64>;
        thermal-sensors = <&pm7250b_bcl 0x7>;
        trips {
            b-bcl-lvl2 {
                hysteresis = <0x1>;
                temperature = <0x1>;
                type = "passive";
            };
        };
        cooling-maps {
            lbat2_cdsp {
                cooling-device = <&cdsp_sw 0x4 0x4>;
                trip = <&b_bcl_lvl2>;
            };
            lbat2_gpu {
                cooling-device = <&msm_gpu 0x4 0xFFFFFFFF>;
                trip = <&b_bcl_lvl2>;
            };
        };
    };
    pm7250b-ibat-lvl0 {
        polling-delay = <0x0>;
        polling-delay-passive = <0x0>;
        thermal-sensors = <&pm7250b_bcl 0x0>;
        trips {
            ibat-lvl0 {
                hysteresis = <0xC8>;
                temperature = <0x157C>;
                type = "passive";
            };
        };
    };
    pm7250b-ibat-lvl1 {
        polling-delay = <0x0>;
        polling-delay-passive = <0x0>;
        thermal-sensors = <&pm7250b_bcl 0x1>;
        trips {
            ibat-lvl1 {
                hysteresis = <0xC8>;
                temperature = <0x1770>;
                type = "passive";
            };
        };
    };
    pm7250b-tz {
        polling-delay = <0x0>;
        polling-delay-passive = <0x64>;
        thermal-sensors = <&pm7250b_tz>;
        trips {
            trip0 {
                hysteresis = <0x0>;
                temperature = <0x17318>;
                type = "passive";
            };
            trip1 {
                hysteresis = <0x0>;
                temperature = <0x1C138>;
                type = "passive";
            };
            trip2 {
                hysteresis = <0x0>;
                temperature = <0x23668>;
                type = "passive";
            };
        };
        cooling-maps {
            trip0_bat {
                cooling-device = <&pm7250b_charger 0x9 0x9>;
                trip = <&pm7250b_trip0>;
            };
            trip1_bat {
                cooling-device = <&pm7250b_charger 0xA 0xA>;
                trip = <&pm7250b_trip1>;
            };
        };
    };
    rf-pa1-therm-usr {
        polling-delay = <0x0>;
        polling-delay-passive = <0x0>;
        thermal-governor = "user_space";
        thermal-sensors = <&pm6125_adc_tm 0x3>;
        wake-capable-sensor;
        trips {
            active-config0 {
                hysteresis = <0x3E8>;
                temperature = <0x1E848>;
                type = "passive";
            };
        };
    };
    socd {
        polling-delay = <0x0>;
        polling-delay-passive = <0x64>;
        trips {
            soc-trip {
                hysteresis = <0x0>;
                temperature = <0x5A>;
                type = "passive";
            };
            thermal-engine-trip {
                hysteresis = <0x0>;
                temperature = <0x64>;
                type = "passive";
            };
            thermal-hal-trip {
                hysteresis = <0x0>;
                temperature = <0x64>;
                type = "passive";
            };
        };
        cooling-maps {
            soc_cpu4 {
                cooling-device = <&cpu4_pause 0x1 0x1>;
                trip = <&soc_trip>;
            };
            soc_cpu5 {
                cooling-device = <&cpu5_pause 0x1 0x1>;
                trip = <&soc_trip>;
            };
            soc_cpu6 {
                cooling-device = <&cpu6_pause 0x1 0x1>;
                trip = <&soc_trip>;
            };
            soc_cpu7 {
                cooling-device = <&cpu7_pause 0x1 0x1>;
                trip = <&soc_trip>;
            };
        };
    };
};

&tlmm {
    fingerprints_eint_default: fingerprints_eint_default {
        config {
            bias-disable;
            drive-strength = <0x2>;
            pins = "gpio83";
        };
        mux {
            function = "gpio";
            pins = "gpio83";
        };
    };
    fingerprints_eint_pulldown: fingerprints_eint_pulldown {
        config {
            bias-pull-down;
            drive-strength = <0x2>;
            pins = "gpio83";
        };
        mux {
            function = "gpio";
            pins = "gpio83";
        };
    };
    fingerprints_pwr_high: fingerprints_pwr_high {
        config {
            bias-disable;
            drive-strength = <0x2>;
            output-high;
            pins = "gpio65";
        };
        mux {
            function = "gpio";
            pins = "gpio65";
        };
    };
    fingerprints_pwr_low: fingerprints_pwr_low {
        config {
            bias-disable;
            drive-strength = <0x2>;
            output-high;
            pins = "gpio65";
        };
        mux {
            function = "gpio";
            pins = "gpio65";
        };
    };
    fingerprints_reset_high: fingerprints_reset_high {
        config {
            bias-disable;
            drive-strength = <0x2>;
            output-high;
            pins = "gpio104";
        };
        mux {
            function = "gpio";
            pins = "gpio104";
        };
    };
    fingerprints_reset_low: fingerprints_reset_low {
        config {
            bias-disable;
            drive-strength = <0x2>;
            output-low;
            pins = "gpio104";
        };
        mux {
            function = "gpio";
            pins = "gpio104";
        };
    };
    onewire_gpio_active {
        config {
            bias-pull-up;
            drive-strength = <0x10>;
            pins = "gpio66";
        };
        mux {
            function = "gpio";
            pins = "gpio66";
        };
    };
    onewire_gpio_sleep {
        config {
            bias-pull-up;
            drive-strength = <0x10>;
            pins = "gpio66";
        };
        mux {
            function = "gpio";
            pins = "gpio66";
        };
    };
};

&ufshc_mem {
    qcom,vddp-ref-clk-max-microamp = <0x64>;
    qcom,vddp-ref-clk-supply = <&L18A>;
    reset-gpios = <&tlmm 0x71 0x1>;
    reset-names = "rst";
    resets = <&gcc 0x4>;
    status = "ok";
    vcc-max-microamp = "\f5";
    vcc-supply = <&L24A>;
    vccq2-max-microamp = "\f5";
    vccq2-supply = <&L11A>;
    vdd-hba-fixed-regulator;
    vdd-hba-supply = <&gcc_ufs_phy_gdsc>;
};

&ufsphy_mem {
    compatible = "qcom,ufs-phy-qmp-v4-khaje";
    status = "ok";
    vdda-phy-max-microamp = <0x14EC4>;
    vdda-phy-supply = <&L4A>;
    vdda-pll-max-microamp = <0x477C>;
    vdda-pll-supply = <&L18A>;
};

&usb0 {
    extcon = <&pm7250b_pdphy &pm7250b_charger &eud>;
};

&usb_qmp_dp_phy {
    vdd-supply = <&vdda_usb_ss_dp_core>;
};

